VERSION "HIPBNNNYNNNNNNNNNNNNNNNNNNNNNNNNNNYYNNNNNN/4>%%%/4/'%**4NNN///"

NS_ :

BS_:

BU_: ADC CDC DDM VNC Vector_XXX

BO_ 472 ABG1S04: 32 DDM
 SG_ SCSVNR : 19|2@0+ (1,0) [0|0] "-"  CDC
 SG_ VNUSGSCS : 17|1@0+ (1,0) [0|0] "-"  CDC

BO_ 470 ABG1S09: 32 DDM
 SG_ FLGXMAX : 47|8@0- (0.125,0) [0|0] "G"  CDC
 SG_ FLVNMAX : 76|5@0- (0.5,0) [0|0] "m/s"  CDC
 SG_ FRGMAX_L : 87|8@0- (0.2,0) [0|0] "G"  CDC
 SG_ FRGMAX_R : 95|8@0- (0.2,0) [0|0] "G"  CDC
 SG_ PT_ON : 147|2@0+ (1,0) [0|0] "-"  CDC
 SG_ FRAB_ON : 145|2@0+ (1,0) [0|0] "-"  CDC

BO_ 1428 ADC1S06: 32 ADC
 SG_ USMDC1 : 7|8@0+ (5,0) [0|0] "m"  CDC
 SG_ USMDC2 : 15|8@0+ (5,0) [0|0] "m"  CDC
 SG_ USMDC3 : 23|8@0+ (5,0) [0|0] "m"  CDC
 SG_ USMDC5 : 31|8@0+ (5,0) [0|0] "m"  CDC
 SG_ USMDC6 : 39|8@0+ (5,0) [0|0] "m"  CDC
 SG_ USMDRQAC : 47|8@0+ (5,0) [0|0] "m"  CDC
 SG_ USMDC7 : 55|5@0+ (5,0) [0|0] "m"  CDC
 SG_ USMNAV : 50|3@0+ (1,0) [0|0] "-"  CDC

BO_ 497 ADC1S08: 32 ADC
 SG_ HNPAVABL : 7|1@0+ (1,0) [0|0] "-"  CDC
 SG_ UNPAVABL : 6|1@0+ (1,0) [0|0] "-"  CDC
 SG_ FCWAVABL : 4|1@0+ (1,0) [0|0] "-"  CDC
 SG_ ELKAVABL : 3|1@0+ (1,0) [0|0] "-"  CDC
 SG_ CDWAVABL : 2|1@0+ (1,0) [0|0] "-"  CDC
 SG_ SLFAVABL : 1|1@0+ (1,0) [0|0] "-"  CDC
 SG_ TLAAVABL : 0|1@0+ (1,0) [0|0] "-"  CDC
 SG_ ESSAVABL : 15|1@0+ (1,0) [0|0] "-"  CDC
 SG_ CSWAVABL : 14|1@0+ (1,0) [0|0] "-"  CDC
 SG_ AESAVABL : 13|1@0+ (1,0) [0|0] "-"  CDC
 SG_ CPAVABL : 12|1@0+ (1,0) [0|0] "-"  CDC
 SG_ LDKAVABL : 11|1@0+ (1,0) [0|0] "-"  CDC
 SG_ MNPAVABL : 10|1@0+ (1,0) [0|0] "-"  CDC

BO_ 323 ADC1S10: 32 ADC
 SG_ E_CRC143 : 7|16@0+ (1,0) [0|0] "-"  CDC
 SG_ E_CNT143 : 23|8@0+ (1,0) [0|0] "-"  CDC
 SG_ RCTBLV : 31|3@0+ (1,0) [0|0] "-"  CDC
 SG_ RCTBDIR : 28|3@0+ (1,0) [0|0] "-"  CDC
 SG_ AEBDR : 25|3@0+ (1,0) [0|0] "-"  CDC
 SG_ ELKMD : 38|3@0+ (1,0) [0|0] "-"  CDC
 SG_ ESSMD : 35|3@0+ (1,0) [0|0] "-"  CDC
 SG_ ESSDR : 32|3@0+ (1,0) [0|0] "-"  CDC
 SG_ AESST : 45|3@0+ (1,0) [0|0] "-"  CDC
 SG_ AESMD : 42|3@0+ (1,0) [0|0] "-"  CDC
 SG_ AESDR : 55|3@0+ (1,0) [0|0] "-"  CDC
 SG_ HWFNST : 63|16@0+ (1,0) [0|0] "-"  CDC
 SG_ ODDAPWRN : 79|16@0+ (1,0) [0|0] "-"  CDC
 SG_ FCWSTT : 95|3@0+ (1,0) [0|0] "-"  CDC
 SG_ FCWDIR : 92|3@0+ (1,0) [0|0] "-"  CDC
 SG_ FCWWRNMD : 89|6@0+ (1,0) [0|0] "-"  CDC
 SG_ RCTADIR : 99|3@0+ (1,0) [0|0] "-"  CDC
 SG_ CDWSTT : 96|3@0+ (1,0) [0|0] "-"  CDC
 SG_ CDWLV : 109|2@0+ (1,0) [0|0] "-"  CDC
 SG_ CDWWRN : 107|2@0+ (1,0) [0|0] "-"  CDC
 SG_ AESDIR : 105|3@0+ (1,0) [0|0] "-"  CDC
 SG_ RCPMSTT : 112|3@0+ (1,0) [0|0] "-"  CDC
 SG_ ESSSTT : 125|3@0+ (1,0) [0|0] "-"  CDC
 SG_ RCTASTT : 122|3@0+ (1,0) [0|0] "-"  CDC
 SG_ RCTBSTT : 135|3@0+ (1,0) [0|0] "-"  CDC
 SG_ LDWSTT : 132|3@0+ (1,0) [0|0] "-"  CDC
 SG_ LDKSTT : 129|3@0+ (1,0) [0|0] "-"  CDC
 SG_ ELKSTT : 142|3@0+ (1,0) [0|0] "-"  CDC
 SG_ TSRSTT : 139|3@0+ (1,0) [0|0] "-"  CDC
 SG_ IHCSTT : 136|3@0+ (1,0) [0|0] "-"  CDC
 SG_ BSDSTT : 149|3@0+ (1,0) [0|0] "-"  CDC
 SG_ LCASTT : 146|3@0+ (1,0) [0|0] "-"  CDC
 SG_ DOWSTT : 159|3@0+ (1,0) [0|0] "-"  CDC
 SG_ AEBSTT : 156|3@0+ (1,0) [0|0] "-"  CDC
 SG_ ABSMSTT : 153|3@0+ (1,0) [0|0] "-"  CDC
 SG_ AESSTT : 166|3@0+ (1,0) [0|0] "-"  CDC
 SG_ RCWSTT : 163|3@0+ (1,0) [0|0] "-"  CDC
 SG_ CSWSTT : 160|3@0+ (1,0) [0|0] "-"  CDC
 SG_ SLFSTT : 173|3@0+ (1,0) [0|0] "-"  CDC
 SG_ TLASTT : 170|9@0+ (1,0) [0|0] "-"  CDC
 SG_ LPAPFAIL : 177|1@0+ (1,0) [0|0] "-"  CDC
 SG_ LPNPFAIL : 187|1@0+ (1,0) [0|0] "-"  CDC
 SG_ LPNPSYS : 186|1@0+ (1,0) [0|0] "-"  CDC
 SG_ LPNPONST : 185|1@0+ (1,0) [0|0] "-"  CDC
 SG_ PNPEXBRK : 184|1@0+ (1,0) [0|0] "-"  CDC
 SG_ PNPFAIL : 194|1@0+ (1,0) [0|0] "-"  CDC
 SG_ PNPSYS : 193|1@0+ (1,0) [0|0] "-"  CDC
 SG_ PNPONST : 192|1@0+ (1,0) [0|0] "-"  CDC
 SG_ APPONST : 207|1@0+ (1,0) [0|0] "-"  CDC
 SG_ AP_LAMP : 206|2@0+ (1,0) [0|0] "-"  CDC
 SG_ DMCCALB : 204|2@0+ (1,0) [0|0] "-"  CDC
 SG_ LPNPEXBK : 202|1@0+ (1,0) [0|0] "-"  CDC
 SG_ LPNPLAMP : 201|2@0+ (1,0) [0|0] "-"  CDC
 SG_ LPNPSTS : 215|8@0+ (1,0) [0|0] "-"  CDC
 SG_ PNPSTS : 223|8@0+ (1,0) [0|0] "-"  CDC

BO_ 515 ADC1S12: 32 ADC
 SG_ GDNEXIST : 7|1@0+ (1,0) [0|0] "-"  CDC
 SG_ CNPFNEX : 4|1@0+ (1,0) [0|0] "-"  CDC
 SG_ FCWFNEX : 3|1@0+ (1,0) [0|0] "-"  CDC
 SG_ ELKFNEX : 2|1@0+ (1,0) [0|0] "-"  CDC
 SG_ SLFFNEX : 1|1@0+ (1,0) [0|0] "-"  CDC
 SG_ TLAFNEX : 0|1@0+ (1,0) [0|0] "-"  CDC
 SG_ BSDFNEX : 15|1@0+ (1,0) [0|0] "-"  CDC
 SG_ ESSFNEX : 14|1@0+ (1,0) [0|0] "-"  CDC
 SG_ CSWFNEX : 13|1@0+ (1,0) [0|0] "-"  CDC
 SG_ AESFNEX : 12|1@0+ (1,0) [0|0] "-"  CDC
 SG_ LDKFNEX : 11|1@0+ (1,0) [0|0] "-"  CDC
 SG_ CPFNEX : 10|1@0+ (1,0) [0|0] "-"  CDC
 SG_ CDWFNEX : 8|1@0+ (1,0) [0|0] "-"  CDC

BO_ 520 ADC1S14: 32 ADC
 SG_ E_CRC208 : 7|16@0+ (1,0) [0|0] "-"  CDC,DDM
 SG_ E_CNT208 : 23|8@0+ (1,0) [0|0] "-"  CDC,DDM
 SG_ ADBZRQ : 31|8@0+ (1,0) [0|0] "-"  CDC,DDM
 SG_ ADPRDTML : 39|1@0+ (1,0) [0|0] "-"  CDC,DDM
 SG_ ADMMMUTE : 38|1@0+ (1,0) [0|0] "-"  CDC,DDM
 SG_ ADADDREX : 37|1@0+ (1,0) [0|0] "-"  CDC,DDM
 SG_ ADOTASEX : 36|1@0+ (1,0) [0|0] "-"  CDC,DDM
 SG_ ADSTMUEX : 35|1@0+ (1,0) [0|0] "-"  CDC,DDM
 SG_ ADAUNFEX : 34|1@0+ (1,0) [0|0] "-"  CDC,DDM
 SG_ ADNTLVEX : 33|1@0+ (1,0) [0|0] "-"  CDC,DDM
 SG_ ADDSLVEX : 32|1@0+ (1,0) [0|0] "-"  CDC,DDM
 SG_ ADVOCTEX : 47|1@0+ (1,0) [0|0] "-"  CDC,DDM
 SG_ ADSLDSEX : 46|1@0+ (1,0) [0|0] "-"  CDC,DDM
 SG_ ADDMCREX : 45|1@0+ (1,0) [0|0] "-"  CDC,DDM
 SG_ ADSEGDEX : 44|2@0+ (1,0) [0|0] "-"  CDC,DDM
 SG_ ADSVSSEX : 41|1@0+ (1,0) [0|0] "-"  CDC,DDM
 SG_ ADCVVSEX : 40|1@0+ (1,0) [0|0] "-"  CDC,DDM
 SG_ ADADDRST : 53|2@0+ (1,0) [0|0] "-"  CDC,DDM
 SG_ ADOTASST : 51|2@0+ (1,0) [0|0] "-"  CDC,DDM
 SG_ ADSTMUST : 49|2@0+ (1,0) [0|0] "-"  CDC,DDM
 SG_ ADAUNFST : 63|2@0+ (1,0) [0|0] "-"  CDC,DDM
 SG_ ADNTLVST : 61|2@0+ (1,0) [0|0] "-"  CDC,DDM
 SG_ ADDSLVST : 59|2@0+ (1,0) [0|0] "-"  CDC,DDM
 SG_ ADVOCTST : 57|2@0+ (1,0) [0|0] "-"  CDC,DDM
 SG_ ADSLDSST : 71|2@0+ (1,0) [0|0] "-"  CDC,DDM
 SG_ ADDMCRST : 69|2@0+ (1,0) [0|0] "-"  CDC,DDM
 SG_ ADSEGDST : 67|2@0+ (1,0) [0|0] "-"  CDC,DDM
 SG_ ADSVSSST : 78|2@0+ (1,0) [0|0] "-"  CDC,DDM
 SG_ ADCVVSST : 76|4@0+ (1,0) [0|0] "-"  CDC,DDM
 SG_ ADDOTTT : 82|2@0+ (1,0) [0|0] "-"  CDC,DDM
 SG_ ADHOFEXT : 80|1@0+ (1,0) [0|0] "-"  CDC,DDM
 SG_ ADDOTRQ : 95|3@0+ (1,0) [0|0] "-"  CDC,DDM
 SG_ ADHONRQ : 92|3@0+ (1,0) [0|0] "-"  CDC,DDM
 SG_ ADADMTT : 89|3@0+ (1,0) [0|0] "-"  CDC,DDM
 SG_ ADHOFDSP : 102|3@0+ (1,0) [0|0] "-"  CDC,DDM
 SG_ ADTRJDSP : 99|3@0+ (1,0) [0|0] "-"  CDC,DDM
 SG_ ADLLIDSP : 96|3@0+ (1,0) [0|0] "-"  CDC,DDM
 SG_ ADRLIDSP : 109|3@0+ (1,0) [0|0] "-"  CDC,DDM
 SG_ MNPCUSST : 131|2@0+ (1,0) [0|0] "-"  CDC,DDM
 SG_ RCD_DE_C : 128|1@0+ (1,0) [0|0] "-"  CDC,DDM
 SG_ RCDDE_ST : 143|1@0+ (1,0) [0|0] "-"  CDC,DDM
 SG_ FR_BRGHT : 142|1@0+ (1,0) [0|0] "-"  CDC,DDM
 SG_ FR_DIRT2 : 141|1@0+ (1,0) [0|0] "-"  CDC,DDM
 SG_ FR_SNOW : 140|1@0+ (1,0) [0|0] "-"  CDC,DDM
 SG_ FR_RAIN : 139|1@0+ (1,0) [0|0] "-"  CDC,DDM
 SG_ FR_INVA : 138|1@0+ (1,0) [0|0] "-"  CDC,DDM
 SG_ FR_FAIL : 137|1@0+ (1,0) [0|0] "-"  CDC,DDM
 SG_ RR_BRGHT : 136|1@0+ (1,0) [0|0] "-"  CDC,DDM
 SG_ RR_DIRT2 : 151|1@0+ (1,0) [0|0] "-"  CDC,DDM
 SG_ RR_SNOW : 150|1@0+ (1,0) [0|0] "-"  CDC,DDM
 SG_ RR_RAIN : 149|1@0+ (1,0) [0|0] "-"  CDC,DDM
 SG_ RR_INVA : 148|1@0+ (1,0) [0|0] "-"  CDC,DDM
 SG_ RR_FAIL : 147|1@0+ (1,0) [0|0] "-"  CDC,DDM
 SG_ LH_BRGHT : 146|1@0+ (1,0) [0|0] "-"  CDC,DDM
 SG_ LH_DIRT : 145|1@0+ (1,0) [0|0] "-"  CDC,DDM
 SG_ LH_SNOW : 144|1@0+ (1,0) [0|0] "-"  CDC,DDM
 SG_ LH_RAIN : 159|1@0+ (1,0) [0|0] "-"  CDC,DDM
 SG_ LH_INVA : 158|1@0+ (1,0) [0|0] "-"  CDC,DDM
 SG_ LH_FAIL : 157|1@0+ (1,0) [0|0] "-"  CDC,DDM
 SG_ RH_BRGHT : 156|1@0+ (1,0) [0|0] "-"  CDC,DDM
 SG_ RH_DIRT : 155|1@0+ (1,0) [0|0] "-"  CDC,DDM
 SG_ RH_SNOW : 154|1@0+ (1,0) [0|0] "-"  CDC,DDM
 SG_ RH_RAIN : 153|1@0+ (1,0) [0|0] "-"  CDC,DDM
 SG_ RH_INVA : 152|1@0+ (1,0) [0|0] "-"  CDC,DDM
 SG_ RH_FAIL : 167|1@0+ (1,0) [0|0] "-"  CDC,DDM
 SG_ AIPWFR1 : 175|8@0+ (1,0) [0|0] "-"  CDC,DDM
 SG_ AIPWFR2 : 183|8@0+ (1,0) [0|0] "-"  CDC,DDM
 SG_ AIPREQ : 191|8@0+ (1,0) [0|0] "-"  CDC,DDM
 SG_ AIPRLAR : 199|1@0+ (1,0) [0|0] "-"  CDC,DDM
 SG_ AIPPROEX : 198|1@0+ (1,0) [0|0] "-"  CDC,DDM
 SG_ AIPPRORE : 197|5@0+ (1,0) [0|0] "-"  CDC,DDM

BO_ 521 ADC1S15: 32 ADC
 SG_ FCWCUSST : 7|2@0+ (1,0) [0|0] "-"  CDC
 SG_ CDWCUSST : 5|2@0+ (1,0) [0|0] "-"  CDC
 SG_ SLFCUSST : 3|2@0+ (1,0) [0|0] "-"  CDC
 SG_ TLACUSST : 1|2@0+ (1,0) [0|0] "-"  CDC
 SG_ BSDCUSST : 15|2@0+ (1,0) [0|0] "-"  CDC
 SG_ ESSCUSST : 13|2@0+ (1,0) [0|0] "-"  CDC
 SG_ CSWCUSST : 11|2@0+ (1,0) [0|0] "-"  CDC
 SG_ AESCUSST : 9|2@0+ (1,0) [0|0] "-"  CDC
 SG_ HNPCUSST : 23|2@0+ (1,0) [0|0] "-"  CDC
 SG_ UNPCUSST : 21|2@0+ (1,0) [0|0] "-"  CDC
 SG_ LDKCUSST : 17|2@0+ (1,0) [0|0] "-"  CDC
 SG_ ELKCUSST : 31|2@0+ (1,0) [0|0] "-"  CDC
 SG_ CPCUSST : 29|2@0+ (1,0) [0|0] "-"  CDC
 SG_ HNPCSTEX : 27|1@0+ (1,0) [0|0] "-"  CDC
 SG_ UNPCSTEX : 26|1@0+ (1,0) [0|0] "-"  CDC
 SG_ NPLCCSEX : 24|1@0+ (1,0) [0|0] "-"  CDC
 SG_ NPCS1EX : 39|1@0+ (1,0) [0|0] "-"  CDC
 SG_ NPCS2EX : 38|1@0+ (1,0) [0|0] "-"  CDC
 SG_ NPCS3EX : 37|1@0+ (1,0) [0|0] "-"  CDC
 SG_ NPCS4EX : 36|1@0+ (1,0) [0|0] "-"  CDC
 SG_ NPCS5EX : 35|1@0+ (1,0) [0|0] "-"  CDC
 SG_ NPCS6EX : 34|1@0+ (1,0) [0|0] "-"  CDC
 SG_ NPCS7EX : 33|1@0+ (1,0) [0|0] "-"  CDC
 SG_ NPCS8EX : 32|1@0+ (1,0) [0|0] "-"  CDC
 SG_ NPCS9EX : 47|1@0+ (1,0) [0|0] "-"  CDC
 SG_ NPCS10EX : 46|1@0+ (1,0) [0|0] "-"  CDC
 SG_ NPCS11EX : 45|1@0+ (1,0) [0|0] "-"  CDC
 SG_ NPCS12EX : 44|1@0+ (1,0) [0|0] "-"  CDC
 SG_ NPCS13EX : 43|1@0+ (1,0) [0|0] "-"  CDC
 SG_ NPCS14EX : 42|1@0+ (1,0) [0|0] "-"  CDC
 SG_ NPCS15EX : 41|1@0+ (1,0) [0|0] "-"  CDC
 SG_ NPCS16EX : 40|1@0+ (1,0) [0|0] "-"  CDC
 SG_ NPCS17EX : 55|1@0+ (1,0) [0|0] "-"  CDC
 SG_ NPCS18EX : 54|1@0+ (1,0) [0|0] "-"  CDC
 SG_ NPCS19EX : 53|1@0+ (1,0) [0|0] "-"  CDC
 SG_ NPCS20EX : 52|1@0+ (1,0) [0|0] "-"  CDC
 SG_ HNPCSST : 51|2@0+ (1,0) [0|0] "-"  CDC
 SG_ UNPCSST : 49|2@0+ (1,0) [0|0] "-"  CDC
 SG_ NPLCCSST : 61|2@0+ (1,0) [0|0] "-"  CDC
 SG_ NPCS1ST : 59|3@0+ (1,0) [0|0] "-"  CDC
 SG_ NPCS2ST : 56|2@0+ (1,0) [0|0] "-"  CDC
 SG_ NPCS3ST : 70|2@0+ (1,0) [0|0] "-"  CDC
 SG_ NPCS4ST : 68|2@0+ (1,0) [0|0] "-"  CDC
 SG_ NPCS5ST : 66|2@0+ (1,0) [0|0] "-"  CDC
 SG_ NPCS6ST : 64|2@0+ (1,0) [0|0] "-"  CDC
 SG_ NPCS7ST : 78|3@0+ (1,0) [0|0] "-"  CDC
 SG_ NPCS8ST : 75|5@0+ (1,0) [0|0] "-"  CDC
 SG_ NPCS9ST : 86|2@0+ (1,0) [0|0] "-"  CDC
 SG_ NPCS10ST : 84|3@0+ (1,0) [0|0] "-"  CDC
 SG_ NPCS11ST : 81|3@0+ (1,0) [0|0] "-"  CDC
 SG_ NPCS12ST : 94|2@0+ (1,0) [0|0] "-"  CDC
 SG_ NPCS13ST : 92|2@0+ (1,0) [0|0] "-"  CDC
 SG_ NPCS14ST : 90|2@0+ (1,0) [0|0] "-"  CDC
 SG_ NPCS15ST : 88|2@0+ (1,0) [0|0] "-"  CDC
 SG_ NPCS16ST : 102|2@0+ (1,0) [0|0] "-"  CDC
 SG_ NPCS17ST : 100|2@0+ (1,0) [0|0] "-"  CDC
 SG_ NPCS18ST : 98|2@0+ (1,0) [0|0] "-"  CDC
 SG_ NPCS19ST : 96|3@0+ (1,0) [0|0] "-"  CDC
 SG_ NPCS20ST : 109|3@0+ (1,0) [0|0] "-"  CDC
 SG_ GDNCTEX : 106|1@0+ (1,0) [0|0] "-"  CDC
 SG_ GDNCTST : 105|2@0+ (1,0) [0|0] "-"  CDC
 SG_ GDNWNEX : 119|1@0+ (1,0) [0|0] "-"  CDC
 SG_ GDNWNST : 118|2@0+ (1,0) [0|0] "-"  CDC
 SG_ GDNBKEX : 116|1@0+ (1,0) [0|0] "-"  CDC
 SG_ GDNBKST : 115|2@0+ (1,0) [0|0] "-"  CDC
 SG_ GDNSTEX : 113|1@0+ (1,0) [0|0] "-"  CDC
 SG_ GDNSTST : 112|2@0+ (1,0) [0|0] "-"  CDC
 SG_ GDNSNEX : 126|1@0+ (1,0) [0|0] "-"  CDC
 SG_ GDNSNST : 125|3@0+ (1,0) [0|0] "-"  CDC
 SG_ FCWCTEX : 122|1@0+ (1,0) [0|0] "-"  CDC
 SG_ FCWCTST : 121|2@0+ (1,0) [0|0] "-"  CDC
 SG_ FCWSEEX : 135|1@0+ (1,0) [0|0] "-"  CDC
 SG_ FCWSEST : 134|3@0+ (1,0) [0|0] "-"  CDC
 SG_ CDWCTEX : 131|1@0+ (1,0) [0|0] "-"  CDC
 SG_ CDWCTST : 130|2@0+ (1,0) [0|0] "-"  CDC
 SG_ TLACTEX : 128|1@0+ (1,0) [0|0] "-"  CDC
 SG_ TLACTST : 143|2@0+ (1,0) [0|0] "-"  CDC
 SG_ SLFCTEX : 141|1@0+ (1,0) [0|0] "-"  CDC
 SG_ SLFCTST : 140|2@0+ (1,0) [0|0] "-"  CDC
 SG_ CSWCTEX : 138|1@0+ (1,0) [0|0] "-"  CDC
 SG_ CSWCTST : 137|2@0+ (1,0) [0|0] "-"  CDC
 SG_ AESCTEX : 151|1@0+ (1,0) [0|0] "-"  CDC
 SG_ AESCTST : 150|2@0+ (1,0) [0|0] "-"  CDC
 SG_ ACCCTEX : 148|1@0+ (1,0) [0|0] "-"  CDC
 SG_ ACCCTST : 147|2@0+ (1,0) [0|0] "-"  CDC
 SG_ CPCTEX : 145|1@0+ (1,0) [0|0] "-"  CDC
 SG_ CPCTST : 144|2@0+ (1,0) [0|0] "-"  CDC
 SG_ LDKCTEX : 158|1@0+ (1,0) [0|0] "-"  CDC
 SG_ LDKCTST : 157|2@0+ (1,0) [0|0] "-"  CDC
 SG_ LDKSNEX : 155|1@0+ (1,0) [0|0] "-"  CDC
 SG_ LDKSNST : 154|2@0+ (1,0) [0|0] "-"  CDC
 SG_ ELKCTEX : 152|1@0+ (1,0) [0|0] "-"  CDC
 SG_ ELKCTST : 167|2@0+ (1,0) [0|0] "-"  CDC
 SG_ ELKMDEX : 165|1@0+ (1,0) [0|0] "-"  CDC
 SG_ ELKMDST : 164|3@0+ (1,0) [0|0] "-"  CDC
 SG_ BSDCTEX : 161|1@0+ (1,0) [0|0] "-"  CDC
 SG_ BSDCTST : 160|2@0+ (1,0) [0|0] "-"  CDC
 SG_ NPSSWEX : 190|1@0+ (1,0) [0|0] "-"  CDC
 SG_ NPSSWST : 189|1@0+ (1,0) [0|0] "-"  CDC
 SG_ RCPMCTEX : 188|1@0+ (1,0) [0|0] "-"  CDC
 SG_ RCPMCTST : 187|2@0+ (1,0) [0|0] "-"  CDC
 SG_ NPDSSWEX : 185|1@0+ (1,0) [0|0] "-"  CDC
 SG_ NPDSSWST : 184|1@0+ (1,0) [0|0] "-"  CDC
 SG_ ESSCTEX : 196|1@0+ (1,0) [0|0] "-"  CDC
 SG_ ESSCTST : 195|2@0+ (1,0) [0|0] "-"  CDC
 SG_ OVSPCEXT : 193|1@0+ (1,0) [0|0] "-"  CDC
 SG_ OVSPCVAL : 192|5@0+ (1,0) [0|0] "-"  CDC
 SG_ CRNGCUST : 202|2@0+ (1,0) [0|0] "-"  CDC
 SG_ CSRNGF : 215|1@0+ (1,0) [0|0] "-"  CDC
 SG_ CSRNGR : 213|1@0+ (1,0) [0|0] "-"  CDC
 SG_ WDISPCST : 211|1@0+ (1,0) [0|0] "-"  CDC
 SG_ WDISPSTT : 209|1@0+ (1,0) [0|0] "-"  CDC
 SG_ MOACUST : 223|1@0+ (1,0) [0|0] "-"  CDC
 SG_ MOASTAT : 221|1@0+ (1,0) [0|0] "-"  CDC
 SG_ MOAAOST : 219|1@0+ (1,0) [0|0] "-"  CDC
 SG_ MNPCSTEX : 218|1@0+ (1,0) [0|0] "-"  CDC
 SG_ MNPFNEX : 217|2@0+ (1,0) [0|0] "-"  CDC
 SG_ MNPSSWEX : 231|1@0+ (1,0) [0|0] "-"  CDC
 SG_ MNPSSWST : 230|1@0+ (1,0) [0|0] "-"  CDC
 SG_ HNPFNEX : 229|1@0+ (1,0) [0|0] "-"  CDC
 SG_ UNPFNEX : 228|1@0+ (1,0) [0|0] "-"  CDC

BO_ 384 ADC1S16: 32 ADC
 SG_ CSRRDRW : 7|1@0+ (1,0) [0|0] "-"  CDC
 SG_ CSRCICON : 14|3@0+ (1,0) [0|0] "-"  CDC
 SG_ WDSP_FLS : 11|4@0- (1,0) [0|0] "-"  CDC
 SG_ WDSP_FL : 23|4@0- (1,0) [0|0] "-"  CDC
 SG_ WDSP_FLC : 19|4@0- (1,0) [0|0] "-"  CDC
 SG_ WDSP_FRS : 31|4@0- (1,0) [0|0] "-"  CDC
 SG_ WDSP_FR : 27|4@0- (1,0) [0|0] "-"  CDC
 SG_ WDSP_FRC : 39|4@0- (1,0) [0|0] "-"  CDC
 SG_ WDSP_RLS : 35|4@0- (1,0) [0|0] "-"  CDC
 SG_ WDSP_RL : 47|4@0- (1,0) [0|0] "-"  CDC
 SG_ WDSP_RLC : 43|4@0- (1,0) [0|0] "-"  CDC
 SG_ WDSP_RRS : 55|4@0- (1,0) [0|0] "-"  CDC
 SG_ WDSP_RR : 51|4@0- (1,0) [0|0] "-"  CDC
 SG_ WDSP_RRC : 63|4@0- (1,0) [0|0] "-"  CDC
 SG_ WDSP_RS1 : 59|4@0- (1,0) [0|0] "-"  CDC
 SG_ WDSP_RS2 : 71|4@0- (1,0) [0|0] "-"  CDC
 SG_ WDSP_RS3 : 67|4@0- (1,0) [0|0] "-"  CDC
 SG_ WDSP_RS4 : 79|4@0- (1,0) [0|0] "-"  CDC
 SG_ WDSP_RS5 : 75|4@0- (1,0) [0|0] "-"  CDC
 SG_ WDSP_RS6 : 87|4@0- (1,0) [0|0] "-"  CDC
 SG_ WDSP_RS7 : 83|4@0- (1,0) [0|0] "-"  CDC
 SG_ WDSP_RS8 : 95|4@0- (1,0) [0|0] "-"  CDC
 SG_ WDSP_LS1 : 91|4@0- (1,0) [0|0] "-"  CDC
 SG_ WDSP_LS2 : 103|4@0- (1,0) [0|0] "-"  CDC
 SG_ WDSP_LS3 : 99|4@0- (1,0) [0|0] "-"  CDC
 SG_ WDSP_LS4 : 111|4@0- (1,0) [0|0] "-"  CDC
 SG_ WDSP_LS5 : 107|4@0- (1,0) [0|0] "-"  CDC
 SG_ WDSP_LS6 : 119|4@0- (1,0) [0|0] "-"  CDC
 SG_ WDSP_LS7 : 115|4@0- (1,0) [0|0] "-"  CDC
 SG_ WDSP_LS8 : 127|4@0- (1,0) [0|0] "-"  CDC
 SG_ WCOL_FLS : 123|2@0- (1,3) [0|0] "-"  CDC
 SG_ WCOL_FL : 121|2@0- (1,3) [0|0] "-"  CDC
 SG_ WCOL_FLC : 135|2@0- (1,3) [0|0] "-"  CDC
 SG_ WCOL_FRS : 133|2@0- (1,3) [0|0] "-"  CDC
 SG_ WCOL_FR : 131|2@0- (1,3) [0|0] "-"  CDC
 SG_ WCOL_FRC : 129|2@0- (1,3) [0|0] "-"  CDC
 SG_ WCOL_RLS : 143|2@0- (1,3) [0|0] "-"  CDC
 SG_ WCOL_RL : 141|2@0- (1,3) [0|0] "-"  CDC
 SG_ WCOL_RLC : 139|2@0- (1,3) [0|0] "-"  CDC
 SG_ WCOL_RRS : 137|2@0- (1,3) [0|0] "-"  CDC
 SG_ WCOL_RR : 151|2@0- (1,3) [0|0] "-"  CDC
 SG_ WCOL_RRC : 149|2@0- (1,3) [0|0] "-"  CDC
 SG_ WCOL_RS1 : 147|2@0- (1,3) [0|0] "-"  CDC
 SG_ WCOL_RS2 : 145|2@0- (1,3) [0|0] "-"  CDC
 SG_ WCOL_RS3 : 159|2@0- (1,3) [0|0] "-"  CDC
 SG_ WCOL_RS4 : 157|2@0- (1,3) [0|0] "-"  CDC
 SG_ WCOL_RS5 : 155|2@0- (1,3) [0|0] "-"  CDC
 SG_ WCOL_RS6 : 153|2@0- (1,3) [0|0] "-"  CDC
 SG_ WCOL_RS7 : 167|2@0- (1,3) [0|0] "-"  CDC
 SG_ WCOL_RS8 : 165|2@0- (1,3) [0|0] "-"  CDC
 SG_ WCOL_LS1 : 163|2@0- (1,3) [0|0] "-"  CDC
 SG_ WCOL_LS2 : 161|2@0- (1,3) [0|0] "-"  CDC
 SG_ WCOL_LS3 : 175|2@0- (1,3) [0|0] "-"  CDC
 SG_ WCOL_LS4 : 173|2@0- (1,3) [0|0] "-"  CDC
 SG_ WCOL_LS5 : 171|2@0- (1,3) [0|0] "-"  CDC
 SG_ WCOL_LS6 : 169|2@0- (1,3) [0|0] "-"  CDC
 SG_ WCOL_LS7 : 183|2@0- (1,3) [0|0] "-"  CDC
 SG_ WCOL_LS8 : 181|2@0- (1,3) [0|0] "-"  CDC
 SG_ DISCSRF : 191|8@0+ (1,0) [0|0] "cm"  CDC
 SG_ DISCSRR : 199|8@0+ (1,0) [0|0] "cm"  CDC
 SG_ CAMERRVI : 207|11@0+ (1,0) [0|0] "-"  CDC
 SG_ CAMERRPO : 212|11@0+ (1,0) [0|0] "-"  CDC

BO_ 522 ADC1S17: 32 ADC
 SG_ LTASSWEX : 7|1@0+ (1,0) [0|0] "-"  CDC,DDM
 SG_ LTASSWST : 6|1@0+ (1,0) [0|0] "-"  CDC,DDM
 SG_ ADINITEX : 5|1@0+ (1,0) [0|0] "-"  CDC,DDM
 SG_ ADSAFEEX : 4|1@0+ (1,0) [0|0] "-"  CDC,DDM
 SG_ ADALOFEX : 3|1@0+ (1,0) [0|0] "-"  CDC,DDM
 SG_ ADMUTEEX : 2|1@0+ (1,0) [0|0] "-"  CDC,DDM
 SG_ ADMDSTEX : 1|1@0+ (1,0) [0|0] "-"  CDC,DDM
 SG_ HMIAMBEX : 0|1@0+ (1,0) [0|0] "-"  CDC,DDM
 SG_ HMIAMBMD : 15|1@0+ (1,0) [0|0] "-"  CDC,DDM
 SG_ R_CROP_1 : 33|4@0+ (1,0) [0|0] "-"  CDC,DDM
 SG_ MD_PRE : 45|1@0+ (1,0) [0|0] "-"  CDC,DDM
 SG_ MD_AVL : 44|4@0+ (1,0) [0|0] "-"  CDC,DDM
 SG_ PVM_SPER : 40|1@0+ (1,0) [0|0] "-"  CDC,DDM
 SG_ ACCCUSST : 55|2@0+ (1,0) [0|0] "-"  CDC,DDM
 SG_ PDACUSST : 53|2@0+ (1,0) [0|0] "-"  CDC,DDM
 SG_ LCACUSST : 51|2@0+ (1,0) [0|0] "-"  CDC,DDM
 SG_ TRACUSST : 49|2@0+ (1,0) [0|0] "-"  CDC,DDM
 SG_ ADCUSST : 63|2@0+ (1,0) [0|0] "-"  CDC,DDM
 SG_ ISACUSST : 61|2@0+ (1,0) [0|0] "-"  CDC,DDM
 SG_ LDACUSST : 59|2@0+ (1,0) [0|0] "-"  CDC,DDM
 SG_ PCSCUSST : 57|2@0+ (1,0) [0|0] "-"  CDC,DDM
 SG_ FTACUSST : 71|2@0+ (1,0) [0|0] "-"  CDC,DDM
 SG_ BSMCUSST : 69|2@0+ (1,0) [0|0] "-"  CDC,DDM
 SG_ SEACUSST : 67|2@0+ (1,0) [0|0] "-"  CDC,DDM
 SG_ CSRCUSST : 65|2@0+ (1,0) [0|0] "-"  CDC,DDM
 SG_ PSBCUSST : 79|2@0+ (1,0) [0|0] "-"  CDC,DDM
 SG_ RTACUSST : 77|2@0+ (1,0) [0|0] "-"  CDC,DDM
 SG_ RCDCUSST : 75|2@0+ (1,0) [0|0] "-"  CDC,DDM
 SG_ SASCUSST : 73|2@0+ (1,0) [0|0] "-"  CDC,DDM
 SG_ RSACUSST : 87|2@0+ (1,0) [0|0] "-"  CDC,DDM
 SG_ RVACUSST : 85|2@0+ (1,0) [0|0] "-"  CDC,DDM
 SG_ AVSCUSST : 83|2@0+ (1,0) [0|0] "-"  CDC,DDM
 SG_ TMNCUSST : 81|2@0+ (1,0) [0|0] "-"  CDC,DDM
 SG_ DMSCUSST : 95|2@0+ (1,0) [0|0] "-"  CDC,DDM
 SG_ SWSCUSST : 93|2@0+ (1,0) [0|0] "-"  CDC,DDM
 SG_ LTACUSST : 91|2@0+ (1,0) [0|0] "-"  CDC,DDM
 SG_ RGSTA : 97|3@0+ (1,0) [0|0] "-"  CDC,DDM
 SG_ LGIDDC : 110|2@0+ (1,0) [0|0] "-"  CDC,DDM
 SG_ TSS_ACCD : 108|5@0+ (0.1,0) [0|0] "m/s^2"  CDC,DDM
 SG_ USMSENST : 115|3@0+ (1,0) [0|0] "-"  CDC,DDM
 SG_ SDGCUSEX : 112|1@0+ (1,0) [0|0] "-"  CDC,DDM
 SG_ SDGSENST : 127|4@0+ (1,0) [0|0] "-"  CDC,DDM
 SG_ DRADCTYP : 123|4@0+ (1,0) [0|0] "-"  CDC,DDM
 SG_ ADVNRQ : 135|7@0+ (1,0) [0|0] "-"  CDC,DDM
 SG_ ADVNUSG : 128|1@0+ (1,0) [0|0] "-"  CDC,DDM
 SG_ HMIAMBRQ : 143|5@0+ (1,0) [0|0] "-"  CDC,DDM
 SG_ USMEXST2 : 138|2@0+ (1,0) [0|0] "-"  CDC,DDM
 SG_ AECOBNFB : 192|6@0+ (1,0) [0|0] "-"  CDC,DDM
 SG_ AECOBNFV : 202|6@0+ (1,0) [0|0] "kWh"  CDC,DDM
 SG_ AECOSTBB : 212|1@0+ (1,0) [0|0] "-"  CDC,DDM
 SG_ ADINITST : 211|1@0+ (1,0) [0|0] "-"  CDC,DDM
 SG_ ADSAFEST : 210|1@0+ (1,0) [0|0] "-"  CDC,DDM
 SG_ ADALOFST : 209|1@0+ (1,0) [0|0] "-"  CDC,DDM
 SG_ ADMUTEST : 208|1@0+ (1,0) [0|0] "-"  CDC,DDM
 SG_ ADMDSTST : 223|1@0+ (1,0) [0|0] "-"  CDC,DDM
 SG_ ADAS_CVI : 231|8@0+ (1,0) [0|0] "-"  CDC,DDM

BO_ 1555 ADC1S19: 32 ADC
 SG_ USMGRN : 7|3@0+ (1,0) [0|0] "-"  CDC
 SG_ USMDISP : 4|1@0+ (1,0) [0|0] "-"  CDC
 SG_ USMMNAV : 3|1@0+ (1,0) [0|0] "-"  CDC
 SG_ USMAC5 : 15|8@0+ (5,0) [0|0] "deg"  CDC
 SG_ USMAC6 : 23|8@0+ (5,0) [0|0] "deg"  CDC
 SG_ USMAC7 : 31|8@0+ (5,0) [0|0] "deg"  CDC
 SG_ USMGSS : 39|8@0+ (0.02,0) [0|0] "G"  CDC
 SG_ USMIDOF : 47|1@0+ (1,0) [0|0] "-"  CDC
 SG_ USMIDST : 46|1@0+ (1,0) [0|0] "-"  CDC
 SG_ USMISTR : 45|1@0+ (1,0) [0|0] "-"  CDC
 SG_ USMSST : 44|1@0+ (1,0) [0|0] "-"  CDC

BO_ 455 ADC1S20: 64 ADC
 SG_ EDADNUM : 7|8@0+ (1,0) [0|0] "-"  CDC
 SG_ EDADID1 : 15|16@0+ (1,0) [0|0] "-"  CDC
 SG_ EDADTS1 : 31|64@0+ (1,0) [0|0] "-"  CDC
 SG_ EDADID2 : 95|16@0+ (1,0) [0|0] "-"  CDC
 SG_ EDADTS2 : 111|64@0+ (1,0) [0|0] "-"  CDC
 SG_ EDADID3 : 175|16@0+ (1,0) [0|0] "-"  CDC
 SG_ EDADTS3 : 191|64@0+ (1,0) [0|0] "-"  CDC
 SG_ EDADID4 : 255|16@0+ (1,0) [0|0] "-"  CDC
 SG_ EDADTS4 : 271|64@0+ (1,0) [0|0] "-"  CDC
 SG_ EDADMID5 : 335|16@0+ (1,0) [0|0] "-"  CDC
 SG_ EDADTS5 : 351|64@0+ (1,0) [0|0] "-"  CDC
 SG_ EDADID6 : 415|16@0+ (1,0) [0|0] "-"  CDC
 SG_ EDADTS6 : 431|64@0+ (1,0) [0|0] "-"  CDC

BO_ 324 ADC1S27: 32 ADC
 SG_ WS_VD_R : 7|2@0+ (1,0) [0|0] "-"  CDC
 SG_ WS_FTG_R : 5|2@0+ (1,0) [0|0] "-"  CDC
 SG_ WS_ABH_R : 3|2@0+ (1,0) [0|0] "-"  CDC
 SG_ WS_APO_R : 1|2@0+ (1,0) [0|0] "-"  CDC

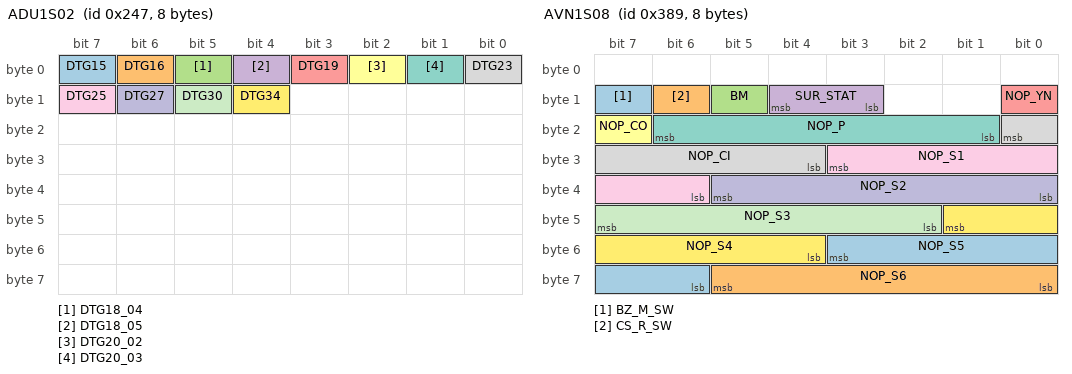
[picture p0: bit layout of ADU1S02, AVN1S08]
BO_ 583 ADU1S02: 8 ADC
 SG_ DTG15 : 7|1@0+ (1,0) [0|0] "-"  CDC
 SG_ DTG16 : 6|1@0+ (1,0) [0|0] "-"  CDC
 SG_ DTG18_04 : 5|1@0+ (1,0) [0|0] "-"  CDC
 SG_ DTG18_05 : 4|1@0+ (1,0) [0|0] "-"  CDC
 SG_ DTG19 : 3|1@0+ (1,0) [0|0] "-"  CDC
 SG_ DTG20_02 : 2|1@0+ (1,0) [0|0] "-"  CDC
 SG_ DTG20_03 : 1|1@0+ (1,0) [0|0] "-"  CDC
 SG_ DTG23 : 0|1@0+ (1,0) [0|0] "-"  CDC
 SG_ DTG25 : 15|1@0+ (1,0) [0|0] "-"  CDC
 SG_ DTG27 : 14|1@0+ (1,0) [0|0] "-"  CDC
 SG_ DTG30 : 13|1@0+ (1,0) [0|0] "-"  CDC
 SG_ DTG34 : 12|1@0+ (1,0) [0|0] "-"  CDC

BO_ 501 ADU1S03: 32 ADC
 SG_ ACCMAPP : 5|4@0+ (1,0) [0|0] "-"  CDC
 SG_ ACCMMOD : 1|2@0+ (1,0) [0|0] "-"  CDC

BO_ 496 ADU1S05: 32 ADC
 SG_ ACCMDST : 7|8@0+ (2,0) [0|0] "m"  CDC
 SG_ ACCMPHS : 15|3@0+ (1,0) [0|0] "-"  CDC
 SG_ ACCMSGN : 12|2@0+ (1,0) [0|0] "-"  CDC
 SG_ ACCMRCG : 10|3@0+ (1,0) [0|0] "-"  CDC
 SG_ ACCMARB : 23|1@0+ (1,0) [0|0] "-"  CDC

BO_ 558 ADU1S06: 32 ADC
 SG_ LDASTATL : 7|8@0+ (1,0) [0|0] "-"  CDC
 SG_ LDASTATR : 15|8@0+ (1,0) [0|0] "-"  CDC
 SG_ LDARSN : 23|8@0+ (1,0) [0|0] "-"  CDC
 SG_ FCMINTMP : 31|5@0+ (2,0) [0|0] "℃"  CDC
 SG_ LDARCGL : 26|4@0+ (1,0) [0|0] "-"  CDC
 SG_ LDARCGR : 38|4@0+ (1,0) [0|0] "-"  CDC
 SG_ SWSSTAT : 34|4@0+ (1,0) [0|0] "-"  CDC
 SG_ V_IDACCL : 46|4@0+ (1,0) [0|0] "-"  CDC
 SG_ EJDEVPRD : 55|8@0+ (1,0) [0|0] "-"  CDC
 SG_ EJLDACP : 63|1@0+ (1,0) [0|0] "-"  CDC
 SG_ V_IDANOA : 62|3@0+ (1,0) [0|0] "-"  CDC
 SG_ V_IDARGL : 59|3@0+ (1,0) [0|0] "-"  CDC
 SG_ PV_AREA : 71|8@0+ (0.04,0) [0|0] "m^2"  CDC
 SG_ DM_PVMVW : 79|16@0+ (1,0) [0|0] "-"  CDC
 SG_ DM_PVMCS : 95|16@0+ (1,0) [0|0] "-"  CDC
 SG_ ERMCNTST : 111|2@0+ (1,0) [0|0] "-"  CDC
 SG_ GAE_H_R3 : 109|7@0+ (0.02,0) [0|0] "deg"  CDC
 SG_ FRDHTR_G : 118|1@0+ (1,0) [0|0] "-"  CDC
 SG_ SDIRT_G : 117|10@0+ (1,0) [0|0] "-"  CDC
 SG_ GAE_V_R1 : 123|4@0+ (1,0) [0|0] "-"  CDC
 SG_ DRTCNT_G : 135|16@0+ (1,0) [0|0] "-"  CDC
 SG_ GAERR1_V : 151|7@0- (0.5,0) [0|0] "deg"  CDC
 SG_ GAEVAL_H : 144|7@0- (0.1,0) [0|0] "deg"  CDC
 SG_ GAERR3_H : 153|7@0- (0.1,0) [0|0] "deg"  CDC
 SG_ DTSSSTR : 207|16@0- (0.001,0) [0|0] "rad"  CDC
 SG_ DTSSLTID : 239|6@0+ (1,0) [0|0] "-"  CDC
 SG_ MDSYNC00 : 233|5@0+ (1,0) [0|0] "-"  CDC

BO_ 353 ADU1S18: 32 ADC
 SG_ MDCTRGID : 6|7@0+ (1,0) [0|0] "-"  CDC
 SG_ CAMTYPE : 10|3@0+ (1,0) [0|0] "-"  CDC
 SG_ CAMPOS_X : 23|16@0- (1,-32768) [0|0] "mm"  CDC
 SG_ CAMPOS_Y : 39|16@0- (1,-32768) [0|0] "mm"  CDC
 SG_ CAMPOS_Z : 55|16@0- (1,-32768) [0|0] "mm"  CDC
 SG_ CAMROT_X : 71|16@0- (0.01,-327.68) [0|0] "deg"  CDC
 SG_ CAMROT_Y : 87|16@0- (0.01,-327.68) [0|0] "deg"  CDC
 SG_ CAMROT_Z : 103|16@0- (0.01,-327.68) [0|0] "deg"  CDC
 SG_ CAMFOC_X : 119|16@0+ (0.1,0) [0|0] "pixel"  CDC
 SG_ CAMFOC_Y : 135|16@0+ (0.1,0) [0|0] "pixel"  CDC
 SG_ CAMDTC_1 : 151|32@0+ (1,0) [0|0] "-"  CDC
 SG_ CAMDTC_2 : 183|32@0+ (1,0) [0|0] "-"  CDC
 SG_ CAMDTC_3 : 215|16@0+ (1,0) [0|0] "-"  CDC
 SG_ CAM_C_X : 231|16@0- (0.1,-3276.8) [0|0] "pixel"  CDC
 SG_ CAM_C_Y : 247|16@0- (0.1,-3276.8) [0|0] "pixel"  CDC

BO_ 354 ADU1S19: 32 ADC
 SG_ MDSYNC01 : 7|5@0+ (1,0) [0|0] "-"  CDC
 SG_ MDVSN01 : 15|8@0+ (1,0) [0|0] "-"  CDC
 SG_ MDVSN02 : 23|8@0+ (1,0) [0|0] "-"  CDC
 SG_ MDVSN03 : 31|8@0+ (1,0) [0|0] "-"  CDC
 SG_ MDVSN04 : 39|8@0+ (1,0) [0|0] "-"  CDC
 SG_ MDVSN05 : 47|8@0+ (1,0) [0|0] "-"  CDC
 SG_ MDVSN06 : 55|8@0+ (1,0) [0|0] "-"  CDC
 SG_ MDVSN07 : 63|8@0+ (1,0) [0|0] "-"  CDC
 SG_ MDVSN08 : 71|8@0+ (1,0) [0|0] "-"  CDC
 SG_ MDVSN09 : 79|8@0+ (1,0) [0|0] "-"  CDC
 SG_ MDVSN10 : 87|8@0+ (1,0) [0|0] "-"  CDC
 SG_ MDVSN11 : 95|8@0+ (1,0) [0|0] "-"  CDC
 SG_ MDVSN12 : 103|8@0+ (1,0) [0|0] "-"  CDC
 SG_ MDVSN13 : 111|8@0+ (1,0) [0|0] "-"  CDC
 SG_ MDVSN14 : 119|8@0+ (1,0) [0|0] "-"  CDC
 SG_ MDVSN15 : 127|8@0+ (1,0) [0|0] "-"  CDC
 SG_ MDVSN16 : 135|8@0+ (1,0) [0|0] "-"  CDC
 SG_ MDVSN17 : 143|8@0+ (1,0) [0|0] "-"  CDC
 SG_ MDVSN18 : 151|8@0+ (1,0) [0|0] "-"  CDC
 SG_ MDVSN19 : 159|8@0+ (1,0) [0|0] "-"  CDC
 SG_ MDVSN20 : 167|8@0+ (1,0) [0|0] "-"  CDC
 SG_ MDVSN21 : 175|8@0+ (1,0) [0|0] "-"  CDC
 SG_ MDVSN22 : 183|8@0+ (1,0) [0|0] "-"  CDC
 SG_ MDVSN23 : 191|8@0+ (1,0) [0|0] "-"  CDC
 SG_ MDVSN24 : 199|8@0+ (1,0) [0|0] "-"  CDC
 SG_ MDVSN25 : 207|8@0+ (1,0) [0|0] "-"  CDC
 SG_ MDVSN26 : 215|8@0+ (1,0) [0|0] "-"  CDC
 SG_ MDVSN27 : 223|8@0+ (1,0) [0|0] "-"  CDC
 SG_ MDVSN28 : 231|8@0+ (1,0) [0|0] "-"  CDC
 SG_ MDVSN29 : 239|8@0+ (1,0) [0|0] "-"  CDC
 SG_ MDVSN30 : 247|8@0+ (1,0) [0|0] "-"  CDC
 SG_ MDVSN31 : 255|8@0+ (1,0) [0|0] "-"  CDC

BO_ 355 ADU1S20: 32 ADC
 SG_ MDSYNC02 : 4|5@0+ (1,0) [0|0] "-"  CDC
 SG_ PV0STROL : 15|16@0+ (1,0) [0|0] "-"  CDC
 SG_ PV0STPIT : 31|16@0+ (1,0) [0|0] "-"  CDC
 SG_ PV0STYAW : 47|16@0+ (1,0) [0|0] "-"  CDC
 SG_ PV1STROL : 63|16@0+ (1,0) [0|0] "-"  CDC
 SG_ PV1STPIT : 79|16@0+ (1,0) [0|0] "-"  CDC
 SG_ PV1STYAW : 95|16@0+ (1,0) [0|0] "-"  CDC
 SG_ PV2STROL : 111|16@0+ (1,0) [0|0] "-"  CDC
 SG_ PV2STPIT : 127|16@0+ (1,0) [0|0] "-"  CDC
 SG_ PV2STYAW : 143|16@0+ (1,0) [0|0] "-"  CDC
 SG_ PV3STROL : 159|16@0+ (1,0) [0|0] "-"  CDC
 SG_ PV3STPIT : 175|16@0+ (1,0) [0|0] "-"  CDC
 SG_ PV3STYAW : 191|16@0+ (1,0) [0|0] "-"  CDC
 SG_ MDCDT187 : 207|8@0+ (1,0) [0|0] "-"  CDC
 SG_ MDCDT188 : 215|8@0+ (1,0) [0|0] "-"  CDC
 SG_ MDCDT189 : 223|8@0+ (1,0) [0|0] "-"  CDC
 SG_ MDCDT190 : 231|8@0+ (1,0) [0|0] "-"  CDC
 SG_ MDCDT191 : 239|8@0+ (1,0) [0|0] "-"  CDC
 SG_ MDCDT192 : 247|8@0+ (1,0) [0|0] "-"  CDC
 SG_ MDCDT193 : 255|8@0+ (1,0) [0|0] "-"  CDC

BO_ 358 ADU1S21: 32 ADC
 SG_ MDSYNC03 : 4|5@0+ (1,0) [0|0] "-"  CDC
 SG_ FCMSTROL : 15|16@0+ (1,0) [0|0] "-"  CDC
 SG_ FCMSTPIT : 31|16@0+ (1,0) [0|0] "-"  CDC
 SG_ FCMSTYAW : 47|16@0+ (1,0) [0|0] "-"  CDC
 SG_ FCMDYROL : 63|16@0+ (1,0) [0|0] "-"  CDC
 SG_ FCMDYPIT : 79|16@0+ (1,0) [0|0] "-"  CDC
 SG_ FCMDYYAW : 95|16@0+ (1,0) [0|0] "-"  CDC
 SG_ PVMDYROL : 111|16@0+ (1,0) [0|0] "-"  CDC
 SG_ PVMDYPIT : 127|16@0+ (1,0) [0|0] "-"  CDC
 SG_ PVMDYYAW : 143|16@0+ (1,0) [0|0] "-"  CDC
 SG_ MDCDT194 : 159|8@0+ (1,0) [0|0] "-"  CDC
 SG_ MDCDT195 : 167|8@0+ (1,0) [0|0] "-"  CDC
 SG_ MDCDT196 : 175|8@0+ (1,0) [0|0] "-"  CDC
 SG_ MDCDT197 : 183|8@0+ (1,0) [0|0] "-"  CDC
 SG_ MDCDT198 : 191|8@0+ (1,0) [0|0] "-"  CDC
 SG_ MDCDT199 : 199|8@0+ (1,0) [0|0] "-"  CDC
 SG_ MDCDT200 : 207|8@0+ (1,0) [0|0] "-"  CDC
 SG_ MDCDT201 : 215|8@0+ (1,0) [0|0] "-"  CDC
 SG_ MDCDT202 : 223|8@0+ (1,0) [0|0] "-"  CDC
 SG_ MDCDT203 : 231|8@0+ (1,0) [0|0] "-"  CDC
 SG_ MDCDT204 : 239|8@0+ (1,0) [0|0] "-"  CDC
 SG_ MDCDT205 : 247|8@0+ (1,0) [0|0] "-"  CDC
 SG_ MDCDT206 : 255|8@0+ (1,0) [0|0] "-"  CDC

BO_ 359 ADU1S22: 32 ADC
 SG_ MDACCDST : 7|3@0+ (1,0) [0|0] "-"  CDC
 SG_ MDSYNC04 : 4|5@0+ (1,0) [0|0] "-"  CDC
 SG_ MDTRPCNT : 15|16@0+ (1,0) [0|0] "-"  CDC
 SG_ MDTMCNT : 31|32@0+ (1,0) [0|0] "-"  CDC
 SG_ MDEGOVEL : 63|16@0- (0.01,-327.68) [0|0] "km/h"  CDC
 SG_ MDEGOGX : 79|16@0- (1,-32768) [0|0] "mG"  CDC
 SG_ MDEGOGY : 95|16@0- (1,-32768) [0|0] "mG"  CDC
 SG_ MDEGOASZ : 111|16@0- (0.01,-327.68) [0|0] "deg/sec"  CDC
 SG_ MDADSST : 127|32@0+ (1,0) [0|0] "-"  CDC
 SG_ MDADSSW : 159|20@0+ (1,0) [0|0] "-"  CDC
 SG_ MDSFTPS : 171|4@0+ (1,0) [0|0] "-"  CDC
 SG_ MDDRVMD : 183|3@0+ (1,0) [0|0] "-"  CDC
 SG_ MDEGOLCS : 180|2@0+ (1,0) [0|0] "-"  CDC
 SG_ MDDRVTSW : 178|3@0+ (1,0) [0|0] "-"  CDC
 SG_ MDACCSPD : 191|8@0+ (1,0) [0|0] "km/h"  CDC
 SG_ MDEGOAOP : 199|8@0+ (1,0) [0|0] "-"  CDC
 SG_ MDEGOBRK : 207|8@0+ (1,0) [0|0] "-"  CDC
 SG_ MDEGOANG : 215|16@0- (0.001,-32.768) [0|0] "rad"  CDC
 SG_ MDDRVACC : 231|8@0+ (1,0) [0|0] "-"  CDC
 SG_ MDDRVBRK : 239|8@0+ (1,0) [0|0] "-"  CDC
 SG_ MDDRVSTR : 247|8@0+ (1,0) [0|0] "-"  CDC
 SG_ MDDRVTCH : 255|2@0+ (1,0) [0|0] "-"  CDC
 SG_ MDTRNL : 253|2@0+ (1,0) [0|0] "-"  CDC
 SG_ MDHZDL : 251|2@0+ (1,0) [0|0] "-"  CDC
 SG_ MDBRKL : 249|2@0+ (1,0) [0|0] "-"  CDC

BO_ 360 ADU1S23: 32 ADC
 SG_ MDSYNC05 : 4|5@0+ (1,0) [0|0] "-"  CDC
 SG_ MDCDT001 : 15|8@0+ (1,0) [0|0] "-"  CDC
 SG_ MDCDT002 : 23|8@0+ (1,0) [0|0] "-"  CDC
 SG_ MDCDT003 : 31|8@0+ (1,0) [0|0] "-"  CDC
 SG_ MDCDT004 : 39|8@0+ (1,0) [0|0] "-"  CDC
 SG_ MDCDT005 : 47|8@0+ (1,0) [0|0] "-"  CDC
 SG_ MDCDT006 : 55|8@0+ (1,0) [0|0] "-"  CDC
 SG_ MDCDT007 : 63|8@0+ (1,0) [0|0] "-"  CDC
 SG_ MDCDT008 : 71|8@0+ (1,0) [0|0] "-"  CDC
 SG_ MDCDT009 : 79|8@0+ (1,0) [0|0] "-"  CDC
 SG_ MDCDT010 : 87|8@0+ (1,0) [0|0] "-"  CDC
 SG_ MDCDT011 : 95|8@0+ (1,0) [0|0] "-"  CDC
 SG_ MDCDT012 : 103|8@0+ (1,0) [0|0] "-"  CDC
 SG_ MDCDT013 : 111|8@0+ (1,0) [0|0] "-"  CDC
 SG_ MDCDT014 : 119|8@0+ (1,0) [0|0] "-"  CDC
 SG_ MDCDT015 : 127|8@0+ (1,0) [0|0] "-"  CDC
 SG_ MDCDT016 : 135|8@0+ (1,0) [0|0] "-"  CDC
 SG_ MDCDT017 : 143|8@0+ (1,0) [0|0] "-"  CDC
 SG_ MDCDT018 : 151|8@0+ (1,0) [0|0] "-"  CDC
 SG_ MDCDT019 : 159|8@0+ (1,0) [0|0] "-"  CDC
 SG_ MDCDT020 : 167|8@0+ (1,0) [0|0] "-"  CDC
 SG_ MDCDT021 : 175|8@0+ (1,0) [0|0] "-"  CDC
 SG_ MDCDT022 : 183|8@0+ (1,0) [0|0] "-"  CDC
 SG_ MDCDT023 : 191|8@0+ (1,0) [0|0] "-"  CDC
 SG_ MDCDT024 : 199|8@0+ (1,0) [0|0] "-"  CDC
 SG_ MDCDT025 : 207|8@0+ (1,0) [0|0] "-"  CDC
 SG_ MDCDT026 : 215|8@0+ (1,0) [0|0] "-"  CDC
 SG_ MDCDT027 : 223|8@0+ (1,0) [0|0] "-"  CDC
 SG_ MDCDT028 : 231|8@0+ (1,0) [0|0] "-"  CDC
 SG_ MDCDT029 : 239|8@0+ (1,0) [0|0] "-"  CDC
 SG_ MDCDT030 : 247|8@0+ (1,0) [0|0] "-"  CDC
 SG_ MDCDT031 : 255|8@0+ (1,0) [0|0] "-"  CDC

BO_ 361 ADU1S24: 32 ADC
 SG_ MDSYNC06 : 4|5@0+ (1,0) [0|0] "-"  CDC
 SG_ MDCDT032 : 15|8@0+ (1,0) [0|0] "-"  CDC
 SG_ MDCDT033 : 23|8@0+ (1,0) [0|0] "-"  CDC
 SG_ MDCDT034 : 31|8@0+ (1,0) [0|0] "-"  CDC
 SG_ MDCDT035 : 39|8@0+ (1,0) [0|0] "-"  CDC
 SG_ MDCDT036 : 47|8@0+ (1,0) [0|0] "-"  CDC
 SG_ MDCDT037 : 55|8@0+ (1,0) [0|0] "-"  CDC
 SG_ MDCDT038 : 63|8@0+ (1,0) [0|0] "-"  CDC
 SG_ MDCDT039 : 71|8@0+ (1,0) [0|0] "-"  CDC
 SG_ MDCDT040 : 79|8@0+ (1,0) [0|0] "-"  CDC
 SG_ MDCDT041 : 87|8@0+ (1,0) [0|0] "-"  CDC
 SG_ MDCDT042 : 95|8@0+ (1,0) [0|0] "-"  CDC
 SG_ MDCDT043 : 103|8@0+ (1,0) [0|0] "-"  CDC
 SG_ MDCDT044 : 111|8@0+ (1,0) [0|0] "-"  CDC
 SG_ MDCDT045 : 119|8@0+ (1,0) [0|0] "-"  CDC
 SG_ MDCDT046 : 127|8@0+ (1,0) [0|0] "-"  CDC
 SG_ MDCDT047 : 135|8@0+ (1,0) [0|0] "-"  CDC
 SG_ MDCDT048 : 143|8@0+ (1,0) [0|0] "-"  CDC
 SG_ MDCDT049 : 151|8@0+ (1,0) [0|0] "-"  CDC
 SG_ MDCDT050 : 159|8@0+ (1,0) [0|0] "-"  CDC
 SG_ MDCDT051 : 167|8@0+ (1,0) [0|0] "-"  CDC
 SG_ MDCDT052 : 175|8@0+ (1,0) [0|0] "-"  CDC
 SG_ MDCDT053 : 183|8@0+ (1,0) [0|0] "-"  CDC
 SG_ MDCDT054 : 191|8@0+ (1,0) [0|0] "-"  CDC
 SG_ MDCDT055 : 199|8@0+ (1,0) [0|0] "-"  CDC
 SG_ MDCDT056 : 207|8@0+ (1,0) [0|0] "-"  CDC
 SG_ MDCDT057 : 215|8@0+ (1,0) [0|0] "-"  CDC
 SG_ MDCDT058 : 223|8@0+ (1,0) [0|0] "-"  CDC
 SG_ MDCDT059 : 231|8@0+ (1,0) [0|0] "-"  CDC
 SG_ MDCDT060 : 239|8@0+ (1,0) [0|0] "-"  CDC
 SG_ MDCDT061 : 247|8@0+ (1,0) [0|0] "-"  CDC
 SG_ MDCDT062 : 255|8@0+ (1,0) [0|0] "-"  CDC

BO_ 362 ADU1S25: 32 ADC
 SG_ MDSYNC07 : 4|5@0+ (1,0) [0|0] "-"  CDC
 SG_ MDCDT063 : 15|8@0+ (1,0) [0|0] "-"  CDC
 SG_ MDCDT064 : 23|8@0+ (1,0) [0|0] "-"  CDC
 SG_ MDCDT065 : 31|8@0+ (1,0) [0|0] "-"  CDC
 SG_ MDCDT066 : 39|8@0+ (1,0) [0|0] "-"  CDC
 SG_ MDCDT067 : 47|8@0+ (1,0) [0|0] "-"  CDC
 SG_ MDCDT068 : 55|8@0+ (1,0) [0|0] "-"  CDC
 SG_ MDCDT069 : 63|8@0+ (1,0) [0|0] "-"  CDC
 SG_ MDCDT070 : 71|8@0+ (1,0) [0|0] "-"  CDC
 SG_ MDCDT071 : 79|8@0+ (1,0) [0|0] "-"  CDC
 SG_ MDCDT072 : 87|8@0+ (1,0) [0|0] "-"  CDC
 SG_ MDCDT073 : 95|8@0+ (1,0) [0|0] "-"  CDC
 SG_ MDCDT074 : 103|8@0+ (1,0) [0|0] "-"  CDC
 SG_ MDCDT075 : 111|8@0+ (1,0) [0|0] "-"  CDC
 SG_ MDCDT076 : 119|8@0+ (1,0) [0|0] "-"  CDC
 SG_ MDCDT077 : 127|8@0+ (1,0) [0|0] "-"  CDC
 SG_ MDCDT078 : 135|8@0+ (1,0) [0|0] "-"  CDC
 SG_ MDCDT079 : 143|8@0+ (1,0) [0|0] "-"  CDC
 SG_ MDCDT080 : 151|8@0+ (1,0) [0|0] "-"  CDC
 SG_ MDCDT081 : 159|8@0+ (1,0) [0|0] "-"  CDC
 SG_ MDCDT082 : 167|8@0+ (1,0) [0|0] "-"  CDC
 SG_ MDCDT083 : 175|8@0+ (1,0) [0|0] "-"  CDC
 SG_ MDCDT084 : 183|8@0+ (1,0) [0|0] "-"  CDC
 SG_ MDCDT085 : 191|8@0+ (1,0) [0|0] "-"  CDC
 SG_ MDCDT086 : 199|8@0+ (1,0) [0|0] "-"  CDC
 SG_ MDCDT087 : 207|8@0+ (1,0) [0|0] "-"  CDC
 SG_ MDCDT088 : 215|8@0+ (1,0) [0|0] "-"  CDC
 SG_ MDCDT089 : 223|8@0+ (1,0) [0|0] "-"  CDC
 SG_ MDCDT090 : 231|8@0+ (1,0) [0|0] "-"  CDC
 SG_ MDCDT091 : 239|8@0+ (1,0) [0|0] "-"  CDC
 SG_ MDCDT092 : 247|8@0+ (1,0) [0|0] "-"  CDC
 SG_ MDCDT093 : 255|8@0+ (1,0) [0|0] "-"  CDC

BO_ 363 ADU1S26: 32 ADC
 SG_ MDSYNC08 : 4|5@0+ (1,0) [0|0] "-"  CDC
 SG_ MDCDT094 : 15|8@0+ (1,0) [0|0] "-"  CDC
 SG_ MDCDT095 : 23|8@0+ (1,0) [0|0] "-"  CDC
 SG_ MDCDT096 : 31|8@0+ (1,0) [0|0] "-"  CDC
 SG_ MDCDT097 : 39|8@0+ (1,0) [0|0] "-"  CDC
 SG_ MDCDT098 : 47|8@0+ (1,0) [0|0] "-"  CDC
 SG_ MDCDT099 : 55|8@0+ (1,0) [0|0] "-"  CDC
 SG_ MDCDT100 : 63|8@0+ (1,0) [0|0] "-"  CDC
 SG_ MDCDT101 : 71|8@0+ (1,0) [0|0] "-"  CDC
 SG_ MDCDT102 : 79|8@0+ (1,0) [0|0] "-"  CDC
 SG_ MDCDT103 : 87|8@0+ (1,0) [0|0] "-"  CDC
 SG_ MDCDT104 : 95|8@0+ (1,0) [0|0] "-"  CDC
 SG_ MDCDT105 : 103|8@0+ (1,0) [0|0] "-"  CDC
 SG_ MDCDT106 : 111|8@0+ (1,0) [0|0] "-"  CDC
 SG_ MDCDT107 : 119|8@0+ (1,0) [0|0] "-"  CDC
 SG_ MDCDT108 : 127|8@0+ (1,0) [0|0] "-"  CDC
 SG_ MDCDT109 : 135|8@0+ (1,0) [0|0] "-"  CDC
 SG_ MDCDT110 : 143|8@0+ (1,0) [0|0] "-"  CDC
 SG_ MDCDT111 : 151|8@0+ (1,0) [0|0] "-"  CDC
 SG_ MDCDT112 : 159|8@0+ (1,0) [0|0] "-"  CDC
 SG_ MDCDT113 : 167|8@0+ (1,0) [0|0] "-"  CDC
 SG_ MDCDT114 : 175|8@0+ (1,0) [0|0] "-"  CDC
 SG_ MDCDT115 : 183|8@0+ (1,0) [0|0] "-"  CDC
 SG_ MDCDT116 : 191|8@0+ (1,0) [0|0] "-"  CDC
 SG_ MDCDT117 : 199|8@0+ (1,0) [0|0] "-"  CDC
 SG_ MDCDT118 : 207|8@0+ (1,0) [0|0] "-"  CDC
 SG_ MDCDT119 : 215|8@0+ (1,0) [0|0] "-"  CDC
 SG_ MDCDT120 : 223|8@0+ (1,0) [0|0] "-"  CDC
 SG_ MDCDT121 : 231|8@0+ (1,0) [0|0] "-"  CDC
 SG_ MDCDT122 : 239|8@0+ (1,0) [0|0] "-"  CDC
 SG_ MDCDT123 : 247|8@0+ (1,0) [0|0] "-"  CDC
 SG_ MDCDT124 : 255|8@0+ (1,0) [0|0] "-"  CDC

BO_ 364 ADU1S27: 32 ADC
 SG_ MDSYNC09 : 4|5@0+ (1,0) [0|0] "-"  CDC
 SG_ MDCDT125 : 15|8@0+ (1,0) [0|0] "-"  CDC
 SG_ MDCDT126 : 23|8@0+ (1,0) [0|0] "-"  CDC
 SG_ MDCDT127 : 31|8@0+ (1,0) [0|0] "-"  CDC
 SG_ MDCDT128 : 39|8@0+ (1,0) [0|0] "-"  CDC
 SG_ MDCDT129 : 47|8@0+ (1,0) [0|0] "-"  CDC
 SG_ MDCDT130 : 55|8@0+ (1,0) [0|0] "-"  CDC
 SG_ MDCDT131 : 63|8@0+ (1,0) [0|0] "-"  CDC
 SG_ MDCDT132 : 71|8@0+ (1,0) [0|0] "-"  CDC
 SG_ MDCDT133 : 79|8@0+ (1,0) [0|0] "-"  CDC
 SG_ MDCDT134 : 87|8@0+ (1,0) [0|0] "-"  CDC
 SG_ MDCDT135 : 95|8@0+ (1,0) [0|0] "-"  CDC
 SG_ MDCDT136 : 103|8@0+ (1,0) [0|0] "-"  CDC
 SG_ MDCDT137 : 111|8@0+ (1,0) [0|0] "-"  CDC
 SG_ MDCDT138 : 119|8@0+ (1,0) [0|0] "-"  CDC
 SG_ MDCDT139 : 127|8@0+ (1,0) [0|0] "-"  CDC
 SG_ MDCDT140 : 135|8@0+ (1,0) [0|0] "-"  CDC
 SG_ MDCDT141 : 143|8@0+ (1,0) [0|0] "-"  CDC
 SG_ MDCDT142 : 151|8@0+ (1,0) [0|0] "-"  CDC
 SG_ MDCDT143 : 159|8@0+ (1,0) [0|0] "-"  CDC
 SG_ MDCDT144 : 167|8@0+ (1,0) [0|0] "-"  CDC
 SG_ MDCDT145 : 175|8@0+ (1,0) [0|0] "-"  CDC
 SG_ MDCDT146 : 183|8@0+ (1,0) [0|0] "-"  CDC
 SG_ MDCDT147 : 191|8@0+ (1,0) [0|0] "-"  CDC
 SG_ MDCDT148 : 199|8@0+ (1,0) [0|0] "-"  CDC
 SG_ MDCDT149 : 207|8@0+ (1,0) [0|0] "-"  CDC
 SG_ MDCDT150 : 215|8@0+ (1,0) [0|0] "-"  CDC
 SG_ MDCDT151 : 223|8@0+ (1,0) [0|0] "-"  CDC
 SG_ MDCDT152 : 231|8@0+ (1,0) [0|0] "-"  CDC
 SG_ MDCDT153 : 239|8@0+ (1,0) [0|0] "-"  CDC
 SG_ MDCDT154 : 247|8@0+ (1,0) [0|0] "-"  CDC
 SG_ MDCDT155 : 255|8@0+ (1,0) [0|0] "-"  CDC

BO_ 365 ADU1S28: 32 ADC
 SG_ MDSYNC10 : 4|5@0+ (1,0) [0|0] "-"  CDC
 SG_ MDCDT156 : 15|8@0+ (1,0) [0|0] "-"  CDC
 SG_ MDCDT157 : 23|8@0+ (1,0) [0|0] "-"  CDC
 SG_ MDCDT158 : 31|8@0+ (1,0) [0|0] "-"  CDC
 SG_ MDCDT159 : 39|8@0+ (1,0) [0|0] "-"  CDC
 SG_ MDCDT160 : 47|8@0+ (1,0) [0|0] "-"  CDC
 SG_ MDCDT161 : 55|8@0+ (1,0) [0|0] "-"  CDC
 SG_ MDCDT162 : 63|8@0+ (1,0) [0|0] "-"  CDC
 SG_ MDCDT163 : 71|8@0+ (1,0) [0|0] "-"  CDC
 SG_ MDCDT164 : 79|8@0+ (1,0) [0|0] "-"  CDC
 SG_ MDCDT165 : 87|8@0+ (1,0) [0|0] "-"  CDC
 SG_ MDCDT166 : 95|8@0+ (1,0) [0|0] "-"  CDC
 SG_ MDCDT167 : 103|8@0+ (1,0) [0|0] "-"  CDC
 SG_ MDCDT168 : 111|8@0+ (1,0) [0|0] "-"  CDC
 SG_ MDCDT169 : 119|8@0+ (1,0) [0|0] "-"  CDC
 SG_ MDCDT170 : 127|8@0+ (1,0) [0|0] "-"  CDC
 SG_ MDCDT171 : 135|8@0+ (1,0) [0|0] "-"  CDC
 SG_ MDCDT172 : 143|8@0+ (1,0) [0|0] "-"  CDC
 SG_ MDCDT173 : 151|8@0+ (1,0) [0|0] "-"  CDC
 SG_ MDCDT174 : 159|8@0+ (1,0) [0|0] "-"  CDC
 SG_ MDCDT175 : 167|8@0+ (1,0) [0|0] "-"  CDC
 SG_ MDCDT176 : 175|8@0+ (1,0) [0|0] "-"  CDC
 SG_ MDCDT177 : 183|8@0+ (1,0) [0|0] "-"  CDC
 SG_ MDCDT178 : 191|8@0+ (1,0) [0|0] "-"  CDC
 SG_ MDCDT179 : 199|8@0+ (1,0) [0|0] "-"  CDC
 SG_ MDCDT180 : 207|8@0+ (1,0) [0|0] "-"  CDC
 SG_ MDCDT181 : 215|8@0+ (1,0) [0|0] "-"  CDC
 SG_ MDCDT182 : 223|8@0+ (1,0) [0|0] "-"  CDC
 SG_ MDCDT183 : 231|8@0+ (1,0) [0|0] "-"  CDC
 SG_ MDCDT184 : 239|8@0+ (1,0) [0|0] "-"  CDC
 SG_ MDCDT185 : 247|8@0+ (1,0) [0|0] "-"  CDC
 SG_ MDCDT186 : 255|8@0+ (1,0) [0|0] "-"  CDC

BO_ 114 ARS1S01: 32 DDM
 SG_ ARANGINV : 31|1@0+ (1,0) [0|0] "-"  CDC
 SG_ ARSANG : 29|14@0- (5E-005,0) [0|0] "rad"  CDC
 SG_ ARSF : 46|1@0+ (1,0) [0|0] "-"  CDC
 SG_ ARSSYS : 74|3@0+ (1,0) [0|0] "-"  CDC

BO_ 902 AVN1S03: 32 CDC
 SG_ ANS : 7|1@0+ (1,0) [0|0] "-"  ADC,DDM
 SG_ FLYNOP : 6|2@0+ (1,0) [0|0] "-"  DDM
 SG_ FLGPSOP : 4|1@0+ (1,0) [0|0] "-"  DDM
 SG_ FLADELOP : 3|1@0+ (1,0) [0|0] "-"  DDM
 SG_ CRS1 : 15|1@0+ (1,0) [0|0] "-"  ADC,DDM
 SG_ RQAC : 14|7@0+ (0.02,0) [0|0] "G"  ADC,DDM
 SG_ GUID : 23|1@0+ (1,0) [0|0] "-"  ADC,DDM
 SG_ GYRO : 22|1@0+ (1,0) [0|0] "-"  ADC,DDM
 SG_ NCRN : 21|1@0+ (1,0) [0|0] "-"  ADC,DDM
 SG_ CRN6 : 20|1@0+ (1,0) [0|0] "-"  ADC,DDM
 SG_ CRN5 : 19|1@0+ (1,0) [0|0] "-"  ADC,DDM
 SG_ CRN3 : 18|1@0+ (1,0) [0|0] "-"  ADC,DDM
 SG_ CRN2 : 17|1@0+ (1,0) [0|0] "-"  ADC,DDM
 SG_ CRN1 : 16|1@0+ (1,0) [0|0] "-"  ADC,DDM
 SG_ CONFID03 : 31|2@0+ (1,0) [0|0] "-"  DDM
 SG_ CURV : 29|2@0+ (1,0) [0|0] "-"  ADC,DDM
 SG_ CVST : 27|1@0+ (1,0) [0|0] "-"  ADC,DDM
 SG_ NAVI_STR : 26|1@0+ (1,0) [0|0] "-"  DDM
 SG_ MIND : 25|1@0+ (1,0) [0|0] "-"  DDM
 SG_ ONOFF : 24|1@0+ (1,0) [0|0] "-"  DDM
 SG_ HWPB : 39|1@0+ (1,0) [0|0] "-"  ADC,DDM
 SG_ RAD : 38|7@0+ (5,0) [0|0] "m"  ADC,DDM
 SG_ USMANS : 47|1@0+ (1,0) [0|0] "-"  ADC,DDM
 SG_ SLJ : 44|2@0+ (1,0) [0|0] "-"  DDM
 SG_ SLUS : 42|1@0+ (1,0) [0|0] "-"  DDM
 SG_ AFS_SW : 41|1@0+ (1,0) [0|0] "-"  DDM
 SG_ AVS_SW : 40|1@0+ (1,0) [0|0] "-"  DDM

BO_ 905 AVN1S08: 8 CDC
 SG_ BZ_M_SW : 15|1@0+ (1,0) [0|0] "-"  ADC
 SG_ CS_R_SW : 14|1@0+ (1,0) [0|0] "-"  ADC
 SG_ BM : 13|1@0+ (1,0) [0|0] "-"  ADC
 SG_ SUR_STAT : 12|2@0+ (1,0) [0|0] "-"  Vector_XXX
 SG_ NOP_YN : 8|1@0+ (1,0) [0|0] "-"  Vector_XXX
 SG_ NOP_CO : 23|1@0+ (1,0) [0|0] "-"  Vector_XXX
 SG_ NOP_P : 22|6@0+ (1,0) [0|0] "-"  Vector_XXX
 SG_ NOP_CI : 16|5@0+ (1,0) [0|0] "-"  Vector_XXX
 SG_ NOP_S1 : 27|6@0+ (1,0) [0|0] "-"  Vector_XXX
 SG_ NOP_S2 : 37|6@0+ (1,0) [0|0] "-"  Vector_XXX
 SG_ NOP_S3 : 47|6@0+ (1,0) [0|0] "-"  Vector_XXX
 SG_ NOP_S4 : 41|6@0+ (1,0) [0|0] "-"  Vector_XXX
 SG_ NOP_S5 : 51|6@0+ (1,0) [0|0] "-"  Vector_XXX
 SG_ NOP_S6 : 61|6@0+ (1,0) [0|0] "-"  Vector_XXX

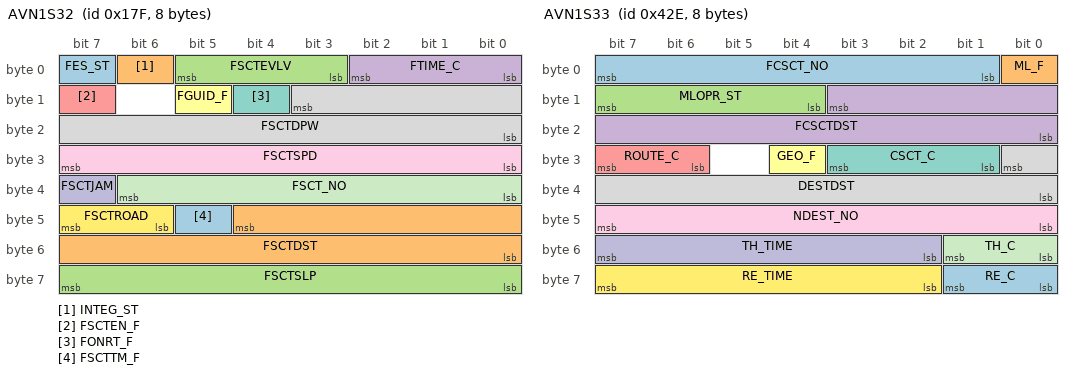
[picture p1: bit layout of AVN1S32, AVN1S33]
BO_ 383 AVN1S32: 8 CDC
 SG_ FES_ST : 7|1@0+ (1,0) [0|0] "-"  Vector_XXX
 SG_ INTEG_ST : 6|1@0+ (1,0) [0|0] "-"  Vector_XXX
 SG_ FSCTEVLV : 5|3@0+ (1,0) [0|0] "-"  Vector_XXX
 SG_ FTIME_C : 2|3@0+ (1,0) [0|0] "-"  Vector_XXX
 SG_ FSCTEN_F : 15|1@0+ (1,0) [0|0] "-"  Vector_XXX
 SG_ FGUID_F : 13|1@0+ (1,0) [0|0] "-"  Vector_XXX
 SG_ FONRT_F : 12|1@0+ (1,0) [0|0] "-"  Vector_XXX
 SG_ FSCTDPW : 11|12@0+ (0.1,-64) [0|0] "ｋW"  Vector_XXX
 SG_ FSCTSPD : 31|8@0+ (1,0) [0|0] "km/h"  Vector_XXX
 SG_ FSCTJAM : 39|1@0+ (1,0) [0|0] "-"  Vector_XXX
 SG_ FSCT_NO : 38|7@0+ (1,0) [0|0] "-"  Vector_XXX
 SG_ FSCTROAD : 47|2@0+ (1,0) [0|0] "-"  Vector_XXX
 SG_ FSCTTM_F : 45|1@0+ (1,0) [0|0] "-"  Vector_XXX
 SG_ FSCTDST : 44|13@0+ (10,0) [0|0] "m"  Vector_XXX
 SG_ FSCTSLP : 63|8@0- (0.2,0) [0|0] "%"  Vector_XXX

BO_ 1070 AVN1S33: 8 CDC
 SG_ FCSCT_NO : 7|7@0+ (1,0) [0|0] "-"  Vector_XXX
 SG_ ML_F : 0|1@0+ (1,0) [0|0] "-"  Vector_XXX
 SG_ MLOPR_ST : 15|4@0+ (1,0) [0|0] "-"  Vector_XXX
 SG_ FCSCTDST : 11|12@0+ (10,0) [0|0] "m"  Vector_XXX
 SG_ ROUTE_C : 31|2@0+ (1,0) [0|0] "-"  Vector_XXX
 SG_ GEO_F : 28|1@0+ (1,0) [0|0] "-"  Vector_XXX
 SG_ CSCT_C : 27|3@0+ (1,0) [0|0] "-"  Vector_XXX
 SG_ DESTDST : 24|9@0+ (1,0) [0|0] "km"  Vector_XXX
 SG_ NDEST_NO : 47|8@0+ (1,0) [0|0] "-"  Vector_XXX
 SG_ TH_TIME : 55|6@0+ (1,0) [0|0] "min"  Vector_XXX
 SG_ TH_C : 49|2@0+ (1,0) [0|0] "-"  Vector_XXX
 SG_ RE_TIME : 63|6@0+ (1,0) [0|0] "min"  Vector_XXX
 SG_ RE_C : 57|2@0+ (1,0) [0|0] "-"  Vector_XXX

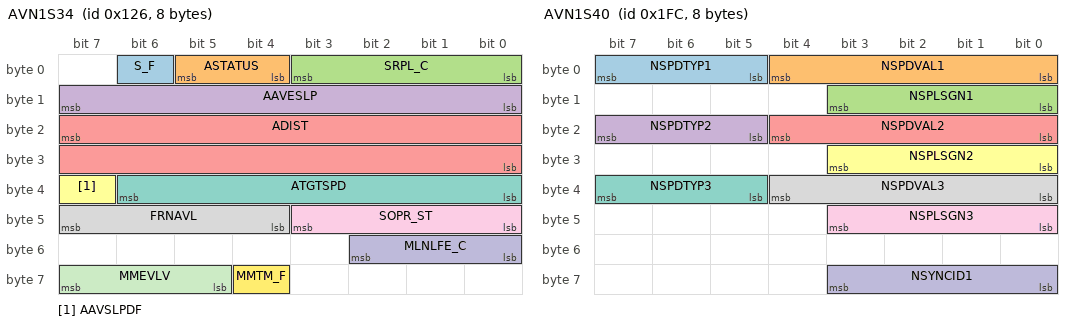
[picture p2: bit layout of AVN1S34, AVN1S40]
BO_ 294 AVN1S34: 8 CDC
 SG_ S_F : 6|1@0+ (1,0) [0|0] "-"  Vector_XXX
 SG_ ASTATUS : 5|2@0+ (1,0) [0|0] "-"  Vector_XXX
 SG_ SRPL_C : 3|4@0+ (1,0) [0|0] "-"  Vector_XXX
 SG_ AAVESLP : 15|8@0- (0.2,0) [0|0] "%"  Vector_XXX
 SG_ ADIST : 23|16@0+ (1,0) [0|0] "m"  Vector_XXX
 SG_ AAVSLPDF : 39|1@0+ (1,0) [0|0] "-"  Vector_XXX
 SG_ ATGTSPD : 38|7@0+ (1,0) [0|0] "km/h"  Vector_XXX
 SG_ FRNAVL : 47|4@0+ (1,0) [0|0] "-"  Vector_XXX
 SG_ SOPR_ST : 43|4@0+ (1,0) [0|0] "-"  Vector_XXX
 SG_ MLNLFE_C : 50|3@0+ (1,0) [0|0] "-"  Vector_XXX
 SG_ MMEVLV : 63|3@0+ (1,0) [0|0] "-"  Vector_XXX
 SG_ MMTM_F : 60|1@0+ (1,0) [0|0] "-"  Vector_XXX

BO_ 508 AVN1S40: 8 CDC
 SG_ NSPDTYP1 : 7|3@0+ (1,0) [0|0] "-"  ADC
 SG_ NSPDVAL1 : 4|5@0+ (1,0) [0|0] "-"  ADC
 SG_ NSPLSGN1 : 11|4@0+ (1,0) [0|0] "-"  ADC
 SG_ NSPDTYP2 : 23|3@0+ (1,0) [0|0] "-"  ADC
 SG_ NSPDVAL2 : 20|5@0+ (1,0) [0|0] "-"  ADC
 SG_ NSPLSGN2 : 27|4@0+ (1,0) [0|0] "-"  ADC
 SG_ NSPDTYP3 : 39|3@0+ (1,0) [0|0] "-"  ADC
 SG_ NSPDVAL3 : 36|5@0+ (1,0) [0|0] "-"  ADC
 SG_ NSPLSGN3 : 43|4@0+ (1,0) [0|0] "-"  ADC
 SG_ NSYNCID1 : 59|4@0+ (1,0) [0|0] "-"  ADC

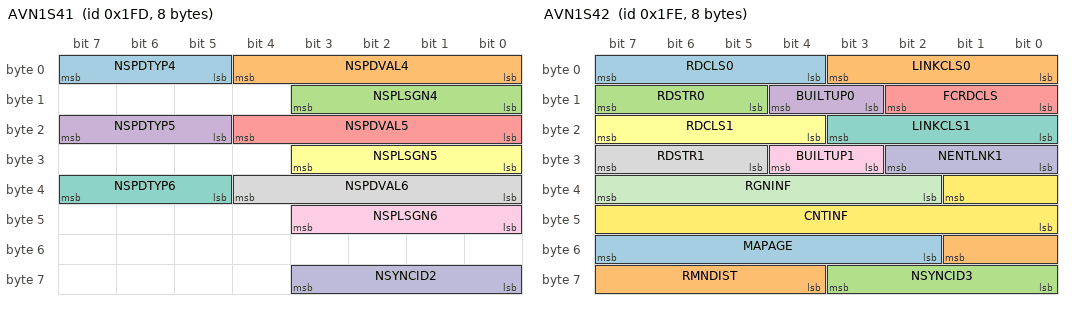
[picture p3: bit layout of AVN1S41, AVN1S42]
BO_ 509 AVN1S41: 8 CDC
 SG_ NSPDTYP4 : 7|3@0+ (1,0) [0|0] "-"  ADC
 SG_ NSPDVAL4 : 4|5@0+ (1,0) [0|0] "-"  ADC
 SG_ NSPLSGN4 : 11|4@0+ (1,0) [0|0] "-"  ADC
 SG_ NSPDTYP5 : 23|3@0+ (1,0) [0|0] "-"  ADC
 SG_ NSPDVAL5 : 20|5@0+ (1,0) [0|0] "-"  ADC
 SG_ NSPLSGN5 : 27|4@0+ (1,0) [0|0] "-"  ADC
 SG_ NSPDTYP6 : 39|3@0+ (1,0) [0|0] "-"  ADC
 SG_ NSPDVAL6 : 36|5@0+ (1,0) [0|0] "-"  ADC
 SG_ NSPLSGN6 : 43|4@0+ (1,0) [0|0] "-"  ADC
 SG_ NSYNCID2 : 59|4@0+ (1,0) [0|0] "-"  ADC

BO_ 510 AVN1S42: 8 CDC
 SG_ RDCLS0 : 7|4@0+ (1,0) [0|0] "-"  ADC
 SG_ LINKCLS0 : 3|4@0+ (1,0) [0|0] "-"  ADC
 SG_ RDSTR0 : 15|3@0+ (1,0) [0|0] "-"  Vector_XXX
 SG_ BUILTUP0 : 12|2@0+ (1,0) [0|0] "-"  Vector_XXX
 SG_ FCRDCLS : 10|3@0+ (1,0) [0|0] "-"  ADC
 SG_ RDCLS1 : 23|4@0+ (1,0) [0|0] "-"  ADC
 SG_ LINKCLS1 : 19|4@0+ (1,0) [0|0] "-"  ADC
 SG_ RDSTR1 : 31|3@0+ (1,0) [0|0] "-"  Vector_XXX
 SG_ BUILTUP1 : 28|2@0+ (1,0) [0|0] "-"  Vector_XXX
 SG_ NENTLNK1 : 26|3@0+ (1,0) [0|0] "-"  ADC
 SG_ RGNINF : 39|6@0+ (1,0) [0|0] "-"  Vector_XXX
 SG_ CNTINF : 33|10@0+ (1,0) [0|0] "-"  ADC
 SG_ MAPAGE : 55|6@0+ (1,2000) [0|0] "Year"  Vector_XXX
 SG_ RMNDIST : 49|6@0+ (10,0) [0|0] "m"  ADC
 SG_ NSYNCID3 : 59|4@0+ (1,0) [0|0] "-"  ADC

BO_ 511 AVN1S43: 8 CDC
 SG_ RDCLS2 : 7|4@0+ (1,0) [0|0] "-"  ADC
 SG_ LINKCLS2 : 3|4@0+ (1,0) [0|0] "-"  ADC
 SG_ RDSTR2 : 15|3@0+ (1,0) [0|0] "-"  Vector_XXX
 SG_ BUILTUP2 : 12|2@0+ (1,0) [0|0] "-"  Vector_XXX
 SG_ NENTLNK2 : 10|3@0+ (1,0) [0|0] "-"  ADC
 SG_ RDCLS3 : 23|4@0+ (1,0) [0|0] "-"  ADC
 SG_ LINKCLS3 : 19|4@0+ (1,0) [0|0] "-"  ADC
 SG_ RDSTR3 : 31|3@0+ (1,0) [0|0] "-"  Vector_XXX
 SG_ BUILTUP3 : 28|2@0+ (1,0) [0|0] "-"  Vector_XXX
 SG_ NENTLNK3 : 26|3@0+ (1,0) [0|0] "-"  ADC
 SG_ RDCLS4 : 39|4@0+ (1,0) [0|0] "-"  ADC
 SG_ LINKCLS4 : 35|4@0+ (1,0) [0|0] "-"  ADC
 SG_ RDSTR4 : 47|3@0+ (1,0) [0|0] "-"  Vector_XXX
 SG_ BUILTUP4 : 44|2@0+ (1,0) [0|0] "-"  Vector_XXX
 SG_ NENTLNK4 : 42|3@0+ (1,0) [0|0] "-"  ADC
 SG_ LANNUM : 55|4@0+ (1,0) [0|0] "-"  ADC
 SG_ MTCHCONF : 51|2@0+ (1,0) [0|0] "-"  ADC
 SG_ NSPDUNT : 49|2@0+ (1,0) [0|0] "-"  ADC
 SG_ ROUTSTS : 63|2@0+ (1,0) [0|0] "-"  ADC
 SG_ AVNFAIL : 61|1@0+ (1,0) [0|0] "-"  ADC
 SG_ NSYNCID4 : 59|4@0+ (1,0) [0|0] "-"  ADC

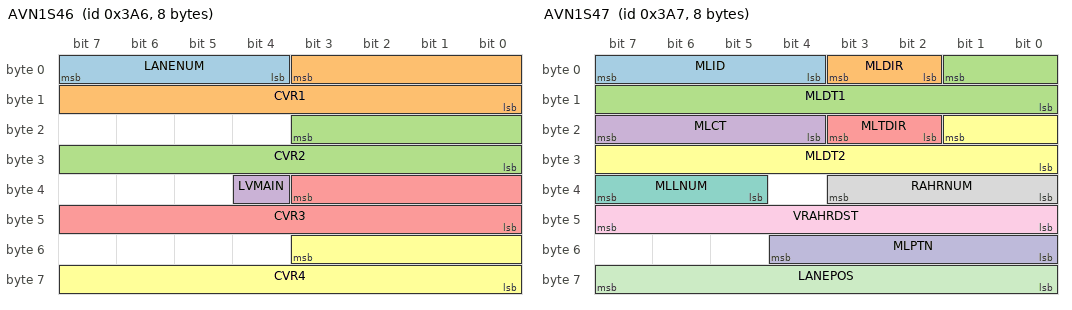
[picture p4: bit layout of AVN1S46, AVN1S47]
BO_ 934 AVN1S46: 8 CDC
 SG_ LANENUM : 7|4@0+ (1,0) [0|0] "-"  Vector_XXX
 SG_ CVR1 : 3|12@0- (1,0) [0|0] "m"  Vector_XXX
 SG_ CVR2 : 19|12@0- (1,0) [0|0] "m"  Vector_XXX
 SG_ LVMAIN : 36|1@0+ (1,0) [0|0] "-"  Vector_XXX
 SG_ CVR3 : 35|12@0- (1,0) [0|0] "m"  Vector_XXX
 SG_ CVR4 : 51|12@0- (1,0) [0|0] "m"  Vector_XXX

BO_ 935 AVN1S47: 8 CDC
 SG_ MLID : 7|4@0+ (1,0) [0|0] "-"  Vector_XXX
 SG_ MLDIR : 3|2@0+ (1,0) [0|0] "-"  Vector_XXX
 SG_ MLDT1 : 1|10@0+ (2,0) [0|0] "m"  Vector_XXX
 SG_ MLCT : 23|4@0+ (1,0) [0|0] "-"  Vector_XXX
 SG_ MLTDIR : 19|2@0+ (1,0) [0|0] "-"  Vector_XXX
 SG_ MLDT2 : 17|10@0+ (2,0) [0|0] "m"  Vector_XXX
 SG_ MLLNUM : 39|3@0+ (1,0) [0|0] "-"  Vector_XXX
 SG_ RAHRNUM : 35|4@0+ (1,0) [0|0] "-"  Vector_XXX
 SG_ VRAHRDST : 47|8@0+ (10,0) [0|0] "m"  Vector_XXX
 SG_ MLPTN : 52|5@0+ (1,0) [0|0] "-"  Vector_XXX
 SG_ LANEPOS : 63|8@0+ (1,0) [0|0] "-"  Vector_XXX

BO_ 846 AVN1S61: 8 CDC
 SG_ CLE_RNG : 7|16@0+ (0.1,0) [0|0] "km"  Vector_XXX
 SG_ CLE_SOCT : 23|8@0+ (1,0) [0|0] "%"  Vector_XXX

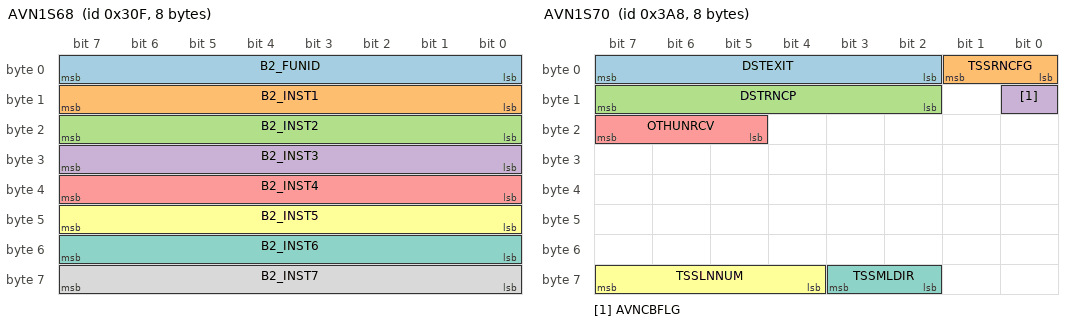
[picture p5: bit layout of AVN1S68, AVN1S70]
BO_ 783 AVN1S68: 8 CDC
 SG_ B2_FUNID : 7|8@0+ (1,0) [0|0] "-"  Vector_XXX
 SG_ B2_INST1 : 15|8@0+ (1,0) [0|0] "-"  Vector_XXX
 SG_ B2_INST2 : 23|8@0+ (1,0) [0|0] "-"  Vector_XXX
 SG_ B2_INST3 : 31|8@0+ (1,0) [0|0] "-"  Vector_XXX
 SG_ B2_INST4 : 39|8@0+ (1,0) [0|0] "-"  Vector_XXX
 SG_ B2_INST5 : 47|8@0+ (1,0) [0|0] "-"  Vector_XXX
 SG_ B2_INST6 : 55|8@0+ (1,0) [0|0] "-"  Vector_XXX
 SG_ B2_INST7 : 63|8@0+ (1,0) [0|0] "-"  Vector_XXX

BO_ 936 AVN1S70: 8 CDC
 SG_ DSTEXIT : 7|6@0+ (1,0) [0|0] "-"  Vector_XXX
 SG_ TSSRNCFG : 1|2@0+ (1,0) [0|0] "-"  Vector_XXX
 SG_ DSTRNCP : 15|6@0+ (1,0) [0|0] "-"  Vector_XXX
 SG_ AVNCBFLG : 8|1@0+ (1,0) [0|0] "-"  Vector_XXX
 SG_ OTHUNRCV : 23|3@0+ (1,0) [0|0] "-"  Vector_XXX
 SG_ TSSLNNUM : 63|4@0+ (1,0) [0|0] "-"  Vector_XXX
 SG_ TSSMLDIR : 59|2@0+ (1,0) [0|0] "-"  Vector_XXX

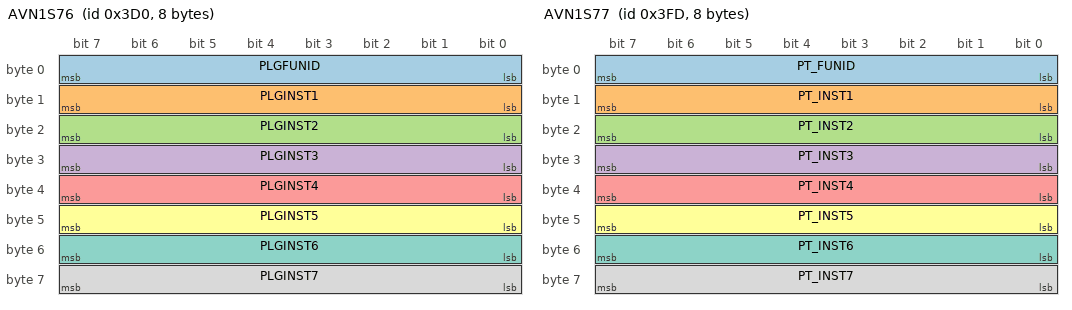
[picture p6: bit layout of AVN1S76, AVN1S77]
BO_ 976 AVN1S76: 8 CDC
 SG_ PLGFUNID : 7|8@0+ (1,0) [0|0] "-"  DDM
 SG_ PLGINST1 : 15|8@0+ (1,0) [0|0] "-"  DDM
 SG_ PLGINST2 : 23|8@0+ (1,0) [0|0] "-"  DDM
 SG_ PLGINST3 : 31|8@0+ (1,0) [0|0] "-"  DDM
 SG_ PLGINST4 : 39|8@0+ (1,0) [0|0] "-"  DDM
 SG_ PLGINST5 : 47|8@0+ (1,0) [0|0] "-"  DDM
 SG_ PLGINST6 : 55|8@0+ (1,0) [0|0] "-"  DDM
 SG_ PLGINST7 : 63|8@0+ (1,0) [0|0] "-"  DDM

BO_ 1021 AVN1S77: 8 CDC
 SG_ PT_FUNID : 7|8@0+ (1,0) [0|0] "-"  Vector_XXX
 SG_ PT_INST1 : 15|8@0+ (1,0) [0|0] "-"  Vector_XXX
 SG_ PT_INST2 : 23|8@0+ (1,0) [0|0] "-"  Vector_XXX
 SG_ PT_INST3 : 31|8@0+ (1,0) [0|0] "-"  Vector_XXX
 SG_ PT_INST4 : 39|8@0+ (1,0) [0|0] "-"  Vector_XXX
 SG_ PT_INST5 : 47|8@0+ (1,0) [0|0] "-"  Vector_XXX
 SG_ PT_INST6 : 55|8@0+ (1,0) [0|0] "-"  Vector_XXX
 SG_ PT_INST7 : 63|8@0+ (1,0) [0|0] "-"  Vector_XXX

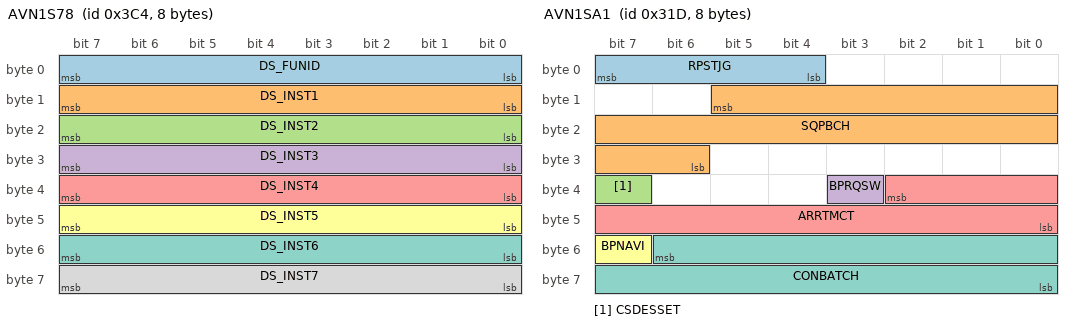
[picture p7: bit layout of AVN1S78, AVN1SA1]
BO_ 964 AVN1S78: 8 CDC
 SG_ DS_FUNID : 7|8@0+ (1,0) [0|0] "-"  ADC
 SG_ DS_INST1 : 15|8@0+ (1,0) [0|0] "-"  ADC
 SG_ DS_INST2 : 23|8@0+ (1,0) [0|0] "-"  ADC
 SG_ DS_INST3 : 31|8@0+ (1,0) [0|0] "-"  ADC
 SG_ DS_INST4 : 39|8@0+ (1,0) [0|0] "-"  ADC
 SG_ DS_INST5 : 47|8@0+ (1,0) [0|0] "-"  ADC
 SG_ DS_INST6 : 55|8@0+ (1,0) [0|0] "-"  ADC
 SG_ DS_INST7 : 63|8@0+ (1,0) [0|0] "-"  ADC

BO_ 797 AVN1SA1: 8 CDC
 SG_ RPSTJG : 7|4@0+ (1,0) [0|0] "-"  DDM
 SG_ SQPBCH : 13|16@0+ (2,0) [0|0] "kW*kW"  DDM
 SG_ CSDESSET : 39|1@0+ (1,0) [0|0] "-"  DDM
 SG_ BPRQSW : 35|1@0+ (1,0) [0|0] "-"  DDM
 SG_ ARRTMCT : 34|11@0+ (1,0) [0|0] "分"  DDM
 SG_ BPNAVI : 55|1@0+ (1,0) [0|0] "-"  DDM
 SG_ CONBATCH : 54|15@0+ (5,0) [0|0] "Wh"  DDM

BO_ 1009 AVN1SA8: 64 CDC
 SG_ EDMMNUM : 7|8@0+ (1,0) [0|0] "-"  Vector_XXX
 SG_ EDMMID1 : 15|16@0+ (1,0) [0|0] "-"  Vector_XXX
 SG_ EDMMTS1 : 31|64@0+ (1,0) [0|0] "-"  Vector_XXX
 SG_ EDMMID2 : 95|16@0+ (1,0) [0|0] "-"  Vector_XXX
 SG_ EDMMTS2 : 111|64@0+ (1,0) [0|0] "-"  Vector_XXX
 SG_ EDMMID3 : 175|16@0+ (1,0) [0|0] "-"  Vector_XXX
 SG_ EDMMTS3 : 191|64@0+ (1,0) [0|0] "-"  Vector_XXX
 SG_ EDMMID4 : 255|16@0+ (1,0) [0|0] "-"  Vector_XXX
 SG_ EDMMTS4 : 271|64@0+ (1,0) [0|0] "-"  Vector_XXX
 SG_ EDMMID5 : 335|16@0+ (1,0) [0|0] "-"  Vector_XXX
 SG_ EDMMTS5 : 351|64@0+ (1,0) [0|0] "-"  Vector_XXX
 SG_ EDMMID6 : 415|16@0+ (1,0) [0|0] "-"  Vector_XXX
 SG_ EDMMTS6 : 431|64@0+ (1,0) [0|0] "-"  Vector_XXX

BO_ 962 AVN1SA9: 32 CDC
 SG_ RPSNO1_A : 7|3@0+ (1,0) [0|0] "-"  Vector_XXX
 SG_ RPSNO2_A : 4|3@0+ (1,0) [0|0] "-"  Vector_XXX
 SG_ RPEPS1 : 1|8@0+ (500,0) [0|0] "Wh"  Vector_XXX
 SG_ RPEPS2 : 9|8@0+ (500,0) [0|0] "Wh"  Vector_XXX
 SG_ RPEPS3 : 17|8@0+ (500,0) [0|0] "Wh"  Vector_XXX
 SG_ RPEPS4 : 25|8@0+ (500,0) [0|0] "Wh"  Vector_XXX
 SG_ RPCRO1 : 33|6@0+ (10,0) [0|0] "kW"  Vector_XXX
 SG_ RPCRO2 : 43|6@0+ (10,0) [0|0] "kW"  Vector_XXX
 SG_ RPCRO3 : 53|6@0+ (10,0) [0|0] "kW"  Vector_XXX
 SG_ RPCRO4 : 63|6@0+ (10,0) [0|0] "kW"  Vector_XXX
 SG_ RPCTIM1 : 57|7@0+ (1,0) [0|0] "minutes"  Vector_XXX
 SG_ RPCTIM2 : 66|7@0+ (1,0) [0|0] "minutes"  Vector_XXX
 SG_ RPCTIM3 : 75|7@0+ (1,0) [0|0] "minutes"  Vector_XXX
 SG_ RPCTIM4 : 84|7@0+ (1,0) [0|0] "minutes"  Vector_XXX

BO_ 1038 AVN1SB1: 32 CDC
 SG_ TTLFRAM : 7|8@0+ (1,0) [0|0] "-"  ADC
 SG_ FRAMID0 : 15|8@0+ (1,0) [0|0] "-"  ADC
 SG_ FORMID : 23|8@0+ (1,0) [0|0] "-"  ADC
 SG_ X_DATAID : 31|16@0+ (1,0) [0|0] "-"  ADC
 SG_ X_TYPE : 47|4@0+ (1,0) [0|0] "-"  ADC
 SG_ PADDINGX : 43|4@0+ (1,0) [0|0] "-"  ADC
 SG_ X_DELAY : 55|8@0+ (0.1,0) [0|0] "s"  ADC
 SG_ Y_DATAID : 63|16@0+ (1,0) [0|0] "-"  ADC
 SG_ Y_TYPE : 79|4@0+ (1,0) [0|0] "-"  ADC
 SG_ PADDINGY : 75|4@0+ (1,0) [0|0] "-"  ADC
 SG_ Y_DELAY : 87|8@0+ (0.1,0) [0|0] "s"  ADC
 SG_ PREPROC : 95|4@0+ (1,0) [0|0] "-"  ADC
 SG_ COMPOPE : 91|4@0+ (1,0) [0|0] "-"  ADC
 SG_ Y_CONST : 103|32@0+ (1,0) [0|0] "-"  ADC
 SG_ COMPVAL : 135|32@0+ (1,0) [0|0] "-"  ADC
 SG_ FORMID_A : 167|8@0+ (1,0) [0|0] "-"  ADC
 SG_ FORMID_B : 175|8@0+ (1,0) [0|0] "-"  ADC
 SG_ LOGIOPE : 183|4@0+ (1,0) [0|0] "-"  ADC
 SG_ MAXTRG : 179|4@0+ (1,0) [0|0] "-"  ADC
 SG_ FORMID_C : 191|8@0+ (1,0) [0|0] "-"  ADC
 SG_ PADDING1 : 199|32@0+ (1,0) [0|0] "-"  ADC
 SG_ MDCREQID : 231|8@0+ (1,0) [0|0] "-"  ADC
 SG_ FORMID_D : 239|8@0+ (1,0) [0|0] "-"  ADC
 SG_ GRDDIST : 247|8@0+ (10,0) [0|0] "m"  ADC
 SG_ GRDTIME : 255|8@0+ (1,0) [0|0] "s"  ADC

BO_ 1306 AVN1SB4: 32 CDC
 SG_ TCIN_ID : 7|4@0+ (1,0) [0|0] "-"  ADC
 SG_ TCIN_TTP : 3|4@0+ (1,0) [0|0] "-"  ADC
 SG_ TCIN_AC : 15|3@0+ (1,0) [0|0] "-"  ADC
 SG_ TCIN_HTP : 12|3@0+ (1,0) [0|0] "-"  ADC
 SG_ TCIN_LM : 9|2@0+ (1,0) [0|0] "-"  ADC
 SG_ TCIN_NAX : 23|3@0+ (1,0) [0|0] "-"  ADC
 SG_ TCIN_BTP : 20|3@0+ (1,0) [0|0] "-"  ADC
 SG_ TCIN_HLM : 17|2@0+ (1,0) [0|0] "-"  ADC
 SG_ TCIN_L : 31|8@0+ (50,0) [0|0] "mm"  ADC
 SG_ TCIN_HL : 39|8@0+ (50,0) [0|0] "mm"  ADC
 SG_ TCIN_WB : 47|8@0+ (50,0) [0|0] "mm"  ADC
 SG_ TCIN_W : 55|8@0+ (50,0) [0|0] "mm"  ADC
 SG_ TCIN_WBM : 63|2@0+ (1,0) [0|0] "-"  ADC
 SG_ TCIN_WM : 61|2@0+ (1,0) [0|0] "-"  ADC
 SG_ TCIN_TWM : 59|2@0+ (1,0) [0|0] "-"  ADC
 SG_ TCIN_TW : 71|8@0+ (50,0) [0|0] "kg"  ADC
 SG_ TCIN_MI : 235|20@0+ (1,0) [0|0] "km"  ADC

BO_ 1307 AVN1SB5: 32 CDC
 SG_ TCIN_TN : 7|256@0+ (1,0) [0|0] "-"  ADC

BO_ 1010 AVN1SB6: 8 CDC
 SG_ BEV_RNG : 7|16@0+ (0.1,0) [0|0] "km"  DDM
 SG_ BEV_TIME : 23|16@0+ (1,0) [0|0] "sec"  DDM

BO_ 723 AVN1SB8: 32 CDC
 SG_ GDPC_SW1 : 7|5@0+ (1,0) [0|0] "-"  DDM
 SG_ GDPC_SW2 : 2|5@0+ (1,0) [0|0] "-"  DDM
 SG_ GDPC_SW3 : 13|5@0+ (1,0) [0|0] "-"  DDM
 SG_ GDPC_SW4 : 8|5@0+ (1,0) [0|0] "-"  DDM
 SG_ GDPC_SW5 : 19|5@0+ (1,0) [0|0] "-"  DDM
 SG_ GDPC_SW6 : 30|5@0+ (1,0) [0|0] "-"  DDM
 SG_ GDPC_SW7 : 25|5@0+ (1,0) [0|0] "-"  DDM
 SG_ GDPC_SW8 : 36|5@0+ (1,0) [0|0] "-"  DDM
 SG_ GDPAVN_D : 47|1@0+ (1,0) [0|0] "-"  DDM

CM_ BO_ 472 "Reserve";
CM_ SG_ 472 SCSVNR "SCS voice guide request";
CM_ SG_ 472 VNUSGSCS "SCS equipment judgement flag";
CM_ BO_ 470 "Reserve";
CM_ SG_ 470 FLGXMAX "Floor sensor maximum Gx";
CM_ SG_ 470 FLVNMAX "Floor sensor maximum Vn amplitude";
CM_ SG_ 470 FRGMAX_L "Left front sensor maximum Gx amplitude";
CM_ SG_ 470 FRGMAX_R "Right front sensor maximum Gx amplitude";
CM_ SG_ 470 PT_ON "Pretensioner ON signal";
CM_ SG_ 470 FRAB_ON "Frontal airbag ON signal";
CM_ BO_ 1428 "Reserve";
CM_ SG_ 1428 USMDC1 "DA Front search distance of area 1";
CM_ SG_ 1428 USMDC2 "DA Front search distance of area 2";
CM_ SG_ 1428 USMDC3 "DA Front search distance of area 3";
CM_ SG_ 1428 USMDC5 "DA Front search distance of loose corner";
CM_ SG_ 1428 USMDC6 "DA Front search distance of middle corner";
CM_ SG_ 1428 USMDRQAC "DA Front search distance of necessity decrease speed calculation";
CM_ SG_ 1428 USMDC7 "DA Front search distance of hairpin corner";
CM_ SG_ 1428 USMNAV "DA navigation - ECT version";
CM_ BO_ 497 "Reserve";
CM_ SG_ 497 HNPAVABL "HNP usability judgement flag";
CM_ SG_ 497 UNPAVABL "UNP usability judgement flag";
CM_ SG_ 497 FCWAVABL "FCW usability judgement flag";
CM_ SG_ 497 ELKAVABL "ELK usability judgement flag";
CM_ SG_ 497 CDWAVABL "CDW usability judgement flag";
CM_ SG_ 497 SLFAVABL "SLIF usability judgement flag";
CM_ SG_ 497 TLAAVABL "TLA usability judgement flag";
CM_ SG_ 497 ESSAVABL "ESS usability judgement flag";
CM_ SG_ 497 CSWAVABL "CSW usability judgement flag";
CM_ SG_ 497 AESAVABL "AES usability judgement flag";
CM_ SG_ 497 CPAVABL "CP usability judgement flag";
CM_ SG_ 497 LDKAVABL "LDALKA usability judgement flag";
CM_ SG_ 497 MNPAVABL "MNP usability judgement flag";
CM_ BO_ 323 "Reserve";
CM_ SG_ 323 E_CRC143 "ADC1S10 E2E_CRC";
CM_ SG_ 323 E_CNT143 "ADC1S10 E2E_CNT";
CM_ SG_ 323 RCTBLV "China RCTB Level (China RCTB Level)";
CM_ SG_ 323 RCTBDIR "China RCTB Direction (China RCTB Directionl)";
CM_ SG_ 323 AEBDR "China AEB Direction (China AEB Direction)";
CM_ SG_ 323 ELKMD "China ELK Mode (ELK Mode)";
CM_ SG_ 323 ESSMD "China ESS Mode (ESS Mode)";
CM_ SG_ 323 ESSDR "China ESS Direction (China ESS Direction)";
CM_ SG_ 323 AESST "China AES Status (AES Status)";
CM_ SG_ 323 AESMD "China AES Mode (AES Mode)";
CM_ SG_ 323 AESDR "China AES Direction (China AES Direction)";
CM_ SG_ 323 HWFNST "China Highway Func State(ACC/CP/HNP/UNP/MRM)";
CM_ SG_ 323 ODDAPWRN "China approaching ODD downgrade warning";
CM_ SG_ 323 FCWSTT "China FCW status ";
CM_ SG_ 323 FCWDIR "China FCW Direction";
CM_ SG_ 323 FCWWRNMD "China FCW Warning Method";
CM_ SG_ 323 RCTADIR "China RCTA Direction";
CM_ SG_ 323 CDWSTT "China CDW Status ";
CM_ SG_ 323 CDWLV "China CDW Level";
CM_ SG_ 323 CDWWRN "China CDW Warning Display Request";
CM_ SG_ 323 AESDIR "China AES Direction";
CM_ SG_ 323 RCPMSTT "China RCPM Status ";
CM_ SG_ 323 ESSSTT "China ESS Status ";
CM_ SG_ 323 RCTASTT "China RCTA Status ";
CM_ SG_ 323 RCTBSTT "China RCTB Status ";
CM_ SG_ 323 LDWSTT "China LDW Status ";
CM_ SG_ 323 LDKSTT "China LDALKA Status ";
CM_ SG_ 323 ELKSTT "China ELK Status ";
CM_ SG_ 323 TSRSTT "China TSR Status ";
CM_ SG_ 323 IHCSTT "China IHC Status ";
CM_ SG_ 323 BSDSTT "China BSD Status ";
CM_ SG_ 323 LCASTT "China LCA Status ";
CM_ SG_ 323 DOWSTT "China DOW Status ";
CM_ SG_ 323 AEBSTT "China AEB Status ";
CM_ SG_ 323 ABSMSTT "China ABSM Status ";
CM_ SG_ 323 AESSTT "China AES Status ";
CM_ SG_ 323 RCWSTT "China RCW Status ";
CM_ SG_ 323 CSWSTT "China CSW Status ";
CM_ SG_ 323 SLFSTT "China SLIF Status ";
CM_ SG_ 323 TLASTT "China TLA Status ";
CM_ SG_ 323 LPAPFAIL "LPNP Learning with AP Abnormal State";
CM_ SG_ 323 LPNPFAIL "LPNP Abnormal State";
CM_ SG_ 323 LPNPSYS "LPNP System Avaible";
CM_ SG_ 323 LPNPONST "LPNP on / off status";
CM_ SG_ 323 PNPEXBRK "PNP Function Exit Flag";
CM_ SG_ 323 PNPFAIL "PNP Abnormal State";
CM_ SG_ 323 PNPSYS "PNP System Avaible";
CM_ SG_ 323 PNPONST "PNP on / off status";
CM_ SG_ 323 APPONST "AP on / off status";
CM_ SG_ 323 AP_LAMP "AP Taletale lamp";
CM_ SG_ 323 DMCCALB "DMC Calibration State";
CM_ SG_ 323 LPNPEXBK "LPNP Function Exit Flag";
CM_ SG_ 323 LPNPLAMP "LPNP Taletale lamp";
CM_ SG_ 323 LPNPSTS "LPNP control status";
CM_ SG_ 323 PNPSTS "PNP control status";
CM_ BO_ 515 "Reserve";
CM_ SG_ 515 GDNEXIST "Guardian2.0 existance flag";
CM_ SG_ 515 CNPFNEX "CNP function Exist Flag";
CM_ SG_ 515 FCWFNEX "FCW function Exist Flag";
CM_ SG_ 515 ELKFNEX "ELK function Exist Flag";
CM_ SG_ 515 SLFFNEX "SLIF function Exist Flag";
CM_ SG_ 515 TLAFNEX "TLA function Exist Flag";
CM_ SG_ 515 BSDFNEX "BSD function Exist Flag";
CM_ SG_ 515 ESSFNEX "ESS function Exist Flag";
CM_ SG_ 515 CSWFNEX "CSW function Exist Flag";
CM_ SG_ 515 AESFNEX "AES function Exist Flag";
CM_ SG_ 515 LDKFNEX "LDALKA function Exist Flag";
CM_ SG_ 515 CPFNEX "CP function Exist Flag";
CM_ SG_ 515 CDWFNEX "CDW function Exist Flag";
CM_ BO_ 520 "Reserve";
CM_ SG_ 520 E_CRC208 "ADC1S14 E2E_CRC";
CM_ SG_ 520 E_CNT208 "ADC1S14 E2E_CNT";
CM_ SG_ 520 ADBZRQ "Advanced Drive Buzzer Request";
CM_ SG_ 520 ADPRDTML "preDOT Melody Request";
CM_ SG_ 520 ADMMMUTE "Advanced Drive MM Mute request";
CM_ SG_ 520 ADADDREX "Advanced Drive Customization Func Info (Advanced Drive)";
CM_ SG_ 520 ADOTASEX "Advanced Drive Customization Func Info (Overtake Assistance)";
CM_ SG_ 520 ADSTMUEX "Advanced Drive Customization Func Info (Stereo Mute)";
CM_ SG_ 520 ADAUNFEX "Advanced Drive Customization Func Info (Audio Notification Frequency)";
CM_ SG_ 520 ADNTLVEX "Advanced Drive Customization Func Info (Notification Level)";
CM_ SG_ 520 ADDSLVEX "Advanced Drive Customization Func Info (Driving Support Level)";
CM_ SG_ 520 ADVOCTEX "Advanced Drive Customization Func Info (Voice Control)";
CM_ SG_ 520 ADSLDSEX "Advanced Drive Customization Func Info (Driving support level decrease notification sound)";
CM_ SG_ 520 ADDMCREX "Advanced Drive Customization Func Info (Driver Monitor Camera Recording)";
CM_ SG_ 520 ADSEGDEX "Advanced Drive Customization Func Info (Surrounding Environment Graphic Display)";
CM_ SG_ 520 ADSVSSEX "Advanced Drive Customization Func Info (Setting Vehicle Speed Suggestion)";
CM_ SG_ 520 ADCVVSEX "Advanced Drive Customization Func Info (Correction Value for Setting Vehicle Speed suggestion)";
CM_ SG_ 520 ADADDRST "Advanced Drive Customization setting (Advanced Drive)";
CM_ SG_ 520 ADOTASST "Advanced Drive Customization setting (Overtake Assistance)";
CM_ SG_ 520 ADSTMUST "Advanced Drive Customization setting (Stereo Mute)";
CM_ SG_ 520 ADAUNFST "Advanced Drive Customization setting (Audio Notification Frequency)";
CM_ SG_ 520 ADNTLVST "Advanced Drive Customization setting (Notification Level)";
CM_ SG_ 520 ADDSLVST "Advanced Drive Customization setting (Driving Support Level)";
CM_ SG_ 520 ADVOCTST "Advanced Drive Customization setting (Voice Control)";
CM_ SG_ 520 ADSLDSST "Advanced Drive Customization setting (Driving support level decrease notification sound)";
CM_ SG_ 520 ADDMCRST "Advanced Drive Customization setting (Driver Monitor Camera Recording)";
CM_ SG_ 520 ADSEGDST "Advanced Drive Customization setting (Surrounding Environment Graphic Display)";
CM_ SG_ 520 ADSVSSST "Advanced Drive Customization setting (Setting Vehicle Speed Suggestion)";
CM_ SG_ 520 ADCVVSST "Advanced Drive Customization setting (Correction Value for Setting Vehicle Speed suggestion)";
CM_ SG_ 520 ADDOTTT "Driving Operation Transition request Telltale lighting request";
CM_ SG_ 520 ADHOFEXT "Advanced Drive HandsOFF existence";
CM_ SG_ 520 ADDOTRQ "Driving Operation Transition request(Ether Interrupted)";
CM_ SG_ 520 ADHONRQ "HandsON request(Ether Interrupted)";
CM_ SG_ 520 ADADMTT "ADM Telltale lighting request";
CM_ SG_ 520 ADHOFDSP "Advanced Drive Fwindow HandsOFF Display request";
CM_ SG_ 520 ADTRJDSP "Advanced Drive Fwindow Trajectory Display request";
CM_ SG_ 520 ADLLIDSP "Advanced Drive Fwindow left line Display request";
CM_ SG_ 520 ADRLIDSP "Advanced Drive Fwindow right line Display request";
CM_ SG_ 520 MNPCUSST "MNP system state display for customization SW";
CM_ SG_ 520 RCD_DE_C "RCD Dealer Customize ON/OFF";
CM_ SG_ 520 RCDDE_ST "RCD Dealer Customize Status";
CM_ SG_ 520 FR_BRGHT "Front Camera Low / High brightness";
CM_ SG_ 520 FR_DIRT2 "Front Camera DIRT Adhesion";
CM_ SG_ 520 FR_SNOW "Front Camera Snow Adhesion";
CM_ SG_ 520 FR_RAIN "Front Camera Raindrop";
CM_ SG_ 520 FR_INVA "Front Camera Invalid";
CM_ SG_ 520 FR_FAIL "Front Camera Abnormality";
CM_ SG_ 520 RR_BRGHT "Rear Camera Low / High brightness";
CM_ SG_ 520 RR_DIRT2 "Rear Camera DIRT Adhesion";
CM_ SG_ 520 RR_SNOW "Rear Camera Snow Adhesion";
CM_ SG_ 520 RR_RAIN "Rear Camera Raindrop";
CM_ SG_ 520 RR_INVA "Rear Camera Invalid";
CM_ SG_ 520 RR_FAIL "Rear Camera Abnormality";
CM_ SG_ 520 LH_BRGHT "Left Side Camera Low / High brightness";
CM_ SG_ 520 LH_DIRT "Left Side Camera DIRT Adhesion";
CM_ SG_ 520 LH_SNOW "Left Side Camera Snow Adhesion";
CM_ SG_ 520 LH_RAIN "Left Side Camera Raindrop";
CM_ SG_ 520 LH_INVA "Left Side Camera Invalid";
CM_ SG_ 520 LH_FAIL "Left Side Camera Abnormality";
CM_ SG_ 520 RH_BRGHT "Right Side Camera Low / High brightness";
CM_ SG_ 520 RH_DIRT "Right Side Camera DIRT Adhesion";
CM_ SG_ 520 RH_SNOW "Right Side Camera Snow Adhesion";
CM_ SG_ 520 RH_RAIN "Right Side Camera Raindrop";
CM_ SG_ 520 RH_INVA "Right Side Camera Invalid";
CM_ SG_ 520 RH_FAIL "Right Side Camera Abnormality";
CM_ SG_ 520 AIPWFR1 "AI Partner Warning Factor Responce1";
CM_ SG_ 520 AIPWFR2 "AI Partner Warning Factor Responce2";
CM_ SG_ 520 AIPREQ "AI Partner Realtime Recommend Display Request";
CM_ SG_ 520 AIPRLAR "AI Partner Route Linkage ACC Recommend";
CM_ SG_ 520 AIPPROEX "AI Partner Realtime Recommend voice notice function exist";
CM_ SG_ 520 AIPPRORE "AI Partner Realtime Recommend voice notice request";
CM_ BO_ 521 "Reserve";
CM_ SG_ 521 FCWCUSST "FCW system state display for customization SW";
CM_ SG_ 521 CDWCUSST "CDW system state display for customization SW";
CM_ SG_ 521 SLFCUSST "SLIF system state display for customization SW";
CM_ SG_ 521 TLACUSST "TLA system state display for customization SW";
CM_ SG_ 521 BSDCUSST "BSD system state display for customization SW";
CM_ SG_ 521 ESSCUSST "ESS system state display for customization SW";
CM_ SG_ 521 CSWCUSST "CSW system state display for customization SW";
CM_ SG_ 521 AESCUSST "AES system state display for customization SW";
CM_ SG_ 521 HNPCUSST "HNP system state display for customization SW";
CM_ SG_ 521 UNPCUSST "UNP system state display for customization SW";
CM_ SG_ 521 LDKCUSST "LDALKA system state display for customization SW";
CM_ SG_ 521 ELKCUSST "ELK system state display for customization SW";
CM_ SG_ 521 CPCUSST "CP system state display for customization SW";
CM_ SG_ 521 HNPCSTEX "Highway Navigation Pilot Customization function information (HNP)";
CM_ SG_ 521 UNPCSTEX "Urban Navigation Pilot Customization function information (HNP)";
CM_ SG_ 521 NPLCCSEX "Lane Change confirmation customization function information(HNP/UNP/CNP)";
CM_ SG_ 521 NPCS1EX "NP customization function 1 information(HNP/UNP/CNP Nudge)";
CM_ SG_ 521 NPCS2EX "NP customization function 2 information(HNP/UNP/CNP Signal Cooperative Control)";
CM_ SG_ 521 NPCS3EX "NP customization function 3 information(HNP/UNP/CNP SAPA Suggeston)";
CM_ SG_ 521 NPCS4EX "NP customization function 4 information(HNP/UNP/CNP Voice Operation)";
CM_ SG_ 521 NPCS5EX "NP customization function 5 information(HNP/UNP/CNP Voice Interacton)";
CM_ SG_ 521 NPCS6EX "NP customization function 6 information(HNP/UNP/CNP Confidence Level)";
CM_ SG_ 521 NPCS7EX "NP customization function 7 information(HNP/UNP/CNP LC notification)";
CM_ SG_ 521 NPCS8EX "NP customization function 8 information(HNP/UNP/CNP Speed Transition)";
CM_ SG_ 521 NPCS9EX "NP customization function 9 information(HNP/UNP/CNP Speed Transition Unit)";
CM_ SG_ 521 NPCS10EX "NP customization function 10 information(HNP/UNP/CNP Driving Style)";
CM_ SG_ 521 NPCS11EX "NP customization function 11 information(HNP/UNP/CNP Lane Change Frequency)";
CM_ SG_ 521 NPCS12EX "NP customization function 12 information(HNP/UNP/CNP VLO)";
CM_ SG_ 521 NPCS13EX "NP customization function 13 information(HNP/UNP/CNP Overtake Flash)";
CM_ SG_ 521 NPCS14EX "NP customization function 14 information(HNP/UNP/CNP Horn against approaching vehicle)";
CM_ SG_ 521 NPCS15EX "NP customization function 15 information(HNP/UNP/CNPActivate suggestion)";
CM_ SG_ 521 NPCS16EX "NP customization function 16 information(HNP/UNP/CNP )";
CM_ SG_ 521 NPCS17EX "NP customization function 17 information(HNP/UNP/CNP )";
CM_ SG_ 521 NPCS18EX "NP customization function 18 information(HNP/UNP/CNP )";
CM_ SG_ 521 NPCS19EX "NP customization function 19 information(HNP/UNP/CNP )";
CM_ SG_ 521 NPCS20EX "NP customization function 20 information(HNP/UNP/CNP )";
CM_ SG_ 521 HNPCSST "Highway Navigation Pilot Customization setting (Highway Navigation Pilot)";
CM_ SG_ 521 UNPCSST "Urban Navigation Pilot Customization setting (Urban Navigation Pilot)";
CM_ SG_ 521 NPLCCSST "Lane Change Confirmation Customization Setting(HNP/UNP/CNP)";
CM_ SG_ 521 NPCS1ST "NP customization function 1 Customization Setting(HNP/UNP/CNP Nudge)";
CM_ SG_ 521 NPCS2ST "NP customization function 2 Customization Setting(HNP/UNP/CNP Signal Cooperative Control)";
CM_ SG_ 521 NPCS3ST "NP customization function 3 Customization Setting(HNP/UNP/CNP SAPA Suggeston)";
CM_ SG_ 521 NPCS4ST "NP customization function 4 Customization Setting(HNP/UNP/CNP Voice Operation)";
CM_ SG_ 521 NPCS5ST "NP customization function 5 Customization Setting(HNP/UNP/CNP Voice Interaction)";
CM_ SG_ 521 NPCS6ST "NP customization function 6 Customization Setting(HNP/UNP/CNP Confidence Level)";
CM_ SG_ 521 NPCS7ST "NP customization function 7 Customization Setting(HNP/UNP/CNP LC notification)";
CM_ SG_ 521 NPCS8ST "NP customization function 8 Customization Setting(HNP/UNP/CNP Speed Transition)";
CM_ SG_ 521 NPCS9ST "NP customization function 9 Customization Setting(HNP/UNP/CNP Speed Transition Unit)";
CM_ SG_ 521 NPCS10ST "NP customization function 10 Customization Setting(HNP/UNP/CNP Driving Style)";
CM_ SG_ 521 NPCS11ST "NP customization function 11 Customization Setting(HNP/UNP/CNP Lane Change Frequency)";
CM_ SG_ 521 NPCS12ST "NP customization function 12 Customization Setting(HNP/UNP/CNP Big Data Speed Control)";
CM_ SG_ 521 NPCS13ST "NP customization function 13 Customization Setting(HNP/UNP/CNP VLO)";
CM_ SG_ 521 NPCS14ST "NP customization function 14 Customization Setting(HNP/UNP/CNP Overtalke Flash)";
CM_ SG_ 521 NPCS15ST "NP customization function 15 Customization Setting(HNP/UNP/CNP Activate suggestion)";
CM_ SG_ 521 NPCS16ST "NP customization function 16 Customization Setting(HNP/UNP/CNP Upgrade Operation)";
CM_ SG_ 521 NPCS17ST "NP customization function 17 Customization Setting(HNP/UNP/CNP )";
CM_ SG_ 521 NPCS18ST "NP customization function 18 Customization Setting(HNP/UNP/CNP )";
CM_ SG_ 521 NPCS19ST "NP customization function 19 Customization Setting(HNP/UNP/CNP )";
CM_ SG_ 521 NPCS20ST "NP customization function 20 Customization Setting(HNP/UNP/CNP )";
CM_ SG_ 521 GDNCTEX " Guardian2.0 Customization function information";
CM_ SG_ 521 GDNCTST " Guardian2.0Customization setting";
CM_ SG_ 521 GDNWNEX " Guardian2.0 Warning Customize information";
CM_ SG_ 521 GDNWNST " Guardian2.0 Warning Customize setting";
CM_ SG_ 521 GDNBKEX " Guardian2.0 Brake Control Setting information";
CM_ SG_ 521 GDNBKST " Guardian2.0 Brake Control Setting";
CM_ SG_ 521 GDNSTEX " Guardian2.0 Steering Conrtol information";
CM_ SG_ 521 GDNSTST " Guardian2.0 Steering Conrtol setting";
CM_ SG_ 521 GDNSNEX " Guardian2.0 Sensitiveness Setting information";
CM_ SG_ 521 GDNSNST " Guardian2.0 Sensitiveness setting";
CM_ SG_ 521 FCWCTEX "China Foward Collision Warning Customization function information (Foward Collision Warning)";
CM_ SG_ 521 FCWCTST "China Foward Collision WarningCustomization setting (Foward Collision Warning)";
CM_ SG_ 521 FCWSEEX "China Foward Collision Warning Sensitiveness Customization function information (FCW Sensitiveness)";
CM_ SG_ 521 FCWSEST "China Foward Collision Warning Sensitiveness Customization setting (FCW Sensitiveness)";
CM_ SG_ 521 CDWCTEX "ChinaCDW Customization function information (CDW)";
CM_ SG_ 521 CDWCTST "ChinaCDW Customization setting (CDW)";
CM_ SG_ 521 TLACTEX "ChinaTLA Customization function information (TLA)";
CM_ SG_ 521 TLACTST "ChinaTLA Customization setting (TLA)";
CM_ SG_ 521 SLFCTEX "ChinaSLIF Customization function information ";
CM_ SG_ 521 SLFCTST "ChinaSLIF Customization setting ";
CM_ SG_ 521 CSWCTEX "ChinaCSW Customization function information (CSW)";
CM_ SG_ 521 CSWCTST "ChinaCSW Customization setting (CSW)";
CM_ SG_ 521 AESCTEX "ChinaAES Customization function information (AES)";
CM_ SG_ 521 AESCTST "ChinaAES Customization setting (AES)";
CM_ SG_ 521 ACCCTEX "ChinaACC Customization function information (ACC)";
CM_ SG_ 521 ACCCTST "ChinaACC Customization setting (ACC)";
CM_ SG_ 521 CPCTEX "ChinaCP Customization function information (CP)";
CM_ SG_ 521 CPCTST "ChinaCP Customization setting (CP)";
CM_ SG_ 521 LDKCTEX "China LDA/LKA Customization function information";
CM_ SG_ 521 LDKCTST "China LDA/LKACustomization setting";
CM_ SG_ 521 LDKSNEX "China LDA/LKA Sensitiveness Customization function information";
CM_ SG_ 521 LDKSNST "China LDA/LKA Sensitiveness Customization setting";
CM_ SG_ 521 ELKCTEX "China ELK Customization function information";
CM_ SG_ 521 ELKCTST "China ELKCustomization setting";
CM_ SG_ 521 ELKMDEX "China ELK Mode Customization function information";
CM_ SG_ 521 ELKMDST "China ELK Mode Customization setting";
CM_ SG_ 521 BSDCTEX "China BSD Customization function information";
CM_ SG_ 521 BSDCTST "China BSDCustomization setting";
CM_ SG_ 521 NPSSWEX "NP software switch exist";
CM_ SG_ 521 NPSSWST "NP software switch status";
CM_ SG_ 521 RCPMCTEX "ChinaRCPM Customization function information (RCPM)";
CM_ SG_ 521 RCPMCTST "ChinaRCPM Customization setting (RCPM)";
CM_ SG_ 521 NPDSSWEX "NP software down switch exist";
CM_ SG_ 521 NPDSSWST "NP software down switch status";
CM_ SG_ 521 ESSCTEX "China ESS Customization function information";
CM_ SG_ 521 ESSCTST "China ESS Customization setting";
CM_ SG_ 521 OVSPCEXT "RSA overspeed customization exixtence (detail)";
CM_ SG_ 521 OVSPCVAL "RSA overspeed customization value (detail)";
CM_ SG_ 521 CRNGCUST "CSR Range Customization(Fr/Rr) ON/OFF";
CM_ SG_ 521 CSRNGF "CSR Range Customization(Front) Value";
CM_ SG_ 521 CSRNGR "CSR Range Customization(Rear) Value";
CM_ SG_ 521 WDISPCST "MOA Customization ON/OFF";
CM_ SG_ 521 WDISPSTT "MOA Customization Value";
CM_ SG_ 521 MOACUST "MOA Customization ON/OFF";
CM_ SG_ 521 MOASTAT "Moving Object Display ON/OFF Value";
CM_ SG_ 521 MOAAOST "Auto-on  Alert  SW  Press Information";
CM_ SG_ 521 MNPCSTEX "Memory Navigation Pilot Customization function information (CNP)";
CM_ SG_ 521 MNPFNEX "Memory Navigation Pilot Customization setting (Memory Navigation Pilot)";
CM_ SG_ 521 MNPSSWEX "MNP software down switch exist";
CM_ SG_ 521 MNPSSWST "MNP software down switch status";
CM_ SG_ 521 HNPFNEX "HNP function Exist Flag";
CM_ SG_ 521 UNPFNEX "UNP function Exist Flag";
CM_ BO_ 384 "Reserve";
CM_ SG_ 384 CSRRDRW "CSR Re-Draw Display";
CM_ SG_ 384 CSRCICON "CSR Car Icon Display";
CM_ SG_ 384 WDSP_FLS "CSR Wall Indication Front Left Side ";
CM_ SG_ 384 WDSP_FL "CSR Wall Indication Front Left Side ";
CM_ SG_ 384 WDSP_FLC "CSR Wall Indication Front Left Side ";
CM_ SG_ 384 WDSP_FRS "CSR Wall Indication Front Right Side ";
CM_ SG_ 384 WDSP_FR "CSR Wall Indication Front Right Side ";
CM_ SG_ 384 WDSP_FRC "CSR Wall Indication Front Right Side ";
CM_ SG_ 384 WDSP_RLS "CSR Wall Indication Rear Left Side ";
CM_ SG_ 384 WDSP_RL "CSR Wall Indication Rear Left Side ";
CM_ SG_ 384 WDSP_RLC "CSR Wall Indication Rear Left Side ";
CM_ SG_ 384 WDSP_RRS "CSR Wall Indication Rear Right Side ";
CM_ SG_ 384 WDSP_RR "CSR Wall Indication Rear Right Side ";
CM_ SG_ 384 WDSP_RRC "CSR Wall Indication Rear Right Side ";
CM_ SG_ 384 WDSP_RS1 "CSR Wall Indication Right Side1 ";
CM_ SG_ 384 WDSP_RS2 "CSR Wall Indication Right Side2 ";
CM_ SG_ 384 WDSP_RS3 "CSR Wall Indication Right Side3 ";
CM_ SG_ 384 WDSP_RS4 "CSR Wall Indication Right Side4 ";
CM_ SG_ 384 WDSP_RS5 "CSR Wall Indication Right Side5 ";
CM_ SG_ 384 WDSP_RS6 "CSR Wall Indication Right Side6 ";
CM_ SG_ 384 WDSP_RS7 "CSR Wall Indication Right Side7 ";
CM_ SG_ 384 WDSP_RS8 "CSR Wall Indication Right Side8 ";
CM_ SG_ 384 WDSP_LS1 "CSR Wall Indication Left Side1 ";
CM_ SG_ 384 WDSP_LS2 "CSR Wall Indication Left Side2 ";
CM_ SG_ 384 WDSP_LS3 "CSR Wall Indication Left Side3 ";
CM_ SG_ 384 WDSP_LS4 "CSR Wall Indication Left Side4 ";
CM_ SG_ 384 WDSP_LS5 "CSR Wall Indication Left Side5 ";
CM_ SG_ 384 WDSP_LS6 "CSR Wall Indication Left Side6 ";
CM_ SG_ 384 WDSP_LS7 "CSR Wall Indication Left Side7 ";
CM_ SG_ 384 WDSP_LS8 "CSR Wall Indication Left Side8 ";
CM_ SG_ 384 WCOL_FLS "CSR Wall Indication Front Left Side Color";
CM_ SG_ 384 WCOL_FL "CSR Wall Indication Front Left Side Color";
CM_ SG_ 384 WCOL_FLC "CSR Wall Indication Front Left Side Color";
CM_ SG_ 384 WCOL_FRS "CSR Wall Indication Front Right Side Color";
CM_ SG_ 384 WCOL_FR "CSR Wall Indication Front Right Side Color";
CM_ SG_ 384 WCOL_FRC "CSR Wall Indication Front Right Side Color";
CM_ SG_ 384 WCOL_RLS "CSR Wall Indication Rear Left Side Color";
CM_ SG_ 384 WCOL_RL "CSR Wall Indication Rear Left Side Color";
CM_ SG_ 384 WCOL_RLC "CSR Wall Indication Rear Left Side Color";
CM_ SG_ 384 WCOL_RRS "CSR Wall Indication Rear Right Side Color";
CM_ SG_ 384 WCOL_RR "CSR Wall Indication Rear Right Side Color";
CM_ SG_ 384 WCOL_RRC "CSR Wall Indication Rear Right Side Color";
CM_ SG_ 384 WCOL_RS1 "CSR Wall Indication Right Side1 Color";
CM_ SG_ 384 WCOL_RS2 "CSR Wall Indication Right Side2 Color";
CM_ SG_ 384 WCOL_RS3 "CSR Wall Indication Right Side3 Color";
CM_ SG_ 384 WCOL_RS4 "CSR Wall Indication Right Side4 Color";
CM_ SG_ 384 WCOL_RS5 "CSR Wall Indication Right Side5 Color";
CM_ SG_ 384 WCOL_RS6 "CSR Wall Indication Right Side6 Color";
CM_ SG_ 384 WCOL_RS7 "CSR Wall Indication Right Side7 Color";
CM_ SG_ 384 WCOL_RS8 "CSR Wall Indication Right Side8 Color";
CM_ SG_ 384 WCOL_LS1 "CSR Wall Indication Left Side1 Color";
CM_ SG_ 384 WCOL_LS2 "CSR Wall Indication Left Side2 Color";
CM_ SG_ 384 WCOL_LS3 "CSR Wall Indication Left Side3 Color";
CM_ SG_ 384 WCOL_LS4 "CSR Wall Indication Left Side4 Color";
CM_ SG_ 384 WCOL_LS5 "CSR Wall Indication Left Side5 Color";
CM_ SG_ 384 WCOL_LS6 "CSR Wall Indication Left Side6 Color";
CM_ SG_ 384 WCOL_LS7 "CSR Wall Indication Left Side7 Color";
CM_ SG_ 384 WCOL_LS8 "CSR Wall Indication Left Side8 Color";
CM_ SG_ 384 DISCSRF "Distance of CSA front area";
CM_ SG_ 384 DISCSRR "Distance of CSA rear area";
CM_ SG_ 384 CAMERRVI "Camera Video Error";
CM_ SG_ 384 CAMERRPO "Camera Power Error";
CM_ BO_ 522 "Reserve";
CM_ SG_ 522 LTASSWEX "LTA software switch exist";
CM_ SG_ 522 LTASSWST "LTA software switch status";
CM_ SG_ 522 ADINITEX "ADAS setting initialization SW exist";
CM_ SG_ 522 ADSAFEEX "ADAS setting safety SW exist";
CM_ SG_ 522 ADALOFEX "ADAS setting all off SW exist";
CM_ SG_ 522 ADMUTEEX "ADAS setting mute SW exist";
CM_ SG_ 522 ADMDSTEX "ADAS setting modest SW exist";
CM_ SG_ 522 HMIAMBEX "HMI ambient exist";
CM_ SG_ 522 HMIAMBMD "HMI ambient mode";
CM_ SG_ 522 R_CROP_1 "Video cutout request for meter display";
CM_ SG_ 522 MD_PRE "MET display pre-notification flag";
CM_ SG_ 522 MD_AVL "Camera availability status";
CM_ SG_ 522 PVM_SPER "PVM split screen permission flag";
CM_ SG_ 522 ACCCUSST "ACC system state display for customization SW";
CM_ SG_ 522 PDACUSST "PDA system state display for customization SW";
CM_ SG_ 522 LCACUSST "LCA system state display for customization SW";
CM_ SG_ 522 TRACUSST "Trailer ADAS system state display for customization SW";
CM_ SG_ 522 ADCUSST "AD system state display for customization SW";
CM_ SG_ 522 ISACUSST "ISA system state display for customization SW";
CM_ SG_ 522 LDACUSST "LDA system state display for customization SW";
CM_ SG_ 522 PCSCUSST "PCS system state display for customization SW";
CM_ SG_ 522 FTACUSST "FCTA system state display for customization SW";
CM_ SG_ 522 BSMCUSST "BSM system state display for customization SW";
CM_ SG_ 522 SEACUSST "SEA system state display for customization SW";
CM_ SG_ 522 CSRCUSST "CSR system state display for customization SW";
CM_ SG_ 522 PSBCUSST "PKSB system state display for customization SW";
CM_ SG_ 522 RTACUSST "RCTA system state display for customization SW";
CM_ SG_ 522 RCDCUSST "RCD system state display for customization SW";
CM_ SG_ 522 SASCUSST "SAS system state display for customization SW";
CM_ SG_ 522 RSACUSST "RSA system state display for customization SW";
CM_ SG_ 522 RVACUSST "RVAI system state display for customization SW";
CM_ SG_ 522 AVSCUSST "AVS system state display for customization SW";
CM_ SG_ 522 TMNCUSST "TMN system state display for customization SW";
CM_ SG_ 522 DMSCUSST "DMS system state display for customization SW";
CM_ SG_ 522 SWSCUSST "SWS system state display for customization SW";
CM_ SG_ 522 LTACUSST "LTA system state display for customization SW";
CM_ SG_ 522 RGSTA "Regenerative Status(CAN-VP)  ";
CM_ SG_ 522 LGIDDC "Longitudinal Request ID of Driver Cooperation Arbitration Result 
(CAN-VP) ";
CM_ SG_ 522 TSS_ACCD "Request Acceleration of Driver Cooperation from TSS(CAN-VP) ";
CM_ SG_ 522 USMSENST "DA Support Level status";
CM_ SG_ 522 SDGCUSEX "SDG sensitivity customize exist";
CM_ SG_ 522 SDGSENST "SDG sensitivity status";
CM_ SG_ 522 DRADCTYP "Outputable Image Notification of ADC";
CM_ SG_ 522 ADVNRQ "Advanced Drive voice notice output request";
CM_ SG_ 522 ADVNUSG "Advanced Drive voice notice function information";
CM_ SG_ 522 HMIAMBRQ "HMI ambient request";
CM_ SG_ 522 USMEXST2 "URSM existence flag2";
CM_ SG_ 522 AECOBNFB "Effectiveness of ADAS-ECO app for display the bar";
CM_ SG_ 522 AECOBNFV "Effectiveness of ADAS-ECO app for display the value";
CM_ SG_ 522 AECOSTBB "ADAS-ECO app ON/OFF status";
CM_ SG_ 522 ADINITST "ADAS setting initialization SW status";
CM_ SG_ 522 ADSAFEST "ADAS setting safety SW status";
CM_ SG_ 522 ADALOFST "ADAS setting all off SW status";
CM_ SG_ 522 ADMUTEST "ADAS setting mute SW status";
CM_ SG_ 522 ADMDSTST "ADAS setting modest SW status";
CM_ SG_ 522 ADAS_CVI "China ADAS Voice Interaction ";
CM_ BO_ 1555 "Reserve";
CM_ SG_ 1555 USMGRN "DA Gear position (for the navigation) ";
CM_ SG_ 1555 USMDISP "DA Meter display signal";
CM_ SG_ 1555 USMMNAV "DA Navigation cooperation control implementation signal";
CM_ SG_ 1555 USMAC5 "DA Loose corner turning angle";
CM_ SG_ 1555 USMAC6 "DA Middle corner turning angle";
CM_ SG_ 1555 USMAC7 "DA Hairpin corner turning angle";
CM_ SG_ 1555 USMGSS "DA Deceleration line";
CM_ SG_ 1555 USMIDOF "DA Off switch display";
CM_ SG_ 1555 USMIDST "DA Meter display switch indication";
CM_ SG_ 1555 USMISTR "DA Strength switch display indication";
CM_ SG_ 1555 USMSST "DA Connection confirmation signal";
CM_ BO_ 455 "Reserve";
CM_ SG_ 455 EDADNUM "Event Num";
CM_ SG_ 455 EDADID1 "Event ID (1)";
CM_ SG_ 455 EDADTS1 "Event TimeStamp (1)";
CM_ SG_ 455 EDADID2 "Event ID (2)";
CM_ SG_ 455 EDADTS2 "Event TimeStamp (2)";
CM_ SG_ 455 EDADID3 "Event ID (3)";
CM_ SG_ 455 EDADTS3 "Event TimeStamp (3)";
CM_ SG_ 455 EDADID4 "Event ID (4)";
CM_ SG_ 455 EDADTS4 "Event TimeStamp (4)";
CM_ SG_ 455 EDADMID5 "Event ID (5)";
CM_ SG_ 455 EDADTS5 "Event TimeStamp (5)";
CM_ SG_ 455 EDADID6 "Event ID (6)";
CM_ SG_ 455 EDADTS6 "Event TimeStamp (6)";
CM_ BO_ 324 "Reserve";
CM_ SG_ 324 WS_VD_R "Visual Distraction Warning Sensitivity SW Operation Result";
CM_ SG_ 324 WS_FTG_R "Fatigue Warning Sensitivity SW Operation Result";
CM_ SG_ 324 WS_ABH_R "Abnormal Behavior Warning Sensitivity SW Operation Result";
CM_ SG_ 324 WS_APO_R "Abnormal Driver's Posture Warning Sensitivity SW Operation Result";
CM_ BO_ 583 "Reserve";
CM_ SG_ 583 DTG15 "Establishment status of DDR trigger ID 15";
CM_ SG_ 583 DTG16 "Establishment status of DDR trigger ID 16";
CM_ SG_ 583 DTG18_04 "Establishment status of DDR trigger ID 18-4";
CM_ SG_ 583 DTG18_05 "Establishment status of DDR trigger ID 18-5";
CM_ SG_ 583 DTG19 "Establishment status of DDR trigger ID 19";
CM_ SG_ 583 DTG20_02 "Establishment status of DDR trigger ID 20-2";
CM_ SG_ 583 DTG20_03 "Establishment status of DDR trigger ID 20-3";
CM_ SG_ 583 DTG23 "Establishment status of DDR trigger ID 23";
CM_ SG_ 583 DTG25 "Establishment status of DDR trigger ID 25";
CM_ SG_ 583 DTG27 "Establishment status of DDR trigger ID 27";
CM_ SG_ 583 DTG30 "Establishment status of DDR trigger ID 30";
CM_ SG_ 583 DTG34 "Establishment status of DDR trigger ID 34";
CM_ BO_ 501 "Reserve";
CM_ SG_ 501 ACCMAPP "Map ACC active application";
CM_ SG_ 501 ACCMMOD "Map ACC Operational mode";
CM_ BO_ 496 "Reserve";
CM_ SG_ 496 ACCMDST "Map ACC landmark distance";
CM_ SG_ 496 ACCMPHS "Map ACC system phase";
CM_ SG_ 496 ACCMSGN "Map ACC landmark type judgement status";
CM_ SG_ 496 ACCMRCG "Map ACC landmark distance recognition source";
CM_ SG_ 496 ACCMARB "Map ACC deceleration request arbitration result flag";
CM_ BO_ 558 "Reserve";
CM_ SG_ 558 LDASTATL "LDA System Status Left";
CM_ SG_ 558 LDASTATR "LDA System Status Right";
CM_ SG_ 558 LDARSN "LDA System State Transition Reason";
CM_ SG_ 558 FCMINTMP "FCM Inner Temperature (High)";
CM_ SG_ 558 LDARCGL "LDA Recognition Status Left";
CM_ SG_ 558 LDARCGR "LDA Recognition Status Right";
CM_ SG_ 558 SWSSTAT "SWS System Status";
CM_ SG_ 558 V_IDACCL "IDA cancel reason(CAN300)";
CM_ SG_ 558 EJDEVPRD "EJ deviation prediction";
CM_ SG_ 558 EJLDACP "EJ-LDA cooperation status";
CM_ SG_ 558 V_IDANOA "IDA no active reason(CAN300)";
CM_ SG_ 558 V_IDARGL "IDA lane recognition status(CAN300)";
CM_ SG_ 558 PV_AREA "Frontal projected area of Preceding Vehicle";
CM_ SG_ 558 DM_PVMVW "Displaying PVM view type";
CM_ SG_ 558 DM_PVMCS "PVM customize value";
CM_ SG_ 558 ERMCNTST "Control state of ACC-EcoRunMode";
CM_ SG_ 558 GAE_H_R3 "FRD Beam axis error STD3(H)  ";
CM_ SG_ 558 FRDHTR_G "FRD Heater status";
CM_ SG_ 558 SDIRT_G "FRD sensor dirt";
CM_ SG_ 558 GAE_V_R1 "FRD Beam axis error STD1(V) Recognition";
CM_ SG_ 558 DRTCNT_G "FRD Dirt Counter";
CM_ SG_ 558 GAERR1_V "FRD Beam axis error1(V) Recognition";
CM_ SG_ 558 GAEVAL_H "FRD Beam axis corrected value (H)";
CM_ SG_ 558 GAERR3_H "FRD Beam axis error3(H)  ";
CM_ SG_ 558 DTSSSTR "Request Pinion Angle from ADAS (Data Collection)";
CM_ SG_ 558 DTSSLTID "Lateral Request ID from TSS (Data Collection)";
CM_ SG_ 558 MDSYNC00 "MDC Sync Conunter (CAN300)";
CM_ BO_ 353 "Reserve";
CM_ SG_ 353 MDCTRGID "MDC Trigger ID";
CM_ SG_ 353 CAMTYPE "Camera type";
CM_ SG_ 353 CAMPOS_X "Camera position _X";
CM_ SG_ 353 CAMPOS_Y "Camera position _Y";
CM_ SG_ 353 CAMPOS_Z "Camera position _Z";
CM_ SG_ 353 CAMROT_X "Camera rotation _X";
CM_ SG_ 353 CAMROT_Y "Camera rotation _Y";
CM_ SG_ 353 CAMROT_Z "Camera rotation _Z";
CM_ SG_ 353 CAMFOC_X "Camera focal length _X";
CM_ SG_ 353 CAMFOC_Y "Camera focal length _Y";
CM_ SG_ 353 CAMDTC_1 "Camera distortion coef 1";
CM_ SG_ 353 CAMDTC_2 "MDC Event State A";
CM_ SG_ 353 CAMDTC_3 "MDC Event State B";
CM_ SG_ 353 CAM_C_X "Camera principal point _X";
CM_ SG_ 353 CAM_C_Y "Camera principal point _Y";
CM_ BO_ 354 "Reserve";
CM_ SG_ 354 MDSYNC01 "MDC Sync Conunter";
CM_ SG_ 354 MDVSN01 "MDC collect data 207";
CM_ SG_ 354 MDVSN02 "MDC collect data 208";
CM_ SG_ 354 MDVSN03 "MDC collect data 209";
CM_ SG_ 354 MDVSN04 "MDC collect data 210";
CM_ SG_ 354 MDVSN05 "MDC collect data 211";
CM_ SG_ 354 MDVSN06 "MDC collect data 212";
CM_ SG_ 354 MDVSN07 "MDC collect data 213";
CM_ SG_ 354 MDVSN08 "MDC collect data 214";
CM_ SG_ 354 MDVSN09 "MDC collect data 215";
CM_ SG_ 354 MDVSN10 "MDC collect data 216";
CM_ SG_ 354 MDVSN11 "MDC collect data 217";
CM_ SG_ 354 MDVSN12 "MDC collect data 218";
CM_ SG_ 354 MDVSN13 "MDC collect data 219";
CM_ SG_ 354 MDVSN14 "MDC collect data 220";
CM_ SG_ 354 MDVSN15 "MDC collect data 221";
CM_ SG_ 354 MDVSN16 "MDC collect data 222";
CM_ SG_ 354 MDVSN17 "MDC collect data 223";
CM_ SG_ 354 MDVSN18 "MDC collect data 224";
CM_ SG_ 354 MDVSN19 "MDC collect data 225";
CM_ SG_ 354 MDVSN20 "MDC collect data 226";
CM_ SG_ 354 MDVSN21 "MDC collect data 227";
CM_ SG_ 354 MDVSN22 "MDC collect data 228";
CM_ SG_ 354 MDVSN23 "MDC collect data 229";
CM_ SG_ 354 MDVSN24 "MDC collect data 230";
CM_ SG_ 354 MDVSN25 "MDC collect data 231";
CM_ SG_ 354 MDVSN26 "MDC collect data 232";
CM_ SG_ 354 MDVSN27 "MDC collect data 233";
CM_ SG_ 354 MDVSN28 "MDC collect data 234";
CM_ SG_ 354 MDVSN29 "MDC collect data 235";
CM_ SG_ 354 MDVSN30 "MDC collect data 236";
CM_ SG_ 354 MDVSN31 "MDC collect data 237";
CM_ BO_ 355 "Reserve";
CM_ SG_ 355 MDSYNC02 "MDC Sync Conunter";
CM_ SG_ 355 PV0STROL "PVM0 static roll";
CM_ SG_ 355 PV0STPIT "PVM0 static pitch";
CM_ SG_ 355 PV0STYAW "PVM0 static yaw";
CM_ SG_ 355 PV1STROL "MDC collect data S1";
CM_ SG_ 355 PV1STPIT "MDC collect data S2";
CM_ SG_ 355 PV1STYAW "MDC collect data S3";
CM_ SG_ 355 PV2STROL "MDC collect data S4";
CM_ SG_ 355 PV2STPIT "MDC collect data S5";
CM_ SG_ 355 PV2STYAW "MDC collect data S6";
CM_ SG_ 355 PV3STROL "MDC collect data S7";
CM_ SG_ 355 PV3STPIT "MDC collect data S8";
CM_ SG_ 355 PV3STYAW "MDC collect data S9";
CM_ SG_ 355 MDCDT187 "MDC collect data 187";
CM_ SG_ 355 MDCDT188 "MDC collect data 188";
CM_ SG_ 355 MDCDT189 "MDC collect data 189";
CM_ SG_ 355 MDCDT190 "MDC collect data 190";
CM_ SG_ 355 MDCDT191 "MDC collect data 191";
CM_ SG_ 355 MDCDT192 "MDC collect data 192";
CM_ SG_ 355 MDCDT193 "MDC collect data 193";
CM_ BO_ 358 "Reserve";
CM_ SG_ 358 MDSYNC03 "MDC Sync Conunter";
CM_ SG_ 358 FCMSTROL "FCM static roll";
CM_ SG_ 358 FCMSTPIT "FCM static pitch";
CM_ SG_ 358 FCMSTYAW "FCM static yaw";
CM_ SG_ 358 FCMDYROL "MDC collect data S10";
CM_ SG_ 358 FCMDYPIT "MDC collect data S11";
CM_ SG_ 358 FCMDYYAW "MDC collect data S12";
CM_ SG_ 358 PVMDYROL "MDC collect data S13";
CM_ SG_ 358 PVMDYPIT "MDC collect data S14";
CM_ SG_ 358 PVMDYYAW "MDC collect data S15";
CM_ SG_ 358 MDCDT194 "MDC collect data 194";
CM_ SG_ 358 MDCDT195 "MDC collect data 195";
CM_ SG_ 358 MDCDT196 "MDC collect data 196";
CM_ SG_ 358 MDCDT197 "MDC collect data 197";
CM_ SG_ 358 MDCDT198 "MDC collect data 198";
CM_ SG_ 358 MDCDT199 "MDC collect data 199";
CM_ SG_ 358 MDCDT200 "MDC collect data 200";
CM_ SG_ 358 MDCDT201 "MDC collect data 201";
CM_ SG_ 358 MDCDT202 "MDC collect data 202";
CM_ SG_ 358 MDCDT203 "MDC collect data 203";
CM_ SG_ 358 MDCDT204 "MDC collect data 204";
CM_ SG_ 358 MDCDT205 "MDC collect data 205";
CM_ SG_ 358 MDCDT206 "MDC collect data 206";
CM_ BO_ 359 "Reserve";
CM_ SG_ 359 MDACCDST "MDC ACC target time";
CM_ SG_ 359 MDSYNC04 "MDC Sync Conunter";
CM_ SG_ 359 MDTRPCNT "MDC trip count";
CM_ SG_ 359 MDTMCNT "MDC time count";
CM_ SG_ 359 MDEGOVEL "MDC Speed";
CM_ SG_ 359 MDEGOGX "MDC G x-axis";
CM_ SG_ 359 MDEGOGY "MDC G y-axis";
CM_ SG_ 359 MDEGOASZ "MDC yawrate";
CM_ SG_ 359 MDADSST "MDC ADAS state";
CM_ SG_ 359 MDADSSW "MDC lamp switch state";
CM_ SG_ 359 MDSFTPS "MDC shift_pos";
CM_ SG_ 359 MDDRVMD "MDC drive mode";
CM_ SG_ 359 MDEGOLCS "MDC lane_change_state";
CM_ SG_ 359 MDDRVTSW "MDC turn switch";
CM_ SG_ 359 MDACCSPD "MDC ACC velocity memory";
CM_ SG_ 359 MDEGOAOP "MDC Accel opening";
CM_ SG_ 359 MDEGOBRK "MDC Brake Force";
CM_ SG_ 359 MDEGOANG "MDC Pinion Angle";
CM_ SG_ 359 MDDRVACC "MDC Accel peddal by driver";
CM_ SG_ 359 MDDRVBRK "MDC brake peddal by driver";
CM_ SG_ 359 MDDRVSTR "MDC driver steer torque";
CM_ SG_ 359 MDDRVTCH "MDC steer touch state";
CM_ SG_ 359 MDTRNL "MDC turn_lamp";
CM_ SG_ 359 MDHZDL "MDC hzd_lamp";
CM_ SG_ 359 MDBRKL "MDC break_lamp";
CM_ BO_ 360 "Reserve";
CM_ SG_ 360 MDSYNC05 "MDC Sync Conunter";
CM_ SG_ 360 MDCDT001 "MDC collect data 001";
CM_ SG_ 360 MDCDT002 "MDC collect data 002";
CM_ SG_ 360 MDCDT003 "MDC collect data 003";
CM_ SG_ 360 MDCDT004 "MDC collect data 004";
CM_ SG_ 360 MDCDT005 "MDC collect data 005";
CM_ SG_ 360 MDCDT006 "MDC collect data 006";
CM_ SG_ 360 MDCDT007 "MDC collect data 007";
CM_ SG_ 360 MDCDT008 "MDC collect data 008";
CM_ SG_ 360 MDCDT009 "MDC collect data 009";
CM_ SG_ 360 MDCDT010 "MDC collect data 010";
CM_ SG_ 360 MDCDT011 "MDC collect data 011";
CM_ SG_ 360 MDCDT012 "MDC collect data 012";
CM_ SG_ 360 MDCDT013 "MDC collect data 013";
CM_ SG_ 360 MDCDT014 "MDC collect data 014";
CM_ SG_ 360 MDCDT015 "MDC collect data 015";
CM_ SG_ 360 MDCDT016 "MDC collect data 016";
CM_ SG_ 360 MDCDT017 "MDC collect data 017";
CM_ SG_ 360 MDCDT018 "MDC collect data 018";
CM_ SG_ 360 MDCDT019 "MDC collect data 019";
CM_ SG_ 360 MDCDT020 "MDC collect data 020";
CM_ SG_ 360 MDCDT021 "MDC collect data 021";
CM_ SG_ 360 MDCDT022 "MDC collect data 022";
CM_ SG_ 360 MDCDT023 "MDC collect data 023";
CM_ SG_ 360 MDCDT024 "MDC collect data 024";
CM_ SG_ 360 MDCDT025 "MDC collect data 025";
CM_ SG_ 360 MDCDT026 "MDC collect data 026";
CM_ SG_ 360 MDCDT027 "MDC collect data 027";
CM_ SG_ 360 MDCDT028 "MDC collect data 028";
CM_ SG_ 360 MDCDT029 "MDC collect data 029";
CM_ SG_ 360 MDCDT030 "MDC collect data 030";
CM_ SG_ 360 MDCDT031 "MDC collect data 031";
CM_ BO_ 361 "Reserve";
CM_ SG_ 361 MDSYNC06 "MDC Sync Conunter";
CM_ SG_ 361 MDCDT032 "MDC collect data 032";
CM_ SG_ 361 MDCDT033 "MDC collect data 033";
CM_ SG_ 361 MDCDT034 "MDC collect data 034";
CM_ SG_ 361 MDCDT035 "MDC collect data 035";
CM_ SG_ 361 MDCDT036 "MDC collect data 036";
CM_ SG_ 361 MDCDT037 "MDC collect data 037";
CM_ SG_ 361 MDCDT038 "MDC collect data 038";
CM_ SG_ 361 MDCDT039 "MDC collect data 039";
CM_ SG_ 361 MDCDT040 "MDC collect data 040";
CM_ SG_ 361 MDCDT041 "MDC collect data 041";
CM_ SG_ 361 MDCDT042 "MDC collect data 042";
CM_ SG_ 361 MDCDT043 "MDC collect data 043";
CM_ SG_ 361 MDCDT044 "MDC collect data 044";
CM_ SG_ 361 MDCDT045 "MDC collect data 045";
CM_ SG_ 361 MDCDT046 "MDC collect data 046";
CM_ SG_ 361 MDCDT047 "MDC collect data 047";
CM_ SG_ 361 MDCDT048 "MDC collect data 048";
CM_ SG_ 361 MDCDT049 "MDC collect data 049";
CM_ SG_ 361 MDCDT050 "MDC collect data 050";
CM_ SG_ 361 MDCDT051 "MDC collect data 051";
CM_ SG_ 361 MDCDT052 "MDC collect data 052";
CM_ SG_ 361 MDCDT053 "MDC collect data 053";
CM_ SG_ 361 MDCDT054 "MDC collect data 054";
CM_ SG_ 361 MDCDT055 "MDC collect data 055";
CM_ SG_ 361 MDCDT056 "MDC collect data 056";
CM_ SG_ 361 MDCDT057 "MDC collect data 057";
CM_ SG_ 361 MDCDT058 "MDC collect data 058";
CM_ SG_ 361 MDCDT059 "MDC collect data 059";
CM_ SG_ 361 MDCDT060 "MDC collect data 060";
CM_ SG_ 361 MDCDT061 "MDC collect data 061";
CM_ SG_ 361 MDCDT062 "MDC collect data 062";
CM_ BO_ 362 "Reserve";
CM_ SG_ 362 MDSYNC07 "MDC Sync Conunter";
CM_ SG_ 362 MDCDT063 "MDC collect data 063";
CM_ SG_ 362 MDCDT064 "MDC collect data 064";
CM_ SG_ 362 MDCDT065 "MDC collect data 065";
CM_ SG_ 362 MDCDT066 "MDC collect data 066";
CM_ SG_ 362 MDCDT067 "MDC collect data 067";
CM_ SG_ 362 MDCDT068 "MDC collect data 068";
CM_ SG_ 362 MDCDT069 "MDC collect data 069";
CM_ SG_ 362 MDCDT070 "MDC collect data 070";
CM_ SG_ 362 MDCDT071 "MDC collect data 071";
CM_ SG_ 362 MDCDT072 "MDC collect data 072";
CM_ SG_ 362 MDCDT073 "MDC collect data 073";
CM_ SG_ 362 MDCDT074 "MDC collect data 074";
CM_ SG_ 362 MDCDT075 "MDC collect data 075";
CM_ SG_ 362 MDCDT076 "MDC collect data 076";
CM_ SG_ 362 MDCDT077 "MDC collect data 077";
CM_ SG_ 362 MDCDT078 "MDC collect data 078";
CM_ SG_ 362 MDCDT079 "MDC collect data 079";
CM_ SG_ 362 MDCDT080 "MDC collect data 080";
CM_ SG_ 362 MDCDT081 "MDC collect data 081";
CM_ SG_ 362 MDCDT082 "MDC collect data 082";
CM_ SG_ 362 MDCDT083 "MDC collect data 083";
CM_ SG_ 362 MDCDT084 "MDC collect data 084";
CM_ SG_ 362 MDCDT085 "MDC collect data 085";
CM_ SG_ 362 MDCDT086 "MDC collect data 086";
CM_ SG_ 362 MDCDT087 "MDC collect data 087";
CM_ SG_ 362 MDCDT088 "MDC collect data 088";
CM_ SG_ 362 MDCDT089 "MDC collect data 089";
CM_ SG_ 362 MDCDT090 "MDC collect data 090";
CM_ SG_ 362 MDCDT091 "MDC collect data 091";
CM_ SG_ 362 MDCDT092 "MDC collect data 092";
CM_ SG_ 362 MDCDT093 "MDC collect data 093";
CM_ BO_ 363 "Reserve";
CM_ SG_ 363 MDSYNC08 "MDC Sync Conunter";
CM_ SG_ 363 MDCDT094 "MDC collect data 094";
CM_ SG_ 363 MDCDT095 "MDC collect data 095";
CM_ SG_ 363 MDCDT096 "MDC collect data 096";
CM_ SG_ 363 MDCDT097 "MDC collect data 097";
CM_ SG_ 363 MDCDT098 "MDC collect data 098";
CM_ SG_ 363 MDCDT099 "MDC collect data 099";
CM_ SG_ 363 MDCDT100 "MDC collect data 100";
CM_ SG_ 363 MDCDT101 "MDC collect data 101";
CM_ SG_ 363 MDCDT102 "MDC collect data 102";
CM_ SG_ 363 MDCDT103 "MDC collect data 103";
CM_ SG_ 363 MDCDT104 "MDC collect data 104";
CM_ SG_ 363 MDCDT105 "MDC collect data 105";
CM_ SG_ 363 MDCDT106 "MDC collect data 106";
CM_ SG_ 363 MDCDT107 "MDC collect data 107";
CM_ SG_ 363 MDCDT108 "MDC collect data 108";
CM_ SG_ 363 MDCDT109 "MDC collect data 109";
CM_ SG_ 363 MDCDT110 "MDC collect data 110";
CM_ SG_ 363 MDCDT111 "MDC collect data 111";
CM_ SG_ 363 MDCDT112 "MDC collect data 112";
CM_ SG_ 363 MDCDT113 "MDC collect data 113";
CM_ SG_ 363 MDCDT114 "MDC collect data 114";
CM_ SG_ 363 MDCDT115 "MDC collect data 115";
CM_ SG_ 363 MDCDT116 "MDC collect data 116";
CM_ SG_ 363 MDCDT117 "MDC collect data 117";
CM_ SG_ 363 MDCDT118 "MDC collect data 118";
CM_ SG_ 363 MDCDT119 "MDC collect data 119";
CM_ SG_ 363 MDCDT120 "MDC collect data 120";
CM_ SG_ 363 MDCDT121 "MDC collect data 121";
CM_ SG_ 363 MDCDT122 "MDC collect data 122";
CM_ SG_ 363 MDCDT123 "MDC collect data 123";
CM_ SG_ 363 MDCDT124 "MDC collect data 124";
CM_ BO_ 364 "Reserve";
CM_ SG_ 364 MDSYNC09 "MDC Sync Conunter";
CM_ SG_ 364 MDCDT125 "MDC collect data 125";
CM_ SG_ 364 MDCDT126 "MDC collect data 126";
CM_ SG_ 364 MDCDT127 "MDC collect data 127";
CM_ SG_ 364 MDCDT128 "MDC collect data 128";
CM_ SG_ 364 MDCDT129 "MDC collect data 129";
CM_ SG_ 364 MDCDT130 "MDC collect data 130";
CM_ SG_ 364 MDCDT131 "MDC collect data 131";
CM_ SG_ 364 MDCDT132 "MDC collect data 132";
CM_ SG_ 364 MDCDT133 "MDC collect data 133";
CM_ SG_ 364 MDCDT134 "MDC collect data 134";
CM_ SG_ 364 MDCDT135 "MDC collect data 135";
CM_ SG_ 364 MDCDT136 "MDC collect data 136";
CM_ SG_ 364 MDCDT137 "MDC collect data 137";
CM_ SG_ 364 MDCDT138 "MDC collect data 138";
CM_ SG_ 364 MDCDT139 "MDC collect data 139";
CM_ SG_ 364 MDCDT140 "MDC collect data 140";
CM_ SG_ 364 MDCDT141 "MDC collect data 141";
CM_ SG_ 364 MDCDT142 "MDC collect data 142";
CM_ SG_ 364 MDCDT143 "MDC collect data 143";
CM_ SG_ 364 MDCDT144 "MDC collect data 144";
CM_ SG_ 364 MDCDT145 "MDC collect data 145";
CM_ SG_ 364 MDCDT146 "MDC collect data 146";
CM_ SG_ 364 MDCDT147 "MDC collect data 147";
CM_ SG_ 364 MDCDT148 "MDC collect data 148";
CM_ SG_ 364 MDCDT149 "MDC collect data 149";
CM_ SG_ 364 MDCDT150 "MDC collect data 150";
CM_ SG_ 364 MDCDT151 "MDC collect data 151";
CM_ SG_ 364 MDCDT152 "MDC collect data 152";
CM_ SG_ 364 MDCDT153 "MDC collect data 153";
CM_ SG_ 364 MDCDT154 "MDC collect data 154";
CM_ SG_ 364 MDCDT155 "MDC collect data 155";
CM_ BO_ 365 "Reserve";
CM_ SG_ 365 MDSYNC10 "MDC Sync Conunter";
CM_ SG_ 365 MDCDT156 "MDC collect data 156";
CM_ SG_ 365 MDCDT157 "MDC collect data 157";
CM_ SG_ 365 MDCDT158 "MDC collect data 158";
CM_ SG_ 365 MDCDT159 "MDC collect data 159";
CM_ SG_ 365 MDCDT160 "MDC collect data 160";
CM_ SG_ 365 MDCDT161 "MDC collect data 161";
CM_ SG_ 365 MDCDT162 "MDC collect data 162";
CM_ SG_ 365 MDCDT163 "MDC collect data 163";
CM_ SG_ 365 MDCDT164 "MDC collect data 164";
CM_ SG_ 365 MDCDT165 "MDC collect data 165";
CM_ SG_ 365 MDCDT166 "MDC collect data 166";
CM_ SG_ 365 MDCDT167 "MDC collect data 167";
CM_ SG_ 365 MDCDT168 "MDC collect data 168";
CM_ SG_ 365 MDCDT169 "MDC collect data 169";
CM_ SG_ 365 MDCDT170 "MDC collect data 170";
CM_ SG_ 365 MDCDT171 "MDC collect data 171";
CM_ SG_ 365 MDCDT172 "MDC collect data 172";
CM_ SG_ 365 MDCDT173 "MDC collect data 173";
CM_ SG_ 365 MDCDT174 "MDC collect data 174";
CM_ SG_ 365 MDCDT175 "MDC collect data 175";
CM_ SG_ 365 MDCDT176 "MDC collect data 176";
CM_ SG_ 365 MDCDT177 "MDC collect data 177";
CM_ SG_ 365 MDCDT178 "MDC collect data 178";
CM_ SG_ 365 MDCDT179 "MDC collect data 179";
CM_ SG_ 365 MDCDT180 "MDC collect data 180";
CM_ SG_ 365 MDCDT181 "MDC collect data 181";
CM_ SG_ 365 MDCDT182 "MDC collect data 182";
CM_ SG_ 365 MDCDT183 "MDC collect data 183";
CM_ SG_ 365 MDCDT184 "MDC collect data 184";
CM_ SG_ 365 MDCDT185 "MDC collect data 185";
CM_ SG_ 365 MDCDT186 "MDC collect data 186";
CM_ BO_ 114 "Reserve";
CM_ SG_ 114 ARANGINV "DRS angle invalidation";
CM_ SG_ 114 ARSANG "DRS angle";
CM_ SG_ 114 ARSF "DRS angle detection system fail";
CM_ SG_ 114 ARSSYS "DRS Status for IPA";
CM_ BO_ 902 "Reserve";
CM_ SG_ 902 ANS "NAVI Answer";
CM_ SG_ 902 FLYNOP "Operating Information for Registration/Deletion Menu";
CM_ SG_ 902 FLGPSOP "Operating Information for GPS-Linked Function SW";
CM_ SG_ 902 FLADELOP "Operation Information for All Stored Locations Deletion SW";
CM_ SG_ 902 CRS1 "Crossing";
CM_ SG_ 902 RQAC "Required deceleration";
CM_ SG_ 902 GUID "Route guidance";
CM_ SG_ 902 GYRO "turning detection with Gyro";
CM_ SG_ 902 NCRN "Sharp curve";
CM_ SG_ 902 CRN6 "Middle curve";
CM_ SG_ 902 CRN5 "Gentle curve";
CM_ SG_ 902 CRN3 "Curve area3";
CM_ SG_ 902 CRN2 "Curve area2";
CM_ SG_ 902 CRN1 "Curve area1";
CM_ SG_ 902 CONFID03 "Confidence ID 03";
CM_ SG_ 902 CURV "Turn direction";
CM_ SG_ 902 CVST "Curve area";
CM_ SG_ 902 NAVI_STR "Control strength";
CM_ SG_ 902 MIND "Meter indicator";
CM_ SG_ 902 ONOFF "Control ONOFF";
CM_ SG_ 902 HWPB "Highway probability";
CM_ SG_ 902 RAD "Radius";
CM_ SG_ 902 USMANS "DA NAVI Answer";
CM_ SG_ 902 SLJ "SL change mode object area judgment";
CM_ SG_ 902 SLUS "SL change mode User Setting";
CM_ SG_ 902 AFS_SW "AFS ONOFF SW";
CM_ SG_ 902 AVS_SW "AVS ONOFF SW";
CM_ BO_ 905 "Reserve";
CM_ SG_ 905 BZ_M_SW "Buzzer Mute SW";
CM_ SG_ 905 CS_R_SW "CSR Redraw SW";
CM_ SG_ 905 BM "With or Without BM Function";
CM_ SG_ 905 SUR_STAT "Surround State";
CM_ SG_ 905 NOP_YN "With or Without Number Plate";
CM_ SG_ 905 NOP_CO "Number Plate Color";
CM_ SG_ 905 NOP_P "Number Plate Province";
CM_ SG_ 905 NOP_CI "Number Plate City";
CM_ SG_ 905 NOP_S1 "Number Plate Specific Code 1";
CM_ SG_ 905 NOP_S2 "Number Plate Specific Code 2";
CM_ SG_ 905 NOP_S3 "Number Plate Specific Code 3";
CM_ SG_ 905 NOP_S4 "Number Plate Specific Code 4";
CM_ SG_ 905 NOP_S5 "Number Plate Specific Code 5";
CM_ SG_ 905 NOP_S6 "Number Plate Specific Code 6";
CM_ BO_ 383 "Reserve";
CM_ SG_ 383 FES_ST "Foresight Status";
CM_ SG_ 383 INTEG_ST "Integration Status";
CM_ SG_ 383 FSCTEVLV "FES Section EV Level";
CM_ SG_ 383 FTIME_C "Foresight time Counter";
CM_ SG_ 383 FSCTEN_F "FES Section End Flag";
CM_ SG_ 383 FGUID_F "FES Guide Flag";
CM_ SG_ 383 FONRT_F "FES On Route Flag";
CM_ SG_ 383 FSCTDPW "FES Section Driving Power";
CM_ SG_ 383 FSCTSPD "FES Section Speed";
CM_ SG_ 383 FSCTJAM "FES Section Jam";
CM_ SG_ 383 FSCT_NO "FES Section No";
CM_ SG_ 383 FSCTROAD "FES Section Road Class";
CM_ SG_ 383 FSCTTM_F "Fes Section Time Flag";
CM_ SG_ 383 FSCTDST "FES Section Distance";
CM_ SG_ 383 FSCTSLP "FES Section Slope";
CM_ BO_ 1070 "Reserve";
CM_ SG_ 1070 FCSCT_NO "FES Current Section No";
CM_ SG_ 1070 ML_F "ML ON/OFF Flag";
CM_ SG_ 1070 MLOPR_ST "ML Operation Restriction Status";
CM_ SG_ 1070 FCSCTDST "FES Current Section Distance";
CM_ SG_ 1070 ROUTE_C "Route Counter";
CM_ SG_ 1070 GEO_F "GEO ON/OFF Flag";
CM_ SG_ 1070 CSCT_C "Current Section Counter";
CM_ SG_ 1070 DESTDST "Destination Distance";
CM_ SG_ 1070 NDEST_NO "Nearest Destination Section No";
CM_ SG_ 1070 TH_TIME "Throw Time";
CM_ SG_ 1070 TH_C "Throw Counter";
CM_ SG_ 1070 RE_TIME "Receive Time";
CM_ SG_ 1070 RE_C "Receive Counter";
CM_ BO_ 294 "Reserve";
CM_ SG_ 294 S_F "Short ON/OFF  Flag";
CM_ SG_ 294 ASTATUS "Status";
CM_ SG_ 294 SRPL_C "Short Reply Counter";
CM_ SG_ 294 AAVESLP "Average Slope";
CM_ SG_ 294 ADIST "Distance";
CM_ SG_ 294 AAVSLPDF "Average Slope Difference Flag";
CM_ SG_ 294 ATGTSPD "Target speed at the target position";
CM_ SG_ 294 FRNAVL "Status Available for Freerun";
CM_ SG_ 294 SOPR_ST "Short Operation Restriction Status";
CM_ SG_ 294 MLNLFE_C "ML NAVI Life Counter";
CM_ SG_ 294 MMEVLV "MM EV Level";
CM_ SG_ 294 MMTM_F "MM Time Flag";
CM_ BO_ 508 "Reserve";
CM_ SG_ 508 NSPDTYP1 "Navigation speed type 1";
CM_ SG_ 508 NSPDVAL1 "Navigation speed value 1";
CM_ SG_ 508 NSPLSGN1 "Navigation supplemental sign 1";
CM_ SG_ 508 NSPDTYP2 "Navigation speed type 2";
CM_ SG_ 508 NSPDVAL2 "Navigation speed value 2";
CM_ SG_ 508 NSPLSGN2 "Navigation supplemental sign 2";
CM_ SG_ 508 NSPDTYP3 "Navigation speed type 3";
CM_ SG_ 508 NSPDVAL3 "Navigation speed value 3";
CM_ SG_ 508 NSPLSGN3 "Navigation supplemental sign 3";
CM_ SG_ 508 NSYNCID1 "Navigation synchronized ID 1";
CM_ BO_ 509 "Reserve";
CM_ SG_ 509 NSPDTYP4 "Navigation speed type 4";
CM_ SG_ 509 NSPDVAL4 "Navigation speed value 4";
CM_ SG_ 509 NSPLSGN4 "Navigation supplemental sign 4";
CM_ SG_ 509 NSPDTYP5 "Navigation speed type 5";
CM_ SG_ 509 NSPDVAL5 "Navigation speed value 5";
CM_ SG_ 509 NSPLSGN5 "Navigation supplemental sign 5";
CM_ SG_ 509 NSPDTYP6 "Navigation speed type 6";
CM_ SG_ 509 NSPDVAL6 "Navigation speed value 6";
CM_ SG_ 509 NSPLSGN6 "Navigation supplemental sign 6";
CM_ SG_ 509 NSYNCID2 "Navigation synchronized ID 2";
CM_ BO_ 510 "Reserve";
CM_ SG_ 510 RDCLS0 "road class 0";
CM_ SG_ 510 LINKCLS0 "Link class 0";
CM_ SG_ 510 RDSTR0 "Road structure 0";
CM_ SG_ 510 BUILTUP0 "Built up area 0";
CM_ SG_ 510 FCRDCLS "Functional road class";
CM_ SG_ 510 RDCLS1 "road class 1";
CM_ SG_ 510 LINKCLS1 "Link class 1";
CM_ SG_ 510 RDSTR1 "Road structure 1";
CM_ SG_ 510 BUILTUP1 "Built up area 1";
CM_ SG_ 510 NENTLNK1 "No entry link 1";
CM_ SG_ 510 RGNINF "Region information";
CM_ SG_ 510 CNTINF "Country information";
CM_ SG_ 510 MAPAGE "Map age";
CM_ SG_ 510 RMNDIST "Remaining distance";
CM_ SG_ 510 NSYNCID3 "Navigation synchronized ID 3";
CM_ BO_ 511 "Reserve";
CM_ SG_ 511 RDCLS2 "road class 2";
CM_ SG_ 511 LINKCLS2 "Link class 2";
CM_ SG_ 511 RDSTR2 "Road structure 2";
CM_ SG_ 511 BUILTUP2 "Built up area 2";
CM_ SG_ 511 NENTLNK2 "No entry link 2";
CM_ SG_ 511 RDCLS3 "road class 3";
CM_ SG_ 511 LINKCLS3 "Link class 3";
CM_ SG_ 511 RDSTR3 "Road structure 3";
CM_ SG_ 511 BUILTUP3 "Built up area 3";
CM_ SG_ 511 NENTLNK3 "No entry link 3";
CM_ SG_ 511 RDCLS4 "road class 4";
CM_ SG_ 511 LINKCLS4 "Link class 4";
CM_ SG_ 511 RDSTR4 "Road structure 4";
CM_ SG_ 511 BUILTUP4 "Built up area 4";
CM_ SG_ 511 NENTLNK4 "No entry link 4";
CM_ SG_ 511 LANNUM "Lane number";
CM_ SG_ 511 MTCHCONF "Matching confidence";
CM_ SG_ 511 NSPDUNT "Navigation Speed Unit";
CM_ SG_ 511 ROUTSTS "Route guidance status";
CM_ SG_ 511 AVNFAIL "AVN Failure";
CM_ SG_ 511 NSYNCID4 "Navigation synchronized ID 4";
CM_ BO_ 934 "Reserve";
CM_ SG_ 934 LANENUM "Lane num";
CM_ SG_ 934 CVR1 "Curve R1";
CM_ SG_ 934 CVR2 "Curve R2";
CM_ SG_ 934 LVMAIN "Leave main";
CM_ SG_ 934 CVR3 "Curve R3";
CM_ SG_ 934 CVR4 "Curve R4";
CM_ BO_ 935 "Reserve";
CM_ SG_ 935 MLID "Merge/leave ID";
CM_ SG_ 935 MLDIR "Merge/leave direction";
CM_ SG_ 935 MLDT1 "Merge/leave distance1";
CM_ SG_ 935 MLCT "Merge/leave connect";
CM_ SG_ 935 MLTDIR "Merge/leave travelling direction";
CM_ SG_ 935 MLDT2 "Merge/leave distance2";
CM_ SG_ 935 MLLNUM "Merge/leave lane number";
CM_ SG_ 935 RAHRNUM "Read ahead route num";
CM_ SG_ 935 VRAHRDST "Valid read ahead route distance";
CM_ SG_ 935 MLPTN "Merge/leave shape pattern";
CM_ SG_ 935 LANEPOS "Lane position";
CM_ BO_ 846 "Reserve";
CM_ SG_ 846 CLE_RNG "Cloud Eco of remaining distance for control start";
CM_ SG_ 846 CLE_SOCT "Cloud Eco of SOC for control target";
CM_ BO_ 783 "Reserve";
CM_ SG_ 783 B2_FUNID "BDB2_FunctionID";
CM_ SG_ 783 B2_INST1 "BDB2_OpeInstruction1";
CM_ SG_ 783 B2_INST2 "BDB2_OpeInstruction2";
CM_ SG_ 783 B2_INST3 "BDB2_OpeInstruction3";
CM_ SG_ 783 B2_INST4 "BDB2_OpeInstruction4";
CM_ SG_ 783 B2_INST5 "BDB2_OpeInstruction5";
CM_ SG_ 783 B2_INST6 "BDB2_OpeInstruction6";
CM_ SG_ 783 B2_INST7 "BDB2_OpeInstruction7";
CM_ BO_ 936 "Reserve";
CM_ SG_ 936 DSTEXIT "Distance to exit in route guide information";
CM_ SG_ 936 TSSRNCFG "Road number change flag";
CM_ SG_ 936 DSTRNCP "Distance to road number change point";
CM_ SG_ 936 AVNCBFLG "FCM-MM image communication_AVN Camera Board presence or absence flag";
CM_ SG_ 936 OTHUNRCV "FCM-MM image communixcation_Unreceived image signal";
CM_ SG_ 936 TSSLNNUM "Lane num";
CM_ SG_ 936 TSSMLDIR "Merge/leave direction";
CM_ BO_ 976 "Reserve";
CM_ SG_ 976 PLGFUNID "PLG_FunctionID";
CM_ SG_ 976 PLGINST1 "PLG_OpeInstruction1";
CM_ SG_ 976 PLGINST2 "PLG_OpeInstruction2";
CM_ SG_ 976 PLGINST3 "PLG_OpeInstruction3";
CM_ SG_ 976 PLGINST4 "PLG_OpeInstruction4";
CM_ SG_ 976 PLGINST5 "PLG_OpeInstruction5";
CM_ SG_ 976 PLGINST6 "PLG_OpeInstruction6";
CM_ SG_ 976 PLGINST7 "PLG_OpeInstruction7";
CM_ BO_ 1021 "Reserve";
CM_ SG_ 1021 PT_FUNID "PT_FunctionID";
CM_ SG_ 1021 PT_INST1 "PT_OpeInstruction1";
CM_ SG_ 1021 PT_INST2 "PT_OpeInstruction2";
CM_ SG_ 1021 PT_INST3 "PT_OpeInstruction3";
CM_ SG_ 1021 PT_INST4 "PT_OpeInstruction4";
CM_ SG_ 1021 PT_INST5 "PT_OpeInstruction5";
CM_ SG_ 1021 PT_INST6 "PT_OpeInstruction6";
CM_ SG_ 1021 PT_INST7 "PT_OpeInstruction7";
CM_ BO_ 964 "Reserve";
CM_ SG_ 964 DS_FUNID "DS_FunctionID";
CM_ SG_ 964 DS_INST1 "DS_OpeInstruction1";
CM_ SG_ 964 DS_INST2 "DS_OpeInstruction2";
CM_ SG_ 964 DS_INST3 "DS_OpeInstruction3";
CM_ SG_ 964 DS_INST4 "DS_OpeInstruction4";
CM_ SG_ 964 DS_INST5 "DS_OpeInstruction5";
CM_ SG_ 964 DS_INST6 "DS_OpeInstruction6";
CM_ SG_ 964 DS_INST7 "DS_OpeInstruction7";
CM_ BO_ 797 "Reserve";
CM_ SG_ 797 RPSTJG "Route Planner Status Judgment";
CM_ SG_ 797 SQPBCH "Estimated squared value of battery power to the charging stations";
CM_ SG_ 797 CSDESSET "Charging station destination setting";
CM_ SG_ 797 BPRQSW "User battery preconditioning control request SW";
CM_ SG_ 797 ARRTMCT "Expected arrival time at charging station";
CM_ SG_ 797 BPNAVI "Battery Preconditioning with Navigation request";
CM_ SG_ 797 CONBATCH "Estimated power consumption to the charging stations";
CM_ BO_ 1009 "Reserve";
CM_ SG_ 1009 EDMMNUM "Event Num";
CM_ SG_ 1009 EDMMID1 "Event ID (1)";
CM_ SG_ 1009 EDMMTS1 "Event TimeStamp (1)";
CM_ SG_ 1009 EDMMID2 "Event ID (2)";
CM_ SG_ 1009 EDMMTS2 "Event TimeStamp (2)";
CM_ SG_ 1009 EDMMID3 "Event ID (3)";
CM_ SG_ 1009 EDMMTS3 "Event TimeStamp (3)";
CM_ SG_ 1009 EDMMID4 "Event ID (4)";
CM_ SG_ 1009 EDMMTS4 "Event TimeStamp (4)";
CM_ SG_ 1009 EDMMID5 "Event ID (5)";
CM_ SG_ 1009 EDMMTS5 "Event TimeStamp (5)";
CM_ SG_ 1009 EDMMID6 "Event ID (6)";
CM_ SG_ 1009 EDMMTS6 "Event TimeStamp (6)";
CM_ BO_ 962 "Reserve";
CM_ SG_ 962 RPSNO1_A "Proposed Site Number1 from AVN";
CM_ SG_ 962 RPSNO2_A "Proposed Site Number2 from AVN";
CM_ SG_ 962 RPEPS1 "Estimated Power Consumption for Proposed Site1";
CM_ SG_ 962 RPEPS2 "Estimated Power Consumption for Proposed Site2";
CM_ SG_ 962 RPEPS3 "Estimated Power Consumption for Proposed Site3";
CM_ SG_ 962 RPEPS4 "Estimated Power Consumption for Proposed Site4";
CM_ SG_ 962 RPCRO1 "Charger Rated Output at Proposed Site1";
CM_ SG_ 962 RPCRO2 "Charger Rated Output at Proposed Site2";
CM_ SG_ 962 RPCRO3 "Charger Rated Output at Proposed Site3";
CM_ SG_ 962 RPCRO4 "Charger Rated Output at Proposed Site4";
CM_ SG_ 962 RPCTIM1 "Charging Time for Proposed Site1";
CM_ SG_ 962 RPCTIM2 "Charging Time for Proposed Site2";
CM_ SG_ 962 RPCTIM3 "Charging Time for Proposed Site3";
CM_ SG_ 962 RPCTIM4 "Charging Time for Proposed Site4";
CM_ BO_ 1038 "Reserve";
CM_ SG_ 1038 TTLFRAM "Total number of frames";
CM_ SG_ 1038 FRAMID0 "Frame ID";
CM_ SG_ 1038 FORMID "Formula ID";
CM_ SG_ 1038 X_DATAID "Variable 1_collection signal ID";
CM_ SG_ 1038 X_TYPE "Variable 1_ type";
CM_ SG_ 1038 PADDINGX "Variable 1_margine slot";
CM_ SG_ 1038 X_DELAY "Variable 1_delay time";
CM_ SG_ 1038 Y_DATAID "Variable 2_collection signal ID";
CM_ SG_ 1038 Y_TYPE "Variable 2_ type";
CM_ SG_ 1038 PADDINGY "Variable 2_margine slot";
CM_ SG_ 1038 Y_DELAY "Variable 2_delay time";
CM_ SG_ 1038 PREPROC "Primary conversion";
CM_ SG_ 1038 COMPOPE "Comparison operator";
CM_ SG_ 1038 Y_CONST "Variable 2_constant value";
CM_ SG_ 1038 COMPVAL "Comparison value";
CM_ SG_ 1038 FORMID_A "ID of formula A";
CM_ SG_ 1038 FORMID_B "ID of formula B";
CM_ SG_ 1038 LOGIOPE "Logical operator";
CM_ SG_ 1038 MAXTRG "Maximum number per trip";
CM_ SG_ 1038 FORMID_C "ID of output formula C";
CM_ SG_ 1038 PADDING1 "Margine slot 1";
CM_ SG_ 1038 MDCREQID "MDC Data collection request ID";
CM_ SG_ 1038 FORMID_D "ID of Judgment formula D";
CM_ SG_ 1038 GRDDIST "Frequent event guard (Distance)";
CM_ SG_ 1038 GRDTIME "Frequent event guard (Time)";
CM_ BO_ 1306 "Reserve";
CM_ SG_ 1306 TCIN_ID "MM Trailer Command Trailer ID";
CM_ SG_ 1306 TCIN_TTP "MM User  input  Trailer Type";
CM_ SG_ 1306 TCIN_AC "MM Trailer Command Action";
CM_ SG_ 1306 TCIN_HTP "MM User Input Hitch Type";
CM_ SG_ 1306 TCIN_LM "MM User Input Length Auto or Manual Mode";
CM_ SG_ 1306 TCIN_NAX "MM User Input Number of Axles";
CM_ SG_ 1306 TCIN_BTP "MM User Input Trailer Brake Type";
CM_ SG_ 1306 TCIN_HLM "MM User Input Hitch Length Auto or Manual Mode";
CM_ SG_ 1306 TCIN_L "MM User Input Trailer Length";
CM_ SG_ 1306 TCIN_HL "MM User Input Hitch Length";
CM_ SG_ 1306 TCIN_WB "MM User Input Beam Length";
CM_ SG_ 1306 TCIN_W "MM User Input Trailer Width";
CM_ SG_ 1306 TCIN_WBM "MM User Input Beam Length Auto or Manual Mode";
CM_ SG_ 1306 TCIN_WM "MM User Input Trailer Width Auto or Manual Mode";
CM_ SG_ 1306 TCIN_TWM "MM User Input Trailer Weight Auto or Manual Mode";
CM_ SG_ 1306 TCIN_TW "MM User Input Trailer Weight";
CM_ SG_ 1306 TCIN_MI "MM User Input Mileage";
CM_ BO_ 1307 "Reserve";
CM_ SG_ 1307 TCIN_TN "MM User selected Trailer Name";
CM_ BO_ 1010 "Reserve";
CM_ SG_ 1010 BEV_RNG "Remaining distance for control start(for BEV)";
CM_ SG_ 1010 BEV_TIME "Target heating time(for BEV)";
CM_ BO_ 723 "Reserve";
CM_ SG_ 723 GDPC_SW1 "GDP Customize info operation signal (mode1) ";
CM_ SG_ 723 GDPC_SW2 "GDP Customize info operation signal (mode2) ";
CM_ SG_ 723 GDPC_SW3 "GDP Customize info operation signal (mode3) ";
CM_ SG_ 723 GDPC_SW4 "GDP Customize info operation signal (mode4) ";
CM_ SG_ 723 GDPC_SW5 "GDP Customize info operation signal (mode5) ";
CM_ SG_ 723 GDPC_SW6 "GDP Customize info operation signal (mode6) ";
CM_ SG_ 723 GDPC_SW7 "GDP Customize info operation signal (mode7) ";
CM_ SG_ 723 GDPC_SW8 "GDP Customize info operation signal (mode8) ";
CM_ SG_ 723 GDPAVN_D "Status of GDP Customize selection display";
BA_DEF_  "DBName" STRING ;
BA_DEF_  "Manufacturer" STRING ;
BA_DEF_  "BusType" STRING ;
BA_DEF_  "Baudrate" INT 1 1000000;
BA_DEF_  "VersionYear" INT 0 99;
BA_DEF_  "VersionMonth" INT 1 12;
BA_DEF_  "VersionDay" INT 1 31;
BA_DEF_  "VersionNumber" INT 0 65535;
BA_DEF_ BO_  "GenMsgILSupport" ENUM  "No","Yes";
BA_DEF_ BO_  "GenMsgSendType" ENUM  "Cyclic","NotUsed","NotUsed","NotUsed","NotUsed","NotUsed","NotUsed","NotUsed","NoMsgSendType";
BA_DEF_ SG_  "GenSigSendType" ENUM  "Cyclic","OnWrite","OnWriteWithRepetition","OnChange","OnChangeWithRepetition","NotUsed","NotUsed","NoSigSendType";
BA_DEF_ BO_  "GenMsgCycleTime" INT 0 65535;
BA_DEF_ SG_  "GenSigStartValue" FLOAT 0 100000000000;
BA_DEF_ BO_  "GenMsgStartDelayTime" INT 0 100000;
BA_DEF_ BO_  "VFrameFormat" ENUM  "StandardCAN","ExtendedCAN","reserved","reserved","reserved","reserved","reserved","reserved","reserved","reserved","reserved","reserved","reserved","reserved","StandardCAN_FD","ExtendedCAN_FD";
BA_DEF_ BO_  "CANFD_BRS" ENUM  "0","1";
BA_DEF_  "NmType" STRING ;
BA_DEF_ BU_  "NmStationAddress" HEX 0 127;
BA_DEF_ BU_  "NmAsrCanMsgReducedTime" INT 0 65535;
BA_DEF_  "NmAsrCanMsgCycleTime" INT 1 65535;
BA_DEF_  "NmAsrBaseAddress" HEX 0 536870911;
BA_DEF_  "NmAsrMessageCount" INT 0 255;
BA_DEF_  "NmAsrRepeatMessageTime" INT 1 65535;
BA_DEF_  "NmAsrWaitBusSleepTime" INT 1 65535;
BA_DEF_  "NmAsrTimeoutTime" INT 1 65535;
BA_DEF_ BO_  "DiagConnection" HEX 0 65535;
BA_DEF_DEF_  "DBName" "";
BA_DEF_DEF_  "Manufacturer" "Vector";
BA_DEF_DEF_  "BusType" "CAN FD";
BA_DEF_DEF_  "Baudrate" 500000;
BA_DEF_DEF_  "VersionYear" 20;
BA_DEF_DEF_  "VersionMonth" 1;
BA_DEF_DEF_  "VersionDay" 1;
BA_DEF_DEF_  "VersionNumber" 1;
BA_DEF_DEF_  "GenMsgILSupport" "No";
BA_DEF_DEF_  "GenMsgSendType" "NoMsgSendType";
BA_DEF_DEF_  "GenSigSendType" "NoSigSendType";
BA_DEF_DEF_  "GenMsgCycleTime" 0;
BA_DEF_DEF_  "GenSigStartValue" 0;
BA_DEF_DEF_  "GenMsgStartDelayTime" 0;
BA_DEF_DEF_  "VFrameFormat" "";
BA_DEF_DEF_  "CANFD_BRS" "1";
BA_DEF_DEF_  "NmType" "NmAsr";
BA_DEF_DEF_  "NmStationAddress" 0;
BA_DEF_DEF_  "NmAsrCanMsgReducedTime" 500;
BA_DEF_DEF_  "NmAsrCanMsgCycleTime" 1000;
BA_DEF_DEF_  "NmAsrBaseAddress" 1088;
BA_DEF_DEF_  "NmAsrMessageCount" 64;
BA_DEF_DEF_  "NmAsrRepeatMessageTime" 2500;
BA_DEF_DEF_  "NmAsrWaitBusSleepTime" 60000;
BA_DEF_DEF_  "NmAsrTimeoutTime" 3000;
BA_DEF_DEF_  "DiagConnection" 3000.00004970533;
BA_ "VersionYear" 2024;
BA_ "VersionMonth" 7;
BA_ "VersionDay" 5;
BA_ "DBName" "CDC_GLOBAL_CAN_5M";
BA_ "GenMsgCycleTime" BO_ 472 300;
BA_ "GenMsgSendType" BO_ 472 0;
BA_ "GenMsgILSupport" BO_ 472 1;
BA_ "VFrameFormat" BO_ 472 14;
BA_ "GenMsgCycleTime" BO_ 470 300;
BA_ "GenMsgSendType" BO_ 470 0;
BA_ "GenMsgILSupport" BO_ 470 1;
BA_ "VFrameFormat" BO_ 470 14;
BA_ "GenMsgCycleTime" BO_ 1428 5000;
BA_ "GenMsgSendType" BO_ 1428 0;
BA_ "GenMsgILSupport" BO_ 1428 1;
BA_ "VFrameFormat" BO_ 1428 14;
BA_ "GenMsgCycleTime" BO_ 497 500;
BA_ "GenMsgSendType" BO_ 497 0;
BA_ "GenMsgILSupport" BO_ 497 1;
BA_ "VFrameFormat" BO_ 497 14;
BA_ "GenMsgCycleTime" BO_ 323 100;
BA_ "GenMsgSendType" BO_ 323 0;
BA_ "GenMsgILSupport" BO_ 323 1;
BA_ "VFrameFormat" BO_ 323 14;
BA_ "GenMsgCycleTime" BO_ 515 1000;
BA_ "GenMsgSendType" BO_ 515 0;
BA_ "GenMsgILSupport" BO_ 515 1;
BA_ "VFrameFormat" BO_ 515 14;
BA_ "GenMsgCycleTime" BO_ 520 1000;
BA_ "GenMsgSendType" BO_ 520 0;
BA_ "GenMsgILSupport" BO_ 520 1;
BA_ "VFrameFormat" BO_ 520 14;
BA_ "GenMsgCycleTime" BO_ 521 1000;
BA_ "GenMsgSendType" BO_ 521 0;
BA_ "GenMsgILSupport" BO_ 521 1;
BA_ "VFrameFormat" BO_ 521 14;
BA_ "GenMsgCycleTime" BO_ 384 100;
BA_ "GenMsgSendType" BO_ 384 0;
BA_ "GenMsgILSupport" BO_ 384 1;
BA_ "VFrameFormat" BO_ 384 14;
BA_ "GenMsgCycleTime" BO_ 522 1000;
BA_ "GenMsgSendType" BO_ 522 0;
BA_ "GenMsgILSupport" BO_ 522 1;
BA_ "VFrameFormat" BO_ 522 14;
BA_ "GenMsgILSupport" BO_ 1555 1;
BA_ "VFrameFormat" BO_ 1555 14;
BA_ "GenMsgILSupport" BO_ 455 1;
BA_ "VFrameFormat" BO_ 455 14;
BA_ "GenMsgCycleTime" BO_ 324 100;
BA_ "GenMsgSendType" BO_ 324 0;
BA_ "GenMsgILSupport" BO_ 324 1;
BA_ "VFrameFormat" BO_ 324 14;
BA_ "GenMsgCycleTime" BO_ 583 1000;
BA_ "GenMsgSendType" BO_ 583 0;
BA_ "GenMsgILSupport" BO_ 583 1;
BA_ "VFrameFormat" BO_ 583 14;
BA_ "GenMsgCycleTime" BO_ 501 500;
BA_ "GenMsgSendType" BO_ 501 0;
BA_ "GenMsgILSupport" BO_ 501 1;
BA_ "VFrameFormat" BO_ 501 14;
BA_ "GenMsgCycleTime" BO_ 496 500;
BA_ "GenMsgSendType" BO_ 496 0;
BA_ "GenMsgILSupport" BO_ 496 1;
BA_ "VFrameFormat" BO_ 496 14;
BA_ "GenMsgCycleTime" BO_ 558 1000;
BA_ "GenMsgSendType" BO_ 558 0;
BA_ "GenMsgILSupport" BO_ 558 1;
BA_ "VFrameFormat" BO_ 558 14;
BA_ "GenMsgILSupport" BO_ 353 1;
BA_ "VFrameFormat" BO_ 353 14;
BA_ "GenMsgCycleTime" BO_ 354 100;
BA_ "GenMsgSendType" BO_ 354 0;
BA_ "GenMsgILSupport" BO_ 354 1;
BA_ "VFrameFormat" BO_ 354 14;
BA_ "GenMsgCycleTime" BO_ 355 100;
BA_ "GenMsgSendType" BO_ 355 0;
BA_ "GenMsgILSupport" BO_ 355 1;
BA_ "VFrameFormat" BO_ 355 14;
BA_ "GenMsgCycleTime" BO_ 358 100;
BA_ "GenMsgSendType" BO_ 358 0;
BA_ "GenMsgILSupport" BO_ 358 1;
BA_ "VFrameFormat" BO_ 358 14;
BA_ "GenMsgCycleTime" BO_ 359 100;
BA_ "GenMsgSendType" BO_ 359 0;
BA_ "GenMsgILSupport" BO_ 359 1;
BA_ "VFrameFormat" BO_ 359 14;
BA_ "GenMsgCycleTime" BO_ 360 100;
BA_ "GenMsgSendType" BO_ 360 0;
BA_ "GenMsgILSupport" BO_ 360 1;
BA_ "VFrameFormat" BO_ 360 14;
BA_ "GenMsgCycleTime" BO_ 361 100;
BA_ "GenMsgSendType" BO_ 361 0;
BA_ "GenMsgILSupport" BO_ 361 1;
BA_ "VFrameFormat" BO_ 361 14;
BA_ "GenMsgCycleTime" BO_ 362 100;
BA_ "GenMsgSendType" BO_ 362 0;
BA_ "GenMsgILSupport" BO_ 362 1;
BA_ "VFrameFormat" BO_ 362 14;
BA_ "GenMsgCycleTime" BO_ 363 100;
BA_ "GenMsgSendType" BO_ 363 0;
BA_ "GenMsgILSupport" BO_ 363 1;
BA_ "VFrameFormat" BO_ 363 14;
BA_ "GenMsgCycleTime" BO_ 364 100;
BA_ "GenMsgSendType" BO_ 364 0;
BA_ "GenMsgILSupport" BO_ 364 1;
BA_ "VFrameFormat" BO_ 364 14;
BA_ "GenMsgCycleTime" BO_ 365 100;
BA_ "GenMsgSendType" BO_ 365 0;
BA_ "GenMsgILSupport" BO_ 365 1;
BA_ "VFrameFormat" BO_ 365 14;
BA_ "GenMsgCycleTime" BO_ 114 12;
BA_ "GenMsgSendType" BO_ 114 0;
BA_ "GenMsgILSupport" BO_ 114 1;
BA_ "VFrameFormat" BO_ 114 14;
BA_ "GenMsgCycleTime" BO_ 902 3000;
BA_ "GenMsgSendType" BO_ 902 0;
BA_ "GenMsgILSupport" BO_ 902 1;
BA_ "GenMsgStartDelayTime" BO_ 902 4;
BA_ "VFrameFormat" BO_ 902 14;
BA_ "GenMsgCycleTime" BO_ 905 1000;
BA_ "GenMsgSendType" BO_ 905 0;
BA_ "GenMsgILSupport" BO_ 905 1;
BA_ "GenMsgStartDelayTime" BO_ 905 8;
BA_ "VFrameFormat" BO_ 905 14;
BA_ "GenMsgCycleTime" BO_ 383 100;
BA_ "GenMsgSendType" BO_ 383 0;
BA_ "GenMsgILSupport" BO_ 383 1;
BA_ "GenMsgStartDelayTime" BO_ 383 12;
BA_ "VFrameFormat" BO_ 383 14;
BA_ "GenMsgCycleTime" BO_ 1070 1000;
BA_ "GenMsgSendType" BO_ 1070 0;
BA_ "GenMsgILSupport" BO_ 1070 1;
BA_ "GenMsgStartDelayTime" BO_ 1070 16;
BA_ "VFrameFormat" BO_ 1070 14;
BA_ "GenMsgCycleTime" BO_ 294 100;
BA_ "GenMsgSendType" BO_ 294 0;
BA_ "GenMsgILSupport" BO_ 294 1;
BA_ "GenMsgStartDelayTime" BO_ 294 20;
BA_ "VFrameFormat" BO_ 294 14;
BA_ "GenMsgCycleTime" BO_ 508 500;
BA_ "GenMsgSendType" BO_ 508 0;
BA_ "GenMsgILSupport" BO_ 508 1;
BA_ "GenMsgStartDelayTime" BO_ 508 24;
BA_ "VFrameFormat" BO_ 508 14;
BA_ "GenMsgCycleTime" BO_ 509 500;
BA_ "GenMsgSendType" BO_ 509 0;
BA_ "GenMsgILSupport" BO_ 509 1;
BA_ "GenMsgStartDelayTime" BO_ 509 28;
BA_ "VFrameFormat" BO_ 509 14;
BA_ "GenMsgCycleTime" BO_ 510 500;
BA_ "GenMsgSendType" BO_ 510 0;
BA_ "GenMsgILSupport" BO_ 510 1;
BA_ "GenMsgStartDelayTime" BO_ 510 32;
BA_ "VFrameFormat" BO_ 510 14;
BA_ "GenMsgCycleTime" BO_ 511 500;
BA_ "GenMsgSendType" BO_ 511 0;
BA_ "GenMsgILSupport" BO_ 511 1;
BA_ "GenMsgStartDelayTime" BO_ 511 36;
BA_ "VFrameFormat" BO_ 511 14;
BA_ "GenMsgCycleTime" BO_ 934 3000;
BA_ "GenMsgSendType" BO_ 934 0;
BA_ "GenMsgILSupport" BO_ 934 1;
BA_ "GenMsgStartDelayTime" BO_ 934 40;
BA_ "VFrameFormat" BO_ 934 14;
BA_ "GenMsgCycleTime" BO_ 935 3000;
BA_ "GenMsgSendType" BO_ 935 0;
BA_ "GenMsgILSupport" BO_ 935 1;
BA_ "GenMsgStartDelayTime" BO_ 935 44;
BA_ "VFrameFormat" BO_ 935 14;
BA_ "GenMsgCycleTime" BO_ 846 20000;
BA_ "GenMsgSendType" BO_ 846 0;
BA_ "GenMsgILSupport" BO_ 846 1;
BA_ "GenMsgStartDelayTime" BO_ 846 48;
BA_ "VFrameFormat" BO_ 846 14;
BA_ "GenMsgCycleTime" BO_ 783 1000;
BA_ "GenMsgSendType" BO_ 783 0;
BA_ "GenMsgILSupport" BO_ 783 1;
BA_ "GenMsgStartDelayTime" BO_ 783 52;
BA_ "VFrameFormat" BO_ 783 14;
BA_ "GenMsgCycleTime" BO_ 936 3000;
BA_ "GenMsgSendType" BO_ 936 0;
BA_ "GenMsgILSupport" BO_ 936 1;
BA_ "GenMsgStartDelayTime" BO_ 936 56;
BA_ "VFrameFormat" BO_ 936 14;
BA_ "GenMsgCycleTime" BO_ 976 1000;
BA_ "GenMsgSendType" BO_ 976 0;
BA_ "GenMsgILSupport" BO_ 976 1;
BA_ "GenMsgStartDelayTime" BO_ 976 60;
BA_ "VFrameFormat" BO_ 976 14;
BA_ "GenMsgCycleTime" BO_ 1021 1000;
BA_ "GenMsgSendType" BO_ 1021 0;
BA_ "GenMsgILSupport" BO_ 1021 1;
BA_ "GenMsgStartDelayTime" BO_ 1021 64;
BA_ "VFrameFormat" BO_ 1021 14;
BA_ "GenMsgCycleTime" BO_ 964 1000;
BA_ "GenMsgSendType" BO_ 964 0;
BA_ "GenMsgILSupport" BO_ 964 1;
BA_ "GenMsgStartDelayTime" BO_ 964 68;
BA_ "VFrameFormat" BO_ 964 14;
BA_ "GenMsgCycleTime" BO_ 797 1000;
BA_ "GenMsgSendType" BO_ 797 0;
BA_ "GenMsgILSupport" BO_ 797 1;
BA_ "GenMsgStartDelayTime" BO_ 797 72;
BA_ "VFrameFormat" BO_ 797 14;
BA_ "GenMsgILSupport" BO_ 1009 1;
BA_ "GenMsgStartDelayTime" BO_ 1009 76;
BA_ "VFrameFormat" BO_ 1009 14;
BA_ "GenMsgCycleTime" BO_ 962 1000;
BA_ "GenMsgSendType" BO_ 962 0;
BA_ "GenMsgILSupport" BO_ 962 1;
BA_ "GenMsgStartDelayTime" BO_ 962 80;
BA_ "VFrameFormat" BO_ 962 14;
BA_ "GenMsgCycleTime" BO_ 1038 1000;
BA_ "GenMsgSendType" BO_ 1038 0;
BA_ "GenMsgILSupport" BO_ 1038 1;
BA_ "GenMsgStartDelayTime" BO_ 1038 84;
BA_ "VFrameFormat" BO_ 1038 14;
BA_ "GenMsgCycleTime" BO_ 1306 1000;
BA_ "GenMsgSendType" BO_ 1306 0;
BA_ "GenMsgILSupport" BO_ 1306 1;
BA_ "GenMsgStartDelayTime" BO_ 1306 88;
BA_ "VFrameFormat" BO_ 1306 14;
BA_ "GenMsgCycleTime" BO_ 1307 1000;
BA_ "GenMsgSendType" BO_ 1307 0;
BA_ "GenMsgILSupport" BO_ 1307 1;
BA_ "GenMsgStartDelayTime" BO_ 1307 92;
BA_ "VFrameFormat" BO_ 1307 14;
BA_ "GenMsgCycleTime" BO_ 1010 20000;
BA_ "GenMsgSendType" BO_ 1010 0;
BA_ "GenMsgILSupport" BO_ 1010 1;
BA_ "GenMsgStartDelayTime" BO_ 1010 96;
BA_ "VFrameFormat" BO_ 1010 14;
BA_ "GenMsgCycleTime" BO_ 723 1000;
BA_ "GenMsgSendType" BO_ 723 0;
BA_ "GenMsgILSupport" BO_ 723 1;
BA_ "GenMsgStartDelayTime" BO_ 723 100;
BA_ "VFrameFormat" BO_ 723 14;
BA_ "GenSigSendType" SG_ 472 SCSVNR 3;
BA_ "GenSigSendType" SG_ 1428 USMDC1 3;
BA_ "GenSigSendType" SG_ 1428 USMDC2 3;
BA_ "GenSigSendType" SG_ 1428 USMDC3 3;
BA_ "GenSigSendType" SG_ 1428 USMDC5 3;
BA_ "GenSigSendType" SG_ 1428 USMDC6 3;
BA_ "GenSigSendType" SG_ 1428 USMDRQAC 3;
BA_ "GenSigSendType" SG_ 1428 USMDC7 3;
BA_ "GenSigSendType" SG_ 1428 USMNAV 3;
BA_ "GenSigSendType" SG_ 497 HNPAVABL 3;
BA_ "GenSigSendType" SG_ 497 UNPAVABL 3;
BA_ "GenSigSendType" SG_ 497 FCWAVABL 3;
BA_ "GenSigSendType" SG_ 497 ELKAVABL 3;
BA_ "GenSigSendType" SG_ 497 CDWAVABL 3;
BA_ "GenSigSendType" SG_ 497 SLFAVABL 3;
BA_ "GenSigSendType" SG_ 497 TLAAVABL 3;
BA_ "GenSigSendType" SG_ 497 ESSAVABL 3;
BA_ "GenSigSendType" SG_ 497 CSWAVABL 3;
BA_ "GenSigSendType" SG_ 497 AESAVABL 3;
BA_ "GenSigSendType" SG_ 497 CPAVABL 3;
BA_ "GenSigSendType" SG_ 497 LDKAVABL 3;
BA_ "GenSigSendType" SG_ 497 MNPAVABL 3;
BA_ "GenSigSendType" SG_ 323 LPAPFAIL 3;
BA_ "GenSigSendType" SG_ 323 LPNPFAIL 3;
BA_ "GenSigSendType" SG_ 323 LPNPSYS 3;
BA_ "GenSigSendType" SG_ 323 LPNPONST 3;
BA_ "GenSigSendType" SG_ 323 PNPFAIL 3;
BA_ "GenSigSendType" SG_ 323 PNPSYS 3;
BA_ "GenSigSendType" SG_ 323 PNPONST 3;
BA_ "GenSigSendType" SG_ 323 APPONST 3;
BA_ "GenSigSendType" SG_ 323 AP_LAMP 3;
BA_ "GenSigSendType" SG_ 323 LPNPLAMP 3;
BA_ "GenSigSendType" SG_ 323 LPNPSTS 3;
BA_ "GenSigSendType" SG_ 323 PNPSTS 3;
BA_ "GenSigSendType" SG_ 515 GDNEXIST 3;
BA_ "GenSigSendType" SG_ 520 ADBZRQ 3;
BA_ "GenSigSendType" SG_ 520 ADPRDTML 3;
BA_ "GenSigSendType" SG_ 520 ADMMMUTE 3;
BA_ "GenSigSendType" SG_ 520 ADADDRST 3;
BA_ "GenSigSendType" SG_ 520 ADOTASST 3;
BA_ "GenSigSendType" SG_ 520 ADSTMUST 3;
BA_ "GenSigSendType" SG_ 520 ADAUNFST 3;
BA_ "GenSigSendType" SG_ 520 ADNTLVST 3;
BA_ "GenSigSendType" SG_ 520 ADDSLVST 3;
BA_ "GenSigSendType" SG_ 520 ADVOCTST 3;
BA_ "GenSigSendType" SG_ 520 ADSLDSST 3;
BA_ "GenSigSendType" SG_ 520 ADDMCRST 3;
BA_ "GenSigSendType" SG_ 520 ADSEGDST 3;
BA_ "GenSigSendType" SG_ 520 ADSVSSST 3;
BA_ "GenSigSendType" SG_ 520 ADCVVSST 3;
BA_ "GenSigSendType" SG_ 520 ADDOTTT 3;
BA_ "GenSigSendType" SG_ 520 ADDOTRQ 3;
BA_ "GenSigSendType" SG_ 520 ADHONRQ 3;
BA_ "GenSigSendType" SG_ 520 ADADMTT 3;
BA_ "GenSigSendType" SG_ 520 ADHOFDSP 3;
BA_ "GenSigSendType" SG_ 520 ADTRJDSP 3;
BA_ "GenSigSendType" SG_ 520 ADLLIDSP 3;
BA_ "GenSigSendType" SG_ 520 ADRLIDSP 3;
BA_ "GenSigSendType" SG_ 520 MNPCUSST 3;
BA_ "GenSigSendType" SG_ 520 RCD_DE_C 3;
BA_ "GenSigSendType" SG_ 520 RCDDE_ST 3;
BA_ "GenSigSendType" SG_ 520 AIPWFR1 3;
BA_ "GenSigSendType" SG_ 520 AIPWFR2 3;
BA_ "GenSigSendType" SG_ 520 AIPREQ 3;
BA_ "GenSigSendType" SG_ 520 AIPRLAR 3;
BA_ "GenSigSendType" SG_ 520 AIPPROEX 3;
BA_ "GenSigSendType" SG_ 520 AIPPRORE 3;
BA_ "GenSigSendType" SG_ 521 FCWCUSST 3;
BA_ "GenSigSendType" SG_ 521 CDWCUSST 3;
BA_ "GenSigSendType" SG_ 521 SLFCUSST 3;
BA_ "GenSigSendType" SG_ 521 TLACUSST 3;
BA_ "GenSigSendType" SG_ 521 BSDCUSST 3;
BA_ "GenSigSendType" SG_ 521 ESSCUSST 3;
BA_ "GenSigSendType" SG_ 521 CSWCUSST 3;
BA_ "GenSigSendType" SG_ 521 AESCUSST 3;
BA_ "GenSigSendType" SG_ 521 HNPCUSST 3;
BA_ "GenSigSendType" SG_ 521 UNPCUSST 3;
BA_ "GenSigSendType" SG_ 521 LDKCUSST 3;
BA_ "GenSigSendType" SG_ 521 ELKCUSST 3;
BA_ "GenSigSendType" SG_ 521 CPCUSST 3;
BA_ "GenSigSendType" SG_ 521 HNPCSST 3;
BA_ "GenSigSendType" SG_ 521 UNPCSST 3;
BA_ "GenSigSendType" SG_ 521 NPLCCSST 3;
BA_ "GenSigSendType" SG_ 521 NPCS1ST 3;
BA_ "GenSigSendType" SG_ 521 NPCS2ST 3;
BA_ "GenSigSendType" SG_ 521 NPCS3ST 3;
BA_ "GenSigSendType" SG_ 521 NPCS4ST 3;
BA_ "GenSigSendType" SG_ 521 NPCS5ST 3;
BA_ "GenSigSendType" SG_ 521 NPCS6ST 3;
BA_ "GenSigSendType" SG_ 521 NPCS7ST 3;
BA_ "GenSigSendType" SG_ 521 NPCS8ST 3;
BA_ "GenSigSendType" SG_ 521 NPCS9ST 3;
BA_ "GenSigSendType" SG_ 521 NPCS10ST 3;
BA_ "GenSigSendType" SG_ 521 NPCS11ST 3;
BA_ "GenSigSendType" SG_ 521 NPCS12ST 3;
BA_ "GenSigSendType" SG_ 521 NPCS13ST 3;
BA_ "GenSigSendType" SG_ 521 NPCS14ST 3;
BA_ "GenSigSendType" SG_ 521 NPCS15ST 3;
BA_ "GenSigSendType" SG_ 521 NPCS16ST 3;
BA_ "GenSigSendType" SG_ 521 NPCS17ST 3;
BA_ "GenSigSendType" SG_ 521 NPCS18ST 3;
BA_ "GenSigSendType" SG_ 521 NPCS19ST 3;
BA_ "GenSigSendType" SG_ 521 NPCS20ST 3;
BA_ "GenSigSendType" SG_ 521 GDNCTST 3;
BA_ "GenSigSendType" SG_ 521 GDNWNST 3;
BA_ "GenSigSendType" SG_ 521 GDNBKST 3;
BA_ "GenSigSendType" SG_ 521 GDNSTST 3;
BA_ "GenSigSendType" SG_ 521 GDNSNST 3;
BA_ "GenSigSendType" SG_ 521 FCWCTST 3;
BA_ "GenSigSendType" SG_ 521 FCWSEST 3;
BA_ "GenSigSendType" SG_ 521 CDWCTST 3;
BA_ "GenSigSendType" SG_ 521 TLACTST 3;
BA_ "GenSigSendType" SG_ 521 SLFCTST 3;
BA_ "GenSigSendType" SG_ 521 CSWCTST 3;
BA_ "GenSigSendType" SG_ 521 AESCTST 3;
BA_ "GenSigSendType" SG_ 521 ACCCTST 3;
BA_ "GenSigSendType" SG_ 521 CPCTST 3;
BA_ "GenSigSendType" SG_ 521 LDKCTST 3;
BA_ "GenSigSendType" SG_ 521 LDKSNST 3;
BA_ "GenSigSendType" SG_ 521 ELKCTST 3;
BA_ "GenSigSendType" SG_ 521 ELKMDST 3;
BA_ "GenSigSendType" SG_ 521 BSDCTST 3;
BA_ "GenSigSendType" SG_ 521 NPSSWEX 3;
BA_ "GenSigSendType" SG_ 521 NPSSWST 3;
BA_ "GenSigSendType" SG_ 521 RCPMCTST 3;
BA_ "GenSigSendType" SG_ 521 NPDSSWEX 3;
BA_ "GenSigSendType" SG_ 521 NPDSSWST 3;
BA_ "GenSigSendType" SG_ 521 ESSCTST 3;
BA_ "GenSigSendType" SG_ 521 OVSPCVAL 3;
BA_ "GenSigSendType" SG_ 521 CRNGCUST 3;
BA_ "GenSigSendType" SG_ 521 CSRNGF 3;
BA_ "GenSigSendType" SG_ 521 CSRNGR 3;
BA_ "GenSigSendType" SG_ 521 WDISPCST 3;
BA_ "GenSigSendType" SG_ 521 WDISPSTT 3;
BA_ "GenSigSendType" SG_ 521 MOACUST 3;
BA_ "GenSigSendType" SG_ 521 MOASTAT 3;
BA_ "GenSigSendType" SG_ 521 MOAAOST 3;
BA_ "GenSigSendType" SG_ 521 MNPFNEX 3;
BA_ "GenSigSendType" SG_ 521 MNPSSWEX 3;
BA_ "GenSigSendType" SG_ 521 MNPSSWST 3;
BA_ "GenSigSendType" SG_ 384 CSRRDRW 3;
BA_ "GenSigStartValue" SG_ 384 WCOL_FLS 3;
BA_ "GenSigStartValue" SG_ 384 WCOL_FL 3;
BA_ "GenSigStartValue" SG_ 384 WCOL_FLC 3;
BA_ "GenSigStartValue" SG_ 384 WCOL_FRS 3;
BA_ "GenSigStartValue" SG_ 384 WCOL_FR 3;
BA_ "GenSigStartValue" SG_ 384 WCOL_FRC 3;
BA_ "GenSigStartValue" SG_ 384 WCOL_RLS 3;
BA_ "GenSigStartValue" SG_ 384 WCOL_RL 3;
BA_ "GenSigStartValue" SG_ 384 WCOL_RLC 3;
BA_ "GenSigStartValue" SG_ 384 WCOL_RRS 3;
BA_ "GenSigStartValue" SG_ 384 WCOL_RR 3;
BA_ "GenSigStartValue" SG_ 384 WCOL_RRC 3;
BA_ "GenSigStartValue" SG_ 384 WCOL_RS1 3;
BA_ "GenSigStartValue" SG_ 384 WCOL_RS2 3;
BA_ "GenSigStartValue" SG_ 384 WCOL_RS3 3;
BA_ "GenSigStartValue" SG_ 384 WCOL_RS4 3;
BA_ "GenSigStartValue" SG_ 384 WCOL_RS5 3;
BA_ "GenSigStartValue" SG_ 384 WCOL_RS6 3;
BA_ "GenSigStartValue" SG_ 384 WCOL_RS7 3;
BA_ "GenSigStartValue" SG_ 384 WCOL_RS8 3;
BA_ "GenSigStartValue" SG_ 384 WCOL_LS1 3;
BA_ "GenSigStartValue" SG_ 384 WCOL_LS2 3;
BA_ "GenSigStartValue" SG_ 384 WCOL_LS3 3;
BA_ "GenSigStartValue" SG_ 384 WCOL_LS4 3;
BA_ "GenSigStartValue" SG_ 384 WCOL_LS5 3;
BA_ "GenSigStartValue" SG_ 384 WCOL_LS6 3;
BA_ "GenSigStartValue" SG_ 384 WCOL_LS7 3;
BA_ "GenSigStartValue" SG_ 384 WCOL_LS8 3;
BA_ "GenSigStartValue" SG_ 384 DISCSRF 255;
BA_ "GenSigStartValue" SG_ 384 DISCSRR 255;
BA_ "GenSigSendType" SG_ 384 CAMERRVI 3;
BA_ "GenSigSendType" SG_ 384 CAMERRPO 3;
BA_ "GenSigSendType" SG_ 522 LTASSWEX 3;
BA_ "GenSigSendType" SG_ 522 LTASSWST 3;
BA_ "GenSigSendType" SG_ 522 ADINITEX 3;
BA_ "GenSigSendType" SG_ 522 ADSAFEEX 3;
BA_ "GenSigSendType" SG_ 522 ADALOFEX 3;
BA_ "GenSigSendType" SG_ 522 ADMUTEEX 3;
BA_ "GenSigSendType" SG_ 522 ADMDSTEX 3;
BA_ "GenSigSendType" SG_ 522 HMIAMBEX 3;
BA_ "GenSigSendType" SG_ 522 HMIAMBMD 3;
BA_ "GenSigSendType" SG_ 522 R_CROP_1 3;
BA_ "GenSigSendType" SG_ 522 MD_PRE 3;
BA_ "GenSigSendType" SG_ 522 MD_AVL 3;
BA_ "GenSigSendType" SG_ 522 PVM_SPER 3;
BA_ "GenSigSendType" SG_ 522 ACCCUSST 3;
BA_ "GenSigSendType" SG_ 522 PDACUSST 3;
BA_ "GenSigSendType" SG_ 522 LCACUSST 3;
BA_ "GenSigSendType" SG_ 522 TRACUSST 3;
BA_ "GenSigSendType" SG_ 522 ADCUSST 3;
BA_ "GenSigSendType" SG_ 522 ISACUSST 3;
BA_ "GenSigSendType" SG_ 522 LDACUSST 3;
BA_ "GenSigSendType" SG_ 522 PCSCUSST 3;
BA_ "GenSigSendType" SG_ 522 FTACUSST 3;
BA_ "GenSigSendType" SG_ 522 BSMCUSST 3;
BA_ "GenSigSendType" SG_ 522 SEACUSST 3;
BA_ "GenSigSendType" SG_ 522 CSRCUSST 3;
BA_ "GenSigSendType" SG_ 522 PSBCUSST 3;
BA_ "GenSigSendType" SG_ 522 RTACUSST 3;
BA_ "GenSigSendType" SG_ 522 RCDCUSST 3;
BA_ "GenSigSendType" SG_ 522 SASCUSST 3;
BA_ "GenSigSendType" SG_ 522 RSACUSST 3;
BA_ "GenSigSendType" SG_ 522 RVACUSST 3;
BA_ "GenSigSendType" SG_ 522 AVSCUSST 3;
BA_ "GenSigSendType" SG_ 522 TMNCUSST 3;
BA_ "GenSigSendType" SG_ 522 DMSCUSST 3;
BA_ "GenSigSendType" SG_ 522 SWSCUSST 3;
BA_ "GenSigSendType" SG_ 522 LTACUSST 3;
BA_ "GenSigSendType" SG_ 522 USMSENST 3;
BA_ "GenSigSendType" SG_ 522 SDGCUSEX 3;
BA_ "GenSigSendType" SG_ 522 SDGSENST 3;
BA_ "GenSigSendType" SG_ 522 DRADCTYP 3;
BA_ "GenSigSendType" SG_ 522 ADVNRQ 3;
BA_ "GenSigSendType" SG_ 522 ADVNUSG 3;
BA_ "GenSigSendType" SG_ 522 HMIAMBRQ 3;
BA_ "GenSigSendType" SG_ 522 USMEXST2 3;
BA_ "GenSigSendType" SG_ 522 AECOBNFB 3;
BA_ "GenSigSendType" SG_ 522 AECOBNFV 3;
BA_ "GenSigSendType" SG_ 522 AECOSTBB 3;
BA_ "GenSigSendType" SG_ 522 ADINITST 3;
BA_ "GenSigSendType" SG_ 522 ADSAFEST 3;
BA_ "GenSigSendType" SG_ 522 ADALOFST 3;
BA_ "GenSigSendType" SG_ 522 ADMUTEST 3;
BA_ "GenSigSendType" SG_ 522 ADMDSTST 3;
BA_ "GenSigSendType" SG_ 1555 USMDISP 3;
BA_ "GenSigSendType" SG_ 1555 USMMNAV 3;
BA_ "GenSigSendType" SG_ 1555 USMAC5 3;
BA_ "GenSigSendType" SG_ 1555 USMAC6 3;
BA_ "GenSigSendType" SG_ 1555 USMAC7 3;
BA_ "GenSigSendType" SG_ 1555 USMGSS 3;
BA_ "GenSigSendType" SG_ 1555 USMIDOF 3;
BA_ "GenSigSendType" SG_ 1555 USMIDST 3;
BA_ "GenSigSendType" SG_ 1555 USMISTR 3;
BA_ "GenSigSendType" SG_ 1555 USMSST 3;
BA_ "GenSigSendType" SG_ 324 WS_VD_R 3;
BA_ "GenSigSendType" SG_ 324 WS_FTG_R 3;
BA_ "GenSigSendType" SG_ 324 WS_ABH_R 3;
BA_ "GenSigSendType" SG_ 324 WS_APO_R 3;
BA_ "GenSigSendType" SG_ 583 DTG15 3;
BA_ "GenSigSendType" SG_ 583 DTG16 3;
BA_ "GenSigSendType" SG_ 583 DTG18_04 3;
BA_ "GenSigSendType" SG_ 583 DTG18_05 3;
BA_ "GenSigSendType" SG_ 583 DTG19 3;
BA_ "GenSigSendType" SG_ 583 DTG20_02 3;
BA_ "GenSigSendType" SG_ 583 DTG20_03 3;
BA_ "GenSigSendType" SG_ 583 DTG23 3;
BA_ "GenSigSendType" SG_ 583 DTG25 3;
BA_ "GenSigSendType" SG_ 583 DTG27 3;
BA_ "GenSigSendType" SG_ 583 DTG30 3;
BA_ "GenSigSendType" SG_ 583 DTG34 3;
BA_ "GenSigSendType" SG_ 501 ACCMMOD 3;
BA_ "GenSigSendType" SG_ 558 LDASTATL 3;
BA_ "GenSigSendType" SG_ 558 LDASTATR 3;
BA_ "GenSigSendType" SG_ 558 LDARSN 3;
BA_ "GenSigSendType" SG_ 558 LDARCGL 3;
BA_ "GenSigSendType" SG_ 558 LDARCGR 3;
BA_ "GenSigSendType" SG_ 558 SWSSTAT 3;
BA_ "GenSigSendType" SG_ 558 EJLDACP 3;
BA_ "GenSigSendType" SG_ 558 DM_PVMVW 3;
BA_ "GenSigSendType" SG_ 558 DM_PVMCS 3;
BA_ "GenSigStartValue" SG_ 558 GAE_H_R3 127;
BA_ "GenSigStartValue" SG_ 558 GAE_V_R1 15;
BA_ "GenSigStartValue" SG_ 558 MDSYNC00 31;
BA_ "GenSigSendType" SG_ 353 MDCTRGID 3;
BA_ "GenSigStartValue" SG_ 353 CAMTYPE 7;
BA_ "GenSigSendType" SG_ 353 CAMTYPE 3;
BA_ "GenSigSendType" SG_ 353 CAMPOS_X 3;
BA_ "GenSigSendType" SG_ 353 CAMPOS_Y 3;
BA_ "GenSigSendType" SG_ 353 CAMPOS_Z 3;
BA_ "GenSigSendType" SG_ 353 CAMROT_X 3;
BA_ "GenSigSendType" SG_ 353 CAMROT_Y 3;
BA_ "GenSigSendType" SG_ 353 CAMROT_Z 3;
BA_ "GenSigSendType" SG_ 353 CAMFOC_X 3;
BA_ "GenSigSendType" SG_ 353 CAMFOC_Y 3;
BA_ "GenSigSendType" SG_ 353 CAMDTC_1 3;
BA_ "GenSigSendType" SG_ 353 CAMDTC_2 3;
BA_ "GenSigSendType" SG_ 353 CAMDTC_3 3;
BA_ "GenSigSendType" SG_ 353 CAM_C_X 3;
BA_ "GenSigSendType" SG_ 353 CAM_C_Y 3;
BA_ "GenSigStartValue" SG_ 354 MDSYNC01 31;
BA_ "GenSigStartValue" SG_ 355 MDSYNC02 31;
BA_ "GenSigStartValue" SG_ 358 MDSYNC03 31;
BA_ "GenSigStartValue" SG_ 359 MDACCDST 7;
BA_ "GenSigStartValue" SG_ 359 MDSYNC04 31;
BA_ "GenSigStartValue" SG_ 359 MDTRPCNT 65535;
BA_ "GenSigStartValue" SG_ 359 MDTMCNT 4294967295;
BA_ "GenSigStartValue" SG_ 359 MDEGOVEL -32768;
BA_ "GenSigStartValue" SG_ 359 MDEGOGX -32768;
BA_ "GenSigStartValue" SG_ 359 MDEGOGY -32768;
BA_ "GenSigStartValue" SG_ 359 MDEGOASZ -32768;
BA_ "GenSigStartValue" SG_ 359 MDADSST 4294967295;
BA_ "GenSigStartValue" SG_ 359 MDADSSW 1048575;
BA_ "GenSigStartValue" SG_ 359 MDSFTPS 15;
BA_ "GenSigStartValue" SG_ 359 MDDRVMD 7;
BA_ "GenSigStartValue" SG_ 359 MDEGOLCS 3;
BA_ "GenSigStartValue" SG_ 359 MDDRVTSW 7;
BA_ "GenSigStartValue" SG_ 359 MDACCSPD 255;
BA_ "GenSigStartValue" SG_ 359 MDEGOAOP 255;
BA_ "GenSigStartValue" SG_ 359 MDEGOBRK 255;
BA_ "GenSigStartValue" SG_ 359 MDEGOANG -32768;
BA_ "GenSigStartValue" SG_ 359 MDDRVACC 255;
BA_ "GenSigStartValue" SG_ 359 MDDRVBRK 255;
BA_ "GenSigStartValue" SG_ 359 MDDRVSTR 255;
BA_ "GenSigStartValue" SG_ 359 MDDRVTCH 3;
BA_ "GenSigStartValue" SG_ 359 MDTRNL 3;
BA_ "GenSigStartValue" SG_ 359 MDHZDL 3;
BA_ "GenSigStartValue" SG_ 359 MDBRKL 3;
BA_ "GenSigStartValue" SG_ 360 MDSYNC05 31;
BA_ "GenSigStartValue" SG_ 361 MDSYNC06 31;
BA_ "GenSigStartValue" SG_ 362 MDSYNC07 31;
BA_ "GenSigStartValue" SG_ 363 MDSYNC08 31;
BA_ "GenSigStartValue" SG_ 364 MDSYNC09 31;
BA_ "GenSigStartValue" SG_ 365 MDSYNC10 31;
BA_ "GenSigStartValue" SG_ 114 ARANGINV 1;
BA_ "GenSigStartValue" SG_ 114 ARSANG 8192;
BA_ "GenSigSendType" SG_ 902 ANS 3;
BA_ "GenSigSendType" SG_ 902 FLYNOP 3;
BA_ "GenSigSendType" SG_ 902 FLGPSOP 3;
BA_ "GenSigSendType" SG_ 902 FLADELOP 3;
BA_ "GenSigSendType" SG_ 902 CRS1 3;
BA_ "GenSigSendType" SG_ 902 RQAC 3;
BA_ "GenSigSendType" SG_ 902 GUID 3;
BA_ "GenSigSendType" SG_ 902 GYRO 3;
BA_ "GenSigSendType" SG_ 902 NCRN 3;
BA_ "GenSigSendType" SG_ 902 CRN6 3;
BA_ "GenSigSendType" SG_ 902 CRN5 3;
BA_ "GenSigSendType" SG_ 902 CRN3 3;
BA_ "GenSigSendType" SG_ 902 CRN2 3;
BA_ "GenSigSendType" SG_ 902 CRN1 3;
BA_ "GenSigSendType" SG_ 902 CONFID03 3;
BA_ "GenSigSendType" SG_ 902 CURV 3;
BA_ "GenSigSendType" SG_ 902 CVST 3;
BA_ "GenSigStartValue" SG_ 902 NAVI_STR 1;
BA_ "GenSigSendType" SG_ 902 NAVI_STR 3;
BA_ "GenSigStartValue" SG_ 902 MIND 1;
BA_ "GenSigSendType" SG_ 902 MIND 3;
BA_ "GenSigStartValue" SG_ 902 ONOFF 1;
BA_ "GenSigSendType" SG_ 902 ONOFF 3;
BA_ "GenSigSendType" SG_ 902 HWPB 3;
BA_ "GenSigSendType" SG_ 902 RAD 3;
BA_ "GenSigSendType" SG_ 902 USMANS 3;
BA_ "GenSigSendType" SG_ 902 SLJ 3;
BA_ "GenSigSendType" SG_ 902 SLUS 3;
BA_ "GenSigStartValue" SG_ 902 AFS_SW 1;
BA_ "GenSigSendType" SG_ 902 AFS_SW 3;
BA_ "GenSigStartValue" SG_ 902 AVS_SW 1;
BA_ "GenSigSendType" SG_ 902 AVS_SW 3;
BA_ "GenSigSendType" SG_ 905 BZ_M_SW 3;
BA_ "GenSigSendType" SG_ 905 CS_R_SW 3;
BA_ "GenSigSendType" SG_ 905 BM 3;
BA_ "GenSigSendType" SG_ 905 SUR_STAT 3;
BA_ "GenSigStartValue" SG_ 905 NOP_P 63;
BA_ "GenSigStartValue" SG_ 905 NOP_CI 31;
BA_ "GenSigStartValue" SG_ 905 NOP_S1 63;
BA_ "GenSigStartValue" SG_ 905 NOP_S2 63;
BA_ "GenSigStartValue" SG_ 905 NOP_S3 63;
BA_ "GenSigStartValue" SG_ 905 NOP_S4 63;
BA_ "GenSigStartValue" SG_ 905 NOP_S5 63;
BA_ "GenSigStartValue" SG_ 905 NOP_S6 63;
BA_ "GenSigStartValue" SG_ 510 RMNDIST 63;
BA_ "GenSigSendType" SG_ 934 LANENUM 3;
BA_ "GenSigStartValue" SG_ 934 CVR1 2049;
BA_ "GenSigSendType" SG_ 934 CVR1 3;
BA_ "GenSigStartValue" SG_ 934 CVR2 2049;
BA_ "GenSigSendType" SG_ 934 CVR2 3;
BA_ "GenSigSendType" SG_ 934 LVMAIN 3;
BA_ "GenSigStartValue" SG_ 934 CVR3 2049;
BA_ "GenSigSendType" SG_ 934 CVR3 3;
BA_ "GenSigStartValue" SG_ 934 CVR4 2049;
BA_ "GenSigSendType" SG_ 934 CVR4 3;
BA_ "GenSigSendType" SG_ 935 MLID 3;
BA_ "GenSigSendType" SG_ 935 MLDIR 3;
BA_ "GenSigStartValue" SG_ 935 MLDT1 1023;
BA_ "GenSigSendType" SG_ 935 MLDT1 3;
BA_ "GenSigSendType" SG_ 935 MLCT 3;
BA_ "GenSigSendType" SG_ 935 MLTDIR 3;
BA_ "GenSigStartValue" SG_ 935 MLDT2 1023;
BA_ "GenSigSendType" SG_ 935 MLDT2 3;
BA_ "GenSigSendType" SG_ 935 MLLNUM 3;
BA_ "GenSigSendType" SG_ 935 RAHRNUM 3;
BA_ "GenSigSendType" SG_ 935 VRAHRDST 3;
BA_ "GenSigSendType" SG_ 935 MLPTN 3;
BA_ "GenSigStartValue" SG_ 935 LANEPOS 255;
BA_ "GenSigSendType" SG_ 935 LANEPOS 3;
BA_ "GenSigStartValue" SG_ 846 CLE_RNG 65534;
BA_ "GenSigStartValue" SG_ 846 CLE_SOCT 254;
BA_ "GenSigSendType" SG_ 783 B2_FUNID 3;
BA_ "GenSigSendType" SG_ 783 B2_INST1 3;
BA_ "GenSigSendType" SG_ 783 B2_INST2 3;
BA_ "GenSigSendType" SG_ 783 B2_INST3 3;
BA_ "GenSigSendType" SG_ 783 B2_INST4 3;
BA_ "GenSigSendType" SG_ 783 B2_INST5 3;
BA_ "GenSigSendType" SG_ 783 B2_INST6 3;
BA_ "GenSigSendType" SG_ 783 B2_INST7 3;
BA_ "GenSigSendType" SG_ 936 DSTEXIT 3;
BA_ "GenSigSendType" SG_ 936 TSSRNCFG 3;
BA_ "GenSigSendType" SG_ 936 DSTRNCP 3;
BA_ "GenSigSendType" SG_ 936 AVNCBFLG 3;
BA_ "GenSigSendType" SG_ 936 OTHUNRCV 3;
BA_ "GenSigSendType" SG_ 936 TSSLNNUM 3;
BA_ "GenSigSendType" SG_ 936 TSSMLDIR 3;
BA_ "GenSigSendType" SG_ 976 PLGFUNID 3;
BA_ "GenSigSendType" SG_ 976 PLGINST1 3;
BA_ "GenSigSendType" SG_ 976 PLGINST2 3;
BA_ "GenSigSendType" SG_ 976 PLGINST3 3;
BA_ "GenSigSendType" SG_ 976 PLGINST4 3;
BA_ "GenSigSendType" SG_ 976 PLGINST5 3;
BA_ "GenSigSendType" SG_ 976 PLGINST6 3;
BA_ "GenSigSendType" SG_ 976 PLGINST7 3;
BA_ "GenSigSendType" SG_ 1021 PT_FUNID 3;
BA_ "GenSigSendType" SG_ 1021 PT_INST1 3;
BA_ "GenSigSendType" SG_ 1021 PT_INST2 3;
BA_ "GenSigSendType" SG_ 1021 PT_INST3 3;
BA_ "GenSigSendType" SG_ 1021 PT_INST4 3;
BA_ "GenSigSendType" SG_ 1021 PT_INST5 3;
BA_ "GenSigSendType" SG_ 1021 PT_INST6 3;
BA_ "GenSigSendType" SG_ 1021 PT_INST7 3;
BA_ "GenSigSendType" SG_ 964 DS_FUNID 3;
BA_ "GenSigSendType" SG_ 964 DS_INST1 3;
BA_ "GenSigSendType" SG_ 964 DS_INST2 3;
BA_ "GenSigSendType" SG_ 964 DS_INST3 3;
BA_ "GenSigSendType" SG_ 964 DS_INST4 3;
BA_ "GenSigSendType" SG_ 964 DS_INST5 3;
BA_ "GenSigSendType" SG_ 964 DS_INST6 3;
BA_ "GenSigSendType" SG_ 964 DS_INST7 3;
BA_ "GenSigSendType" SG_ 797 CSDESSET 3;
BA_ "GenSigSendType" SG_ 797 BPRQSW 3;
BA_ "GenSigSendType" SG_ 797 BPNAVI 3;
BA_ "GenSigSendType" SG_ 962 RPSNO1_A 3;
BA_ "GenSigSendType" SG_ 962 RPSNO2_A 3;
BA_ "GenSigSendType" SG_ 962 RPEPS1 3;
BA_ "GenSigSendType" SG_ 962 RPEPS2 3;
BA_ "GenSigSendType" SG_ 962 RPEPS3 3;
BA_ "GenSigSendType" SG_ 962 RPEPS4 3;
BA_ "GenSigSendType" SG_ 962 RPCRO1 3;
BA_ "GenSigSendType" SG_ 962 RPCRO2 3;
BA_ "GenSigSendType" SG_ 962 RPCRO3 3;
BA_ "GenSigSendType" SG_ 962 RPCRO4 3;
BA_ "GenSigSendType" SG_ 962 RPCTIM1 3;
BA_ "GenSigSendType" SG_ 962 RPCTIM2 3;
BA_ "GenSigSendType" SG_ 962 RPCTIM3 3;
BA_ "GenSigSendType" SG_ 962 RPCTIM4 3;
BA_ "GenSigSendType" SG_ 1038 TTLFRAM 3;
BA_ "GenSigStartValue" SG_ 1038 FRAMID0 255;
BA_ "GenSigSendType" SG_ 1038 FRAMID0 3;
BA_ "GenSigStartValue" SG_ 1038 FORMID 255;
BA_ "GenSigSendType" SG_ 1038 FORMID 3;
BA_ "GenSigSendType" SG_ 1038 X_DATAID 3;
BA_ "GenSigSendType" SG_ 1038 X_TYPE 3;
BA_ "GenSigSendType" SG_ 1038 PADDINGX 3;
BA_ "GenSigSendType" SG_ 1038 X_DELAY 3;
BA_ "GenSigSendType" SG_ 1038 Y_DATAID 3;
BA_ "GenSigSendType" SG_ 1038 Y_TYPE 3;
BA_ "GenSigSendType" SG_ 1038 PADDINGY 3;
BA_ "GenSigSendType" SG_ 1038 Y_DELAY 3;
BA_ "GenSigSendType" SG_ 1038 PREPROC 3;
BA_ "GenSigSendType" SG_ 1038 COMPOPE 3;
BA_ "GenSigSendType" SG_ 1038 Y_CONST 3;
BA_ "GenSigSendType" SG_ 1038 COMPVAL 3;
BA_ "GenSigStartValue" SG_ 1038 FORMID_A 255;
BA_ "GenSigSendType" SG_ 1038 FORMID_A 3;
BA_ "GenSigStartValue" SG_ 1038 FORMID_B 255;
BA_ "GenSigSendType" SG_ 1038 FORMID_B 3;
BA_ "GenSigSendType" SG_ 1038 LOGIOPE 3;
BA_ "GenSigSendType" SG_ 1038 MAXTRG 3;
BA_ "GenSigStartValue" SG_ 1038 FORMID_C 255;
BA_ "GenSigSendType" SG_ 1038 FORMID_C 3;
BA_ "GenSigSendType" SG_ 1038 PADDING1 3;
BA_ "GenSigStartValue" SG_ 1038 MDCREQID 255;
BA_ "GenSigSendType" SG_ 1038 MDCREQID 3;
BA_ "GenSigSendType" SG_ 1038 FORMID_D 3;
BA_ "GenSigSendType" SG_ 1038 GRDDIST 3;
BA_ "GenSigSendType" SG_ 1038 GRDTIME 3;
BA_ "GenSigSendType" SG_ 1306 TCIN_ID 3;
BA_ "GenSigSendType" SG_ 1306 TCIN_TTP 3;
BA_ "GenSigSendType" SG_ 1306 TCIN_AC 3;
BA_ "GenSigSendType" SG_ 1306 TCIN_HTP 3;
BA_ "GenSigSendType" SG_ 1306 TCIN_LM 3;
BA_ "GenSigSendType" SG_ 1306 TCIN_NAX 3;
BA_ "GenSigSendType" SG_ 1306 TCIN_BTP 3;
BA_ "GenSigSendType" SG_ 1306 TCIN_HLM 3;
BA_ "GenSigSendType" SG_ 1306 TCIN_L 3;
BA_ "GenSigSendType" SG_ 1306 TCIN_HL 3;
BA_ "GenSigSendType" SG_ 1306 TCIN_WB 3;
BA_ "GenSigSendType" SG_ 1306 TCIN_W 3;
BA_ "GenSigSendType" SG_ 1306 TCIN_WBM 3;
BA_ "GenSigSendType" SG_ 1306 TCIN_WM 3;
BA_ "GenSigSendType" SG_ 1306 TCIN_TWM 3;
BA_ "GenSigSendType" SG_ 1306 TCIN_TW 3;
BA_ "GenSigSendType" SG_ 1306 TCIN_MI 3;
BA_ "GenSigSendType" SG_ 1307 TCIN_TN 3;
BA_ "GenSigStartValue" SG_ 1010 BEV_RNG 65534;
BA_ "GenSigStartValue" SG_ 1010 BEV_TIME 65534;
BA_ "GenSigSendType" SG_ 723 GDPC_SW1 3;
BA_ "GenSigSendType" SG_ 723 GDPC_SW2 3;
BA_ "GenSigSendType" SG_ 723 GDPC_SW3 3;
BA_ "GenSigSendType" SG_ 723 GDPC_SW4 3;
BA_ "GenSigSendType" SG_ 723 GDPC_SW5 3;
BA_ "GenSigSendType" SG_ 723 GDPC_SW6 3;
BA_ "GenSigSendType" SG_ 723 GDPC_SW7 3;
BA_ "GenSigSendType" SG_ 723 GDPC_SW8 3;
BA_ "GenSigSendType" SG_ 723 GDPAVN_D 3;
